VERSION ""

NS_ :

BS_:

BU_: Gen AF01A
VAL_TABLE_ FUNCTION_SWITCH 1 "close" 0 "open" ;
VAL_TABLE_ Status_Bottom_HLB 3 "Invalid signal" 2 "defined by oncoming vehicle" 1 "defined by preceding vehicle" 0 "No object detected" ;

BO_ 3221225472 VECTOR__INDEPENDENT_SIG_MSG: 0 Vector__XXX
 SG_ CAN_TX_ACTIVE_FAULT_3 : 0|8@0+ (1,0) [0|0] "" Vector__XXX
 SG_ New_Signal_1961 : 0|8@1+ (1,0) [0|0] "" Vector__XXX
 SG_ CAN_TX_TRACK_WIDTH : 0|8@1- (1,0) [0|0] "" Vector__XXX
 SG_ CAN_TX_TRACK_WIDTH : 0|8@1- (1,0) [0|0] "" Vector__XXX
 SG_ CAN_TX_TRACK_WIDTH : 0|8@1- (1,0) [0|0] "" Vector__XXX
 SG_ CAN_TX_TRACK_WIDTH : 0|8@1- (1,0) [0|0] "" Vector__XXX
 SG_ CAN_TX_TRACK_WIDTH : 0|8@1- (1,0) [0|0] "" Vector__XXX
 SG_ CAN_TX_TRACK_WIDTH : 0|8@1- (1,0) [0|0] "" Vector__XXX
 SG_ CAN_TX_TRACK_WIDTH : 0|8@1- (1,0) [0|0] "" Vector__XXX
 SG_ CAN_TX_TRACK_WIDTH : 0|8@1- (1,0) [0|0] "" Vector__XXX
 SG_ CAN_TX_TRACK_STATUS : 0|8@1- (1,0) [0|0] "" Vector__XXX
 SG_ CAN_TX_TRACK_STATUS : 0|8@1- (1,0) [0|0] "" Vector__XXX
 SG_ CAN_TX_TRACK_STATUS : 0|8@1- (1,0) [0|0] "" Vector__XXX
 SG_ CAN_TX_TRACK_STATUS : 0|8@1- (1,0) [0|0] "" Vector__XXX
 SG_ CAN_TX_TRACK_STATUS : 0|8@1- (1,0) [0|0] "" Vector__XXX
 SG_ New_Signal_1655 : 0|8@1+ (1,0) [0|0] "" Vector__XXX
 SG_ CAN_TX_TRACK_ROLLING_COUNT : 0|8@1- (1,0) [0|0] "" Vector__XXX
 SG_ CAN_TX_TRACK_ROLLING_COUNT : 0|8@1- (1,0) [0|0] "" Vector__XXX
 SG_ CAN_TX_TRACK_ROLLING_COUNT : 0|8@1- (1,0) [0|0] "" Vector__XXX
 SG_ CAN_TX_TRACK_ROLLING_COUNT : 0|8@1- (1,0) [0|0] "" Vector__XXX
 SG_ CAN_TX_TRACK_ROLLING_COUNT : 0|8@1- (1,0) [0|0] "" Vector__XXX
 SG_ CAN_TX_TRACK_ROLLING_COUNT : 0|8@1- (1,0) [0|0] "" Vector__XXX
 SG_ CAN_TX_TRACK_ROLLING_COUNT : 0|8@1- (1,0) [0|0] "" Vector__XXX
 SG_ CAN_TX_TRACK_ROLLING_COUNT : 0|8@1- (1,0) [0|0] "" Vector__XXX
 SG_ CAN_TX_TRACK_ROLLING_COUNT : 0|8@1- (1,0) [0|0] "" Vector__XXX
 SG_ CAN_TX_TRACK_ROLLING_COUNT : 0|8@1- (1,0) [0|0] "" Vector__XXX
 SG_ CAN_TX_TRACK_ROLLING_COUNT : 0|8@1- (1,0) [0|0] "" Vector__XXX
 SG_ New_Signal_1548 : 0|8@1+ (1,0) [0|0] "" Vector__XXX
 SG_ New_Signal_1513 : 0|8@1- (1,0) [0|0] "" Vector__XXX
 SG_ New_Signal_1502 : 0|8@1+ (1,0) [0|0] "" Vector__XXX
 SG_ CAN_TX_TRACK_RANGE_RATE : 0|8@1- (1,0) [0|0] "" Vector__XXX
 SG_ CAN_TX_TRACK_RANGE_RATE : 0|8@1- (1,0) [0|0] "" Vector__XXX
 SG_ CAN_TX_TRACK_RANGE_RATE : 0|8@1- (1,0) [0|0] "" Vector__XXX
 SG_ CAN_TX_TRACK_RANGE_RATE : 0|8@1- (1,0) [0|0] "" Vector__XXX
 SG_ CAN_TX_TRACK_RANGE_ACCEL : 0|8@1- (1,0) [0|0] "" Vector__XXX
 SG_ New_Signal_1353 : 0|8@1- (1,0) [0|0] "" Vector__XXX
 SG_ CAN_TX_TRACK_RANGE_ACCEL : 0|8@1- (1,0) [0|0] "" Vector__XXX
 SG_ CAN_TX_TRACK_RANGE_ACCEL : 0|8@1- (1,0) [0|0] "" Vector__XXX
 SG_ CAN_TX_TRACK_RANGE_ACCEL : 0|8@1- (1,0) [0|0] "" Vector__XXX
 SG_ CAN_TX_TRACK_RANGE_ACCEL : 0|8@1- (1,0) [0|0] "" Vector__XXX
 SG_ CAN_TX_TRACK_RANGE : 0|8@1- (1,0) [0|0] "" Vector__XXX
 SG_ CAN_TX_TRACK_RANGE : 0|8@1- (1,0) [0|0] "" Vector__XXX
 SG_ CAN_TX_TRACK_RANGE : 0|8@1- (1,0) [0|0] "" Vector__XXX
 SG_ CAN_TX_TRACK_RANGE : 0|8@1- (1,0) [0|0] "" Vector__XXX
 SG_ New_Signal_1169 : 0|8@1+ (1,0) [0|0] "" Vector__XXX
 SG_ New_Signal_1161 : 0|8@1+ (1,0) [0|0] "" Vector__XXX
 SG_ CAN_TX_TRACK_ONCOMING : 0|8@1- (1,0) [0|0] "" Vector__XXX
 SG_ New_Signal_1037 : 0|8@1+ (1,0) [0|0] "" Vector__XXX
 SG_ New_Signal_1023 : 0|8@1+ (1,0) [0|0] "" Vector__XXX
 SG_ New_Signal_1013 : 0|8@1+ (1,0) [0|0] "" Vector__XXX
 SG_ CAN_TX_TRACK_MED_RANGE_MODE : 0|8@1- (1,0) [0|0] "" Vector__XXX
 SG_ CAN_TX_TRACK_MED_RANGE_MODE : 0|8@1- (1,0) [0|0] "" Vector__XXX
 SG_ New_Signal_792 : 0|8@1+ (1,0) [0|0] "" Vector__XXX
 SG_ New_Signal_791 : 0|8@1+ (1,0) [0|0] "" Vector__XXX
 SG_ New_Signal_790 : 0|8@1+ (1,0) [0|0] "" Vector__XXX
 SG_ New_Signal_789 : 0|8@1+ (1,0) [0|0] "" Vector__XXX
 SG_ New_Signal_788 : 0|8@1+ (1,0) [0|0] "" Vector__XXX
 SG_ New_Signal_787 : 0|8@1+ (1,0) [0|0] "" Vector__XXX
 SG_ New_Signal_786 : 0|8@1+ (1,0) [0|0] "" Vector__XXX
 SG_ New_Signal_785 : 0|8@1+ (1,0) [0|0] "" Vector__XXX
 SG_ New_Signal_784 : 0|8@1+ (1,0) [0|0] "" Vector__XXX
 SG_ New_Signal_783 : 0|8@1+ (1,0) [0|0] "" Vector__XXX
 SG_ New_Signal_782 : 0|8@1+ (1,0) [0|0] "" Vector__XXX
 SG_ New_Signal_781 : 0|8@1+ (1,0) [0|0] "" Vector__XXX
 SG_ New_Signal_780 : 0|8@1+ (1,0) [0|0] "" Vector__XXX
 SG_ New_Signal_779 : 0|8@1+ (1,0) [0|0] "" Vector__XXX
 SG_ New_Signal_778 : 0|8@1+ (1,0) [0|0] "" Vector__XXX
 SG_ New_Signal_777 : 0|8@1+ (1,0) [0|0] "" Vector__XXX
 SG_ New_Signal_776 : 0|8@1+ (1,0) [0|0] "" Vector__XXX
 SG_ New_Signal_775 : 0|8@1+ (1,0) [0|0] "" Vector__XXX
 SG_ New_Signal_774 : 0|8@1+ (1,0) [0|0] "" Vector__XXX
 SG_ New_Signal_773 : 0|8@1+ (1,0) [0|0] "" Vector__XXX
 SG_ New_Signal_772 : 0|8@1+ (1,0) [0|0] "" Vector__XXX
 SG_ New_Signal_771 : 0|8@1+ (1,0) [0|0] "" Vector__XXX
 SG_ New_Signal_770 : 0|8@1+ (1,0) [0|0] "" Vector__XXX
 SG_ New_Signal_769 : 0|8@1+ (1,0) [0|0] "" Vector__XXX
 SG_ New_Signal_768 : 0|8@1+ (1,0) [0|0] "" Vector__XXX
 SG_ New_Signal_767 : 0|8@1+ (1,0) [0|0] "" Vector__XXX
 SG_ New_Signal_766 : 0|8@1+ (1,0) [0|0] "" Vector__XXX
 SG_ New_Signal_765 : 0|8@1+ (1,0) [0|0] "" Vector__XXX
 SG_ New_Signal_764 : 0|8@1+ (1,0) [0|0] "" Vector__XXX
 SG_ New_Signal_763 : 0|8@1+ (1,0) [0|0] "" Vector__XXX
 SG_ New_Signal_762 : 0|8@1+ (1,0) [0|0] "" Vector__XXX
 SG_ New_Signal_761 : 0|8@1+ (1,0) [0|0] "" Vector__XXX
 SG_ New_Signal_760 : 0|8@1+ (1,0) [0|0] "" Vector__XXX
 SG_ New_Signal_759 : 0|8@1+ (1,0) [0|0] "" Vector__XXX
 SG_ New_Signal_758 : 0|8@1+ (1,0) [0|0] "" Vector__XXX
 SG_ New_Signal_757 : 0|8@1+ (1,0) [0|0] "" Vector__XXX
 SG_ New_Signal_756 : 0|8@1+ (1,0) [0|0] "" Vector__XXX
 SG_ New_Signal_755 : 0|8@1+ (1,0) [0|0] "" Vector__XXX
 SG_ New_Signal_754 : 0|8@1+ (1,0) [0|0] "" Vector__XXX
 SG_ New_Signal_753 : 0|8@1+ (1,0) [0|0] "" Vector__XXX
 SG_ New_Signal_752 : 0|8@1+ (1,0) [0|0] "" Vector__XXX
 SG_ New_Signal_751 : 0|8@1+ (1,0) [0|0] "" Vector__XXX
 SG_ New_Signal_750 : 0|8@1+ (1,0) [0|0] "" Vector__XXX
 SG_ New_Signal_749 : 0|8@1+ (1,0) [0|0] "" Vector__XXX
 SG_ New_Signal_748 : 0|8@1+ (1,0) [0|0] "" Vector__XXX
 SG_ New_Signal_747 : 0|8@1+ (1,0) [0|0] "" Vector__XXX
 SG_ New_Signal_746 : 0|8@1+ (1,0) [0|0] "" Vector__XXX
 SG_ New_Signal_745 : 0|8@1+ (1,0) [0|0] "" Vector__XXX
 SG_ New_Signal_744 : 0|8@1+ (1,0) [0|0] "" Vector__XXX
 SG_ New_Signal_743 : 0|8@1+ (1,0) [0|0] "" Vector__XXX
 SG_ New_Signal_742 : 0|8@1+ (1,0) [0|0] "" Vector__XXX
 SG_ New_Signal_741 : 0|8@1+ (1,0) [0|0] "" Vector__XXX
 SG_ New_Signal_740 : 0|8@1+ (1,0) [0|0] "" Vector__XXX
 SG_ New_Signal_739 : 0|8@1+ (1,0) [0|0] "" Vector__XXX
 SG_ New_Signal_738 : 0|8@1+ (1,0) [0|0] "" Vector__XXX
 SG_ New_Signal_737 : 0|8@1+ (1,0) [0|0] "" Vector__XXX
 SG_ New_Signal_736 : 0|8@1+ (1,0) [0|0] "" Vector__XXX
 SG_ New_Signal_735 : 0|8@1+ (1,0) [0|0] "" Vector__XXX
 SG_ New_Signal_734 : 0|8@1+ (1,0) [0|0] "" Vector__XXX
 SG_ New_Signal_733 : 0|8@1+ (1,0) [0|0] "" Vector__XXX
 SG_ New_Signal_732 : 0|8@1+ (1,0) [0|0] "" Vector__XXX
 SG_ New_Signal_731 : 0|8@1+ (1,0) [0|0] "" Vector__XXX
 SG_ New_Signal_730 : 0|8@1+ (1,0) [0|0] "" Vector__XXX
 SG_ New_Signal_729 : 0|8@1+ (1,0) [0|0] "" Vector__XXX
 SG_ CAN_TX_TRACK_GROUPING_CHANGED : 0|8@1- (1,0) [0|0] "" Vector__XXX
 SG_ New_Signal_663 : 0|8@1+ (1,0) [0|0] "" Vector__XXX
 SG_ New_Signal_662 : 0|8@1+ (1,0) [0|0] "" Vector__XXX
 SG_ New_Signal_661 : 0|8@1+ (1,0) [0|0] "" Vector__XXX
 SG_ New_Signal_660 : 0|8@1+ (1,0) [0|0] "" Vector__XXX
 SG_ New_Signal_659 : 0|8@1+ (1,0) [0|0] "" Vector__XXX
 SG_ New_Signal_658 : 0|8@1+ (1,0) [0|0] "" Vector__XXX
 SG_ New_Signal_657 : 0|8@1+ (1,0) [0|0] "" Vector__XXX
 SG_ New_Signal_656 : 0|8@1+ (1,0) [0|0] "" Vector__XXX
 SG_ New_Signal_655 : 0|8@1+ (1,0) [0|0] "" Vector__XXX
 SG_ New_Signal_654 : 0|8@1+ (1,0) [0|0] "" Vector__XXX
 SG_ New_Signal_653 : 0|8@1+ (1,0) [0|0] "" Vector__XXX
 SG_ New_Signal_652 : 0|8@1+ (1,0) [0|0] "" Vector__XXX
 SG_ New_Signal_651 : 0|8@1+ (1,0) [0|0] "" Vector__XXX
 SG_ New_Signal_650 : 0|8@1+ (1,0) [0|0] "" Vector__XXX
 SG_ New_Signal_649 : 0|8@1+ (1,0) [0|0] "" Vector__XXX
 SG_ New_Signal_648 : 0|8@1+ (1,0) [0|0] "" Vector__XXX
 SG_ New_Signal_647 : 0|8@1+ (1,0) [0|0] "" Vector__XXX
 SG_ New_Signal_646 : 0|8@1+ (1,0) [0|0] "" Vector__XXX
 SG_ New_Signal_645 : 0|8@1+ (1,0) [0|0] "" Vector__XXX
 SG_ New_Signal_644 : 0|8@1+ (1,0) [0|0] "" Vector__XXX
 SG_ New_Signal_643 : 0|8@1+ (1,0) [0|0] "" Vector__XXX
 SG_ New_Signal_642 : 0|8@1+ (1,0) [0|0] "" Vector__XXX
 SG_ New_Signal_641 : 0|8@1+ (1,0) [0|0] "" Vector__XXX
 SG_ New_Signal_640 : 0|8@1+ (1,0) [0|0] "" Vector__XXX
 SG_ New_Signal_639 : 0|8@1+ (1,0) [0|0] "" Vector__XXX
 SG_ New_Signal_638 : 0|8@1+ (1,0) [0|0] "" Vector__XXX
 SG_ New_Signal_637 : 0|8@1+ (1,0) [0|0] "" Vector__XXX
 SG_ New_Signal_636 : 0|8@1+ (1,0) [0|0] "" Vector__XXX
 SG_ New_Signal_635 : 0|8@1+ (1,0) [0|0] "" Vector__XXX
 SG_ New_Signal_634 : 0|8@1+ (1,0) [0|0] "" Vector__XXX
 SG_ New_Signal_633 : 0|8@1+ (1,0) [0|0] "" Vector__XXX
 SG_ New_Signal_632 : 0|8@1+ (1,0) [0|0] "" Vector__XXX
 SG_ New_Signal_631 : 0|8@1+ (1,0) [0|0] "" Vector__XXX
 SG_ New_Signal_630 : 0|8@1+ (1,0) [0|0] "" Vector__XXX
 SG_ New_Signal_629 : 0|8@1+ (1,0) [0|0] "" Vector__XXX
 SG_ New_Signal_628 : 0|8@1+ (1,0) [0|0] "" Vector__XXX
 SG_ New_Signal_627 : 0|8@1+ (1,0) [0|0] "" Vector__XXX
 SG_ New_Signal_626 : 0|8@1+ (1,0) [0|0] "" Vector__XXX
 SG_ New_Signal_625 : 0|8@1+ (1,0) [0|0] "" Vector__XXX
 SG_ New_Signal_624 : 0|8@1+ (1,0) [0|0] "" Vector__XXX
 SG_ New_Signal_623 : 0|8@1+ (1,0) [0|0] "" Vector__XXX
 SG_ New_Signal_622 : 0|8@1+ (1,0) [0|0] "" Vector__XXX
 SG_ New_Signal_621 : 0|8@1+ (1,0) [0|0] "" Vector__XXX
 SG_ New_Signal_620 : 0|8@1+ (1,0) [0|0] "" Vector__XXX
 SG_ New_Signal_619 : 0|8@1+ (1,0) [0|0] "" Vector__XXX
 SG_ New_Signal_618 : 0|8@1+ (1,0) [0|0] "" Vector__XXX
 SG_ New_Signal_617 : 0|8@1+ (1,0) [0|0] "" Vector__XXX
 SG_ New_Signal_616 : 0|8@1+ (1,0) [0|0] "" Vector__XXX
 SG_ New_Signal_615 : 0|8@1+ (1,0) [0|0] "" Vector__XXX
 SG_ New_Signal_614 : 0|8@1+ (1,0) [0|0] "" Vector__XXX
 SG_ New_Signal_613 : 0|8@1+ (1,0) [0|0] "" Vector__XXX
 SG_ New_Signal_612 : 0|8@1+ (1,0) [0|0] "" Vector__XXX
 SG_ New_Signal_611 : 0|8@1+ (1,0) [0|0] "" Vector__XXX
 SG_ New_Signal_610 : 0|8@1+ (1,0) [0|0] "" Vector__XXX
 SG_ New_Signal_609 : 0|8@1+ (1,0) [0|0] "" Vector__XXX
 SG_ New_Signal_608 : 0|8@1+ (1,0) [0|0] "" Vector__XXX
 SG_ New_Signal_607 : 0|8@1+ (1,0) [0|0] "" Vector__XXX
 SG_ New_Signal_606 : 0|8@1+ (1,0) [0|0] "" Vector__XXX
 SG_ New_Signal_605 : 0|8@1+ (1,0) [0|0] "" Vector__XXX
 SG_ New_Signal_604 : 0|8@1+ (1,0) [0|0] "" Vector__XXX
 SG_ New_Signal_603 : 0|8@1+ (1,0) [0|0] "" Vector__XXX
 SG_ New_Signal_602 : 0|8@1+ (1,0) [0|0] "" Vector__XXX
 SG_ New_Signal_601 : 0|8@1+ (1,0) [0|0] "" Vector__XXX
 SG_ New_Signal_600 : 0|8@1+ (1,0) [0|0] "" Vector__XXX
 SG_ New_Signal_599 : 0|8@1+ (1,0) [0|0] "" Vector__XXX
 SG_ CAN_TX_TRACK_ANGLE : 0|10@0- (0.1,0) [-51.2|51.1] "" Vector__XXX
 SG_ LDW_OFF : 0|8@1- (1,0) [0|0] "" Vector__XXX
 SG_ Error_code : 0|7@1+ (1,0) [0|0] "" Vector__XXX
 SG_ New_Signal_898 : 0|8@1+ (1,0) [0|0] "" Vector__XXX
 SG_ New_Signal_896 : 0|8@1+ (1,0) [0|0] "" Vector__XXX
 SG_ New_Signal_895 : 0|8@1+ (1,0) [0|0] "" Vector__XXX
 SG_ New_Signal_894 : 0|8@1+ (1,0) [0|0] "" Vector__XXX
 SG_ New_Signal_893 : 0|8@1+ (1,0) [0|0] "" Vector__XXX
 SG_ New_Signal_892 : 0|8@1+ (1,0) [0|0] "" Vector__XXX
 SG_ New_Signal_891 : 0|8@1+ (1,0) [0|0] "" Vector__XXX
 SG_ New_Signal_890 : 0|8@1+ (1,0) [0|0] "" Vector__XXX
 SG_ New_Signal_889 : 0|8@1+ (1,0) [0|0] "" Vector__XXX
 SG_ New_Signal_888 : 0|8@1+ (1,0) [0|0] "" Vector__XXX
 SG_ New_Signal_887 : 0|8@1+ (1,0) [0|0] "" Vector__XXX
 SG_ New_Signal_885 : 0|8@1+ (1,0) [0|0] "" Vector__XXX
 SG_ New_Signal_883 : 0|8@1+ (1,0) [0|0] "" Vector__XXX
 SG_ New_Signal_882 : 0|8@1+ (1,0) [0|0] "" Vector__XXX
 SG_ New_Signal_881 : 0|8@1+ (1,0) [0|0] "" Vector__XXX
 SG_ New_Signal_880 : 0|8@1+ (1,0) [0|0] "" Vector__XXX
 SG_ New_Signal_879 : 0|8@1+ (1,0) [0|0] "" Vector__XXX
 SG_ New_Signal_878 : 0|8@1+ (1,0) [0|0] "" Vector__XXX
 SG_ New_Signal_877 : 0|8@1+ (1,0) [0|0] "" Vector__XXX
 SG_ New_Signal_876 : 0|8@1+ (1,0) [0|0] "" Vector__XXX
 SG_ New_Signal_875 : 0|8@1+ (1,0) [0|0] "" Vector__XXX
 SG_ New_Signal_874 : 0|8@1+ (1,0) [0|0] "" Vector__XXX
 SG_ New_Signal_860 : 0|8@1+ (1,0) [0|0] "" Vector__XXX
 SG_ New_Signal_859 : 0|8@1+ (1,0) [0|0] "" Vector__XXX
 SG_ New_Signal_858 : 0|8@1+ (1,0) [0|0] "" Vector__XXX
 SG_ CAN_TX_SW_VERSION_DSP : 0|16@0+ (1,0) [0|0] "" Vector__XXX

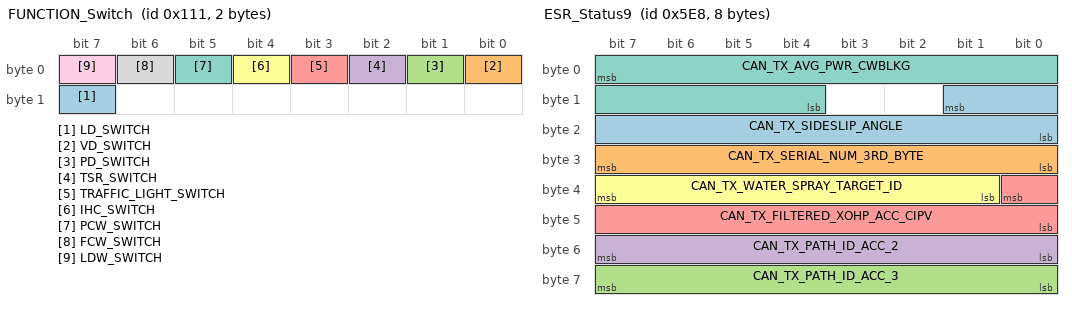
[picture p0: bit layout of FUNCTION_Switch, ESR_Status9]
BO_ 273 FUNCTION_Switch: 2 Vector__XXX
 SG_ LD_SWITCH : 15|1@0+ (1,0) [0|0] ""  AF01A
 SG_ VD_SWITCH : 0|1@0+ (1,0) [0|0] ""  AF01A
 SG_ PD_SWITCH : 1|1@0+ (1,0) [0|0] ""  AF01A
 SG_ TSR_SWITCH : 2|1@0+ (1,0) [0|0] ""  AF01A
 SG_ TRAFFIC_LIGHT_SWITCH : 3|1@0+ (1,0) [0|0] ""  AF01A
 SG_ IHC_SWITCH : 4|1@0+ (1,0) [0|0] ""  AF01A
 SG_ PCW_SWITCH : 5|1@0+ (1,0) [0|0] ""  AF01A
 SG_ FCW_SWITCH : 6|1@0+ (1,0) [0|0] ""  AF01A
 SG_ LDW_SWITCH : 7|1@0+ (1,0) [0|0] ""  AF01A

BO_ 819 TIMESTAMP: 8 AF01A
 SG_ TIME_STAMP : 7|64@0+ (1,0) [0|1.84467440737096E+019] "" Vector__XXX

BO_ 1512 ESR_Status9: 8 Vector__XXX
 SG_ CAN_TX_SIDESLIP_ANGLE : 9|10@0- (0.125,0) [-64|63.875] "deg"  AF01A
 SG_ CAN_TX_SERIAL_NUM_3RD_BYTE : 31|8@0+ (1,0) [0|0] ""  AF01A
 SG_ CAN_TX_PATH_ID_ACC_3 : 63|8@0+ (1,0) [0|64] ""  AF01A
 SG_ CAN_TX_PATH_ID_ACC_2 : 55|8@0+ (1,0) [0|64] ""  AF01A
 SG_ CAN_TX_FILTERED_XOHP_ACC_CIPV : 32|9@0- (0.03125,0) [0|7.96875] ""  AF01A
 SG_ CAN_TX_WATER_SPRAY_TARGET_ID : 39|7@0+ (1,0) [0|64] ""  AF01A
 SG_ CAN_TX_AVG_PWR_CWBLKG : 7|12@0+ (1,0) [0|0] ""  AF01A

BO_ 1511 ESR_Status8: 8 Vector__XXX
 SG_ CAN_TX_HISTORY_FAULT_7 : 63|8@0+ (1,0) [0|0] ""  AF01A
 SG_ CAN_TX_HISTORY_FAULT_6 : 55|8@0+ (1,0) [0|0] ""  AF01A
 SG_ CAN_TX_HISTORY_FAULT_5 : 47|8@0+ (1,0) [0|0] ""  AF01A
 SG_ CAN_TX_HISTORY_FAULT_4 : 32|8@1- (1,0) [0|0] ""  AF01A
 SG_ CAN_TX_HISTORY_FAULT_3 : 31|8@0+ (1,0) [0|0] ""  AF01A
 SG_ CAN_TX_HISTORY_FAULT_2 : 23|8@0+ (1,0) [0|0] ""  AF01A
 SG_ CAN_TX_HISTORY_FAULT_1 : 15|8@0+ (1,0) [0|0] ""  AF01A
 SG_ CAN_TX_HISTORY_FAULT_0 : 7|8@0+ (1,0) [0|0] ""  AF01A

BO_ 1510 ESR_Status7: 8 Vector__XXX
 SG_ CAN_TX_ACTIVE_FAULT_7 : 63|8@0+ (1,0) [0|0] ""  AF01A
 SG_ CAN_TX_ACTIVE_FAULT_6 : 55|8@0+ (1,0) [0|0] ""  AF01A
 SG_ CAN_TX_ACTIVE_FAULT_5 : 47|8@0+ (1,0) [0|0] ""  AF01A
 SG_ CAN_TX_ACTIVE_FAULT_4 : 39|8@0+ (1,0) [0|0] ""  AF01A
 SG_ CAN_TX_ACTIVE_FAULT_3 : 31|8@0+ (1,0) [0|0] ""  AF01A
 SG_ CAN_TX_ACTIVE_FAULT_2 : 23|8@0+ (1,0) [0|0] ""  AF01A
 SG_ CAN_TX_ACTIVE_FAULT_1 : 15|8@0+ (1,0) [0|0] ""  AF01A
 SG_ CAN_TX_ACTIVE_FAULT_0 : 7|8@0+ (1,0) [0|0] ""  AF01A

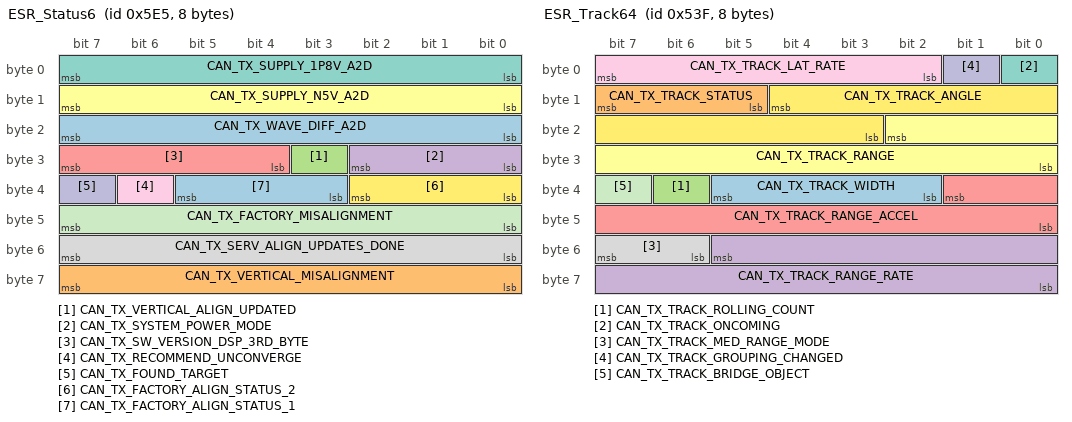
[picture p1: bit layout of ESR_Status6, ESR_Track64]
BO_ 1509 ESR_Status6: 8 Vector__XXX
 SG_ CAN_TX_WAVE_DIFF_A2D : 23|8@0+ (1,0) [0|0] ""  AF01A
 SG_ CAN_TX_VERTICAL_MISALIGNMENT : 63|8@0- (0.0625,0) [0|6] ""  AF01A
 SG_ CAN_TX_VERTICAL_ALIGN_UPDATED : 27|1@0+ (1,0) [0|0] ""  AF01A
 SG_ CAN_TX_SYSTEM_POWER_MODE : 26|3@0+ (1,0) [0|0] ""  AF01A
 SG_ CAN_TX_SW_VERSION_DSP_3RD_BYTE : 31|4@0+ (1,0) [0|0] ""  AF01A
 SG_ CAN_TX_SUPPLY_N5V_A2D : 15|8@0+ (1,0) [0|0] ""  AF01A
 SG_ CAN_TX_SUPPLY_1P8V_A2D : 7|8@0+ (1,0) [0|0] ""  AF01A
 SG_ CAN_TX_SERV_ALIGN_UPDATES_DONE : 55|8@0+ (1,0) [0|255] ""  AF01A
 SG_ CAN_TX_RECOMMEND_UNCONVERGE : 38|1@0+ (1,0) [0|0] ""  AF01A
 SG_ CAN_TX_FOUND_TARGET : 39|1@0+ (1,0) [0|0] ""  AF01A
 SG_ CAN_TX_FACTORY_MISALIGNMENT : 47|8@0- (0.0625,0) [-5|5] ""  AF01A
 SG_ CAN_TX_FACTORY_ALIGN_STATUS_2 : 34|3@0+ (1,0) [0|5] ""  AF01A
 SG_ CAN_TX_FACTORY_ALIGN_STATUS_1 : 37|3@0+ (1,0) [0|5] ""  AF01A

BO_ 1508 ESR_Status5: 8 Vector__XXX
 SG_ CAN_TX_TEMP2_A2D : 31|8@0+ (1,0) [0|0] ""  AF01A
 SG_ CAN_TX_TEMP1_A2D : 23|8@0+ (1,0) [0|0] ""  AF01A
 SG_ CAN_TX_SWBATT_A2D : 7|8@0+ (1,0) [0|0] ""  AF01A
 SG_ CAN_TX_SUPPLY_5VDX_A2D : 47|8@0+ (1,0) [0|0] ""  AF01A
 SG_ CAN_TX_SUPPLY_5VA_A2D : 39|8@0+ (1,0) [0|0] ""  AF01A
 SG_ CAN_TX_SUPPLY_3P3V_A2D : 55|8@0+ (1,0) [0|0] ""  AF01A
 SG_ CAN_TX_SUPPLY_10V_A2D : 63|8@0+ (1,0) [0|0] ""  AF01A
 SG_ CAN_TX_IGNP_A2D : 15|8@0+ (1,0) [0|0] ""  AF01A

BO_ 1343 ESR_Track64: 8 Vector__XXX
 SG_ CAN_TX_TRACK_WIDTH : 37|4@0+ (0.5,0) [0|7.5] "m"  AF01A
 SG_ CAN_TX_TRACK_STATUS : 15|3@0+ (1,0) [0|7] ""  AF01A
 SG_ CAN_TX_TRACK_ROLLING_COUNT : 38|1@0+ (1,0) [0|1] ""  AF01A
 SG_ CAN_TX_TRACK_RANGE_RATE : 53|14@0- (0.01,0) [-81.92|81.91] "m/s"  AF01A
 SG_ CAN_TX_TRACK_RANGE_ACCEL : 33|10@0- (0.05,0) [-25.6|25.55] "m/s/s"  AF01A
 SG_ CAN_TX_TRACK_RANGE : 18|11@0+ (0.1,0) [0|204.7] "m"  AF01A
 SG_ CAN_TX_TRACK_ONCOMING : 0|1@0+ (1,0) [0|0] ""  AF01A
 SG_ CAN_TX_TRACK_MED_RANGE_MODE : 55|2@0+ (1,0) [0|3] ""  AF01A
 SG_ CAN_TX_TRACK_LAT_RATE : 7|6@0- (0.25,0) [-8|7.75] ""  AF01A
 SG_ CAN_TX_TRACK_GROUPING_CHANGED : 1|1@0+ (1,0) [0|0] ""  AF01A
 SG_ CAN_TX_TRACK_BRIDGE_OBJECT : 39|1@0+ (1,0) [0|0] ""  AF01A
 SG_ CAN_TX_TRACK_ANGLE : 12|10@0- (0.1,0) [-51.2|51.1] "deg"  AF01A

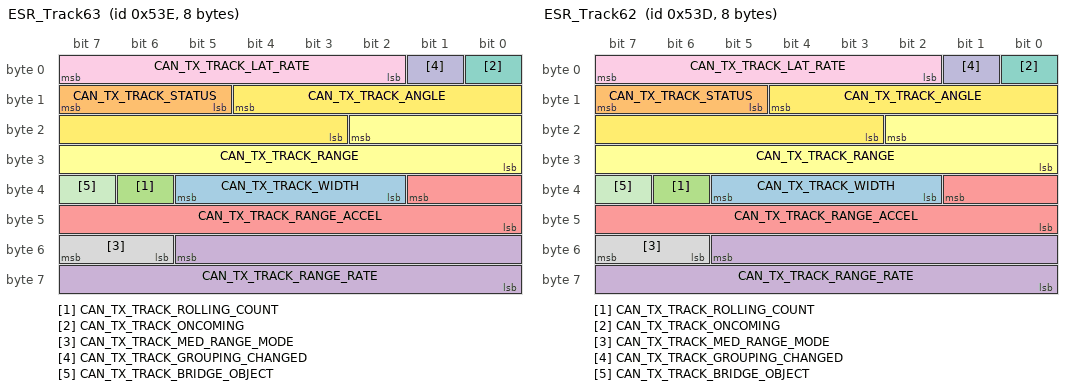
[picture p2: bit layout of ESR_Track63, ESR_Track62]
BO_ 1342 ESR_Track63: 8 Vector__XXX
 SG_ CAN_TX_TRACK_WIDTH : 37|4@0+ (0.5,0) [0|7.5] "m"  AF01A
 SG_ CAN_TX_TRACK_STATUS : 15|3@0+ (1,0) [0|7] ""  AF01A
 SG_ CAN_TX_TRACK_ROLLING_COUNT : 38|1@0+ (1,0) [0|1] ""  AF01A
 SG_ CAN_TX_TRACK_RANGE_RATE : 53|14@0- (0.01,0) [-81.92|81.91] "m/s"  AF01A
 SG_ CAN_TX_TRACK_RANGE_ACCEL : 33|10@0- (0.05,0) [-25.6|25.55] "m/s/s"  AF01A
 SG_ CAN_TX_TRACK_RANGE : 18|11@0+ (0.1,0) [0|204.7] "m"  AF01A
 SG_ CAN_TX_TRACK_ONCOMING : 0|1@0+ (1,0) [0|0] ""  AF01A
 SG_ CAN_TX_TRACK_MED_RANGE_MODE : 55|2@0+ (1,0) [0|3] ""  AF01A
 SG_ CAN_TX_TRACK_LAT_RATE : 7|6@0- (0.25,0) [-8|7.75] ""  AF01A
 SG_ CAN_TX_TRACK_GROUPING_CHANGED : 1|1@0+ (1,0) [0|0] ""  AF01A
 SG_ CAN_TX_TRACK_BRIDGE_OBJECT : 39|1@0+ (1,0) [0|0] ""  AF01A
 SG_ CAN_TX_TRACK_ANGLE : 12|10@0- (0.1,0) [-51.2|51.1] "deg"  AF01A

BO_ 1341 ESR_Track62: 8 Vector__XXX
 SG_ CAN_TX_TRACK_WIDTH : 37|4@0+ (0.5,0) [0|7.5] "m"  AF01A
 SG_ CAN_TX_TRACK_STATUS : 15|3@0+ (1,0) [0|7] ""  AF01A
 SG_ CAN_TX_TRACK_ROLLING_COUNT : 38|1@0+ (1,0) [0|1] ""  AF01A
 SG_ CAN_TX_TRACK_RANGE_RATE : 53|14@0- (0.01,0) [-81.92|81.91] "m/s"  AF01A
 SG_ CAN_TX_TRACK_RANGE_ACCEL : 33|10@0- (0.05,0) [-25.6|25.55] "m/s/s"  AF01A
 SG_ CAN_TX_TRACK_RANGE : 18|11@0+ (0.1,0) [0|204.7] "m"  AF01A
 SG_ CAN_TX_TRACK_ONCOMING : 0|1@0+ (1,0) [0|0] ""  AF01A
 SG_ CAN_TX_TRACK_MED_RANGE_MODE : 55|2@0+ (1,0) [0|3] ""  AF01A
 SG_ CAN_TX_TRACK_LAT_RATE : 7|6@0- (0.25,0) [-8|7.75] ""  AF01A
 SG_ CAN_TX_TRACK_GROUPING_CHANGED : 1|1@0+ (1,0) [0|0] ""  AF01A
 SG_ CAN_TX_TRACK_BRIDGE_OBJECT : 39|1@0+ (1,0) [0|0] ""  AF01A
 SG_ CAN_TX_TRACK_ANGLE : 12|10@0- (0.1,0) [-51.2|51.1] "deg"  AF01A

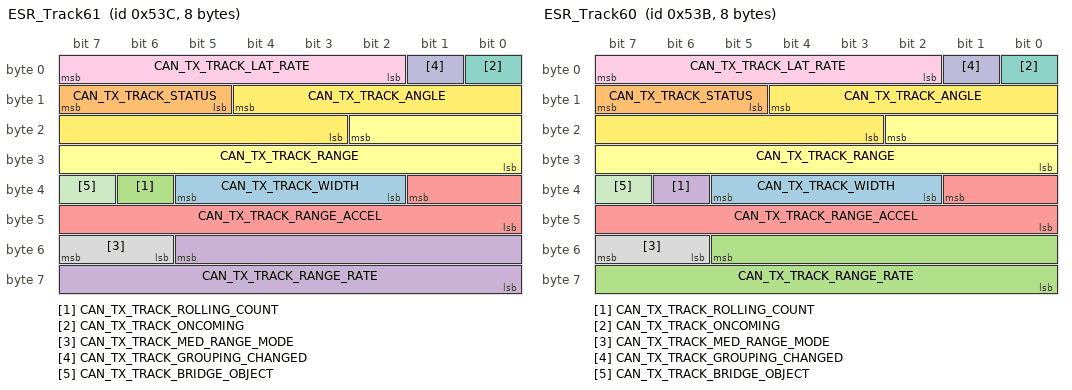
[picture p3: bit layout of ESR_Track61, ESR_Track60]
BO_ 1340 ESR_Track61: 8 Vector__XXX
 SG_ CAN_TX_TRACK_WIDTH : 37|4@0+ (0.5,0) [0|7.5] "m"  AF01A
 SG_ CAN_TX_TRACK_STATUS : 15|3@0+ (1,0) [0|7] ""  AF01A
 SG_ CAN_TX_TRACK_ROLLING_COUNT : 38|1@0+ (1,0) [0|1] ""  AF01A
 SG_ CAN_TX_TRACK_RANGE_RATE : 53|14@0- (0.01,0) [-81.92|81.91] "m/s"  AF01A
 SG_ CAN_TX_TRACK_RANGE_ACCEL : 33|10@0- (0.05,0) [-25.6|25.55] "m/s/s"  AF01A
 SG_ CAN_TX_TRACK_RANGE : 18|11@0+ (0.1,0) [0|204.7] "m"  AF01A
 SG_ CAN_TX_TRACK_ONCOMING : 0|1@0+ (1,0) [0|0] ""  AF01A
 SG_ CAN_TX_TRACK_MED_RANGE_MODE : 55|2@0+ (1,0) [0|3] ""  AF01A
 SG_ CAN_TX_TRACK_LAT_RATE : 7|6@0- (0.25,0) [-8|7.75] ""  AF01A
 SG_ CAN_TX_TRACK_GROUPING_CHANGED : 1|1@0+ (1,0) [0|0] ""  AF01A
 SG_ CAN_TX_TRACK_BRIDGE_OBJECT : 39|1@0+ (1,0) [0|0] ""  AF01A
 SG_ CAN_TX_TRACK_ANGLE : 12|10@0- (0.1,0) [-51.2|51.1] "deg"  AF01A

BO_ 1339 ESR_Track60: 8 Vector__XXX
 SG_ CAN_TX_TRACK_WIDTH : 37|4@0+ (0.5,0) [0|7.5] "m"  AF01A
 SG_ CAN_TX_TRACK_STATUS : 15|3@0+ (1,0) [0|7] ""  AF01A
 SG_ CAN_TX_TRACK_RANGE_RATE : 53|14@0- (0.01,0) [-81.92|81.91] "m/s"  AF01A
 SG_ CAN_TX_TRACK_ROLLING_COUNT : 38|1@0+ (1,0) [0|1] ""  AF01A
 SG_ CAN_TX_TRACK_RANGE_ACCEL : 33|10@0- (0.05,0) [-25.6|25.55] "m/s/s"  AF01A
 SG_ CAN_TX_TRACK_RANGE : 18|11@0+ (0.1,0) [0|204.7] "m"  AF01A
 SG_ CAN_TX_TRACK_ONCOMING : 0|1@0+ (1,0) [0|0] ""  AF01A
 SG_ CAN_TX_TRACK_MED_RANGE_MODE : 55|2@0+ (1,0) [0|3] ""  AF01A
 SG_ CAN_TX_TRACK_LAT_RATE : 7|6@0- (0.25,0) [-8|7.75] ""  AF01A
 SG_ CAN_TX_TRACK_GROUPING_CHANGED : 1|1@0+ (1,0) [0|0] ""  AF01A
 SG_ CAN_TX_TRACK_BRIDGE_OBJECT : 39|1@0+ (1,0) [0|0] ""  AF01A
 SG_ CAN_TX_TRACK_ANGLE : 12|10@0- (0.1,0) [-51.2|51.1] "deg"  AF01A

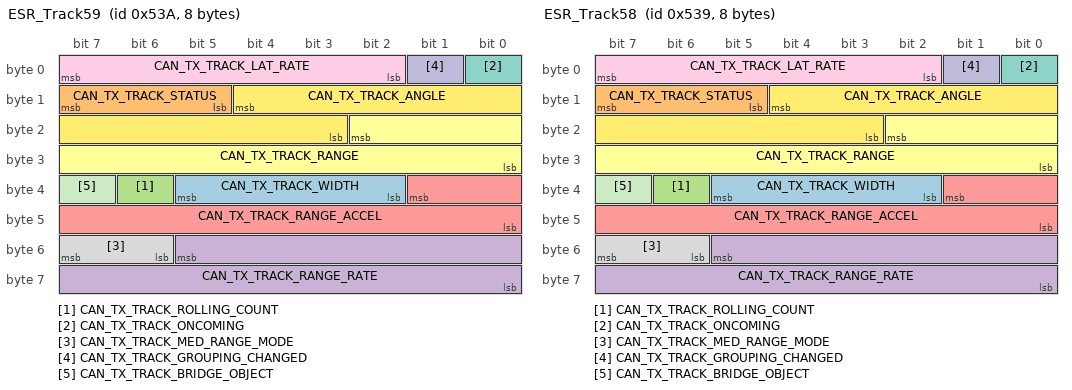
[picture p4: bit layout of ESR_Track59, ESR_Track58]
BO_ 1338 ESR_Track59: 8 Vector__XXX
 SG_ CAN_TX_TRACK_WIDTH : 37|4@0+ (0.5,0) [0|7.5] "m"  AF01A
 SG_ CAN_TX_TRACK_STATUS : 15|3@0+ (1,0) [0|7] ""  AF01A
 SG_ CAN_TX_TRACK_ROLLING_COUNT : 38|1@0+ (1,0) [0|1] ""  AF01A
 SG_ CAN_TX_TRACK_RANGE_RATE : 53|14@0- (0.01,0) [-81.92|81.91] "m/s"  AF01A
 SG_ CAN_TX_TRACK_RANGE_ACCEL : 33|10@0- (0.05,0) [-25.6|25.55] "m/s/s"  AF01A
 SG_ CAN_TX_TRACK_RANGE : 18|11@0+ (0.1,0) [0|204.7] "m"  AF01A
 SG_ CAN_TX_TRACK_ONCOMING : 0|1@0+ (1,0) [0|0] ""  AF01A
 SG_ CAN_TX_TRACK_MED_RANGE_MODE : 55|2@0+ (1,0) [0|3] ""  AF01A
 SG_ CAN_TX_TRACK_LAT_RATE : 7|6@0- (0.25,0) [-8|7.75] ""  AF01A
 SG_ CAN_TX_TRACK_GROUPING_CHANGED : 1|1@0+ (1,0) [0|0] ""  AF01A
 SG_ CAN_TX_TRACK_BRIDGE_OBJECT : 39|1@0+ (1,0) [0|0] ""  AF01A
 SG_ CAN_TX_TRACK_ANGLE : 12|10@0- (0.1,0) [-51.2|51.1] "deg"  AF01A

BO_ 1337 ESR_Track58: 8 Vector__XXX
 SG_ CAN_TX_TRACK_WIDTH : 37|4@0+ (0.5,0) [0|7.5] "m"  AF01A
 SG_ CAN_TX_TRACK_STATUS : 15|3@0+ (1,0) [0|7] ""  AF01A
 SG_ CAN_TX_TRACK_ROLLING_COUNT : 38|1@0+ (1,0) [0|1] ""  AF01A
 SG_ CAN_TX_TRACK_RANGE_RATE : 53|14@0- (0.01,0) [-81.92|81.91] "m/s"  AF01A
 SG_ CAN_TX_TRACK_RANGE_ACCEL : 33|10@0- (0.05,0) [-25.6|25.55] "m/s/s"  AF01A
 SG_ CAN_TX_TRACK_RANGE : 18|11@0+ (0.1,0) [0|204.7] "m"  AF01A
 SG_ CAN_TX_TRACK_ONCOMING : 0|1@0+ (1,0) [0|0] ""  AF01A
 SG_ CAN_TX_TRACK_MED_RANGE_MODE : 55|2@0+ (1,0) [0|3] ""  AF01A
 SG_ CAN_TX_TRACK_LAT_RATE : 7|6@0- (0.25,0) [-8|7.75] ""  AF01A
 SG_ CAN_TX_TRACK_GROUPING_CHANGED : 1|1@0+ (1,0) [0|0] ""  AF01A
 SG_ CAN_TX_TRACK_BRIDGE_OBJECT : 39|1@0+ (1,0) [0|0] ""  AF01A
 SG_ CAN_TX_TRACK_ANGLE : 12|10@0- (0.1,0) [-51.2|51.1] "deg"  AF01A

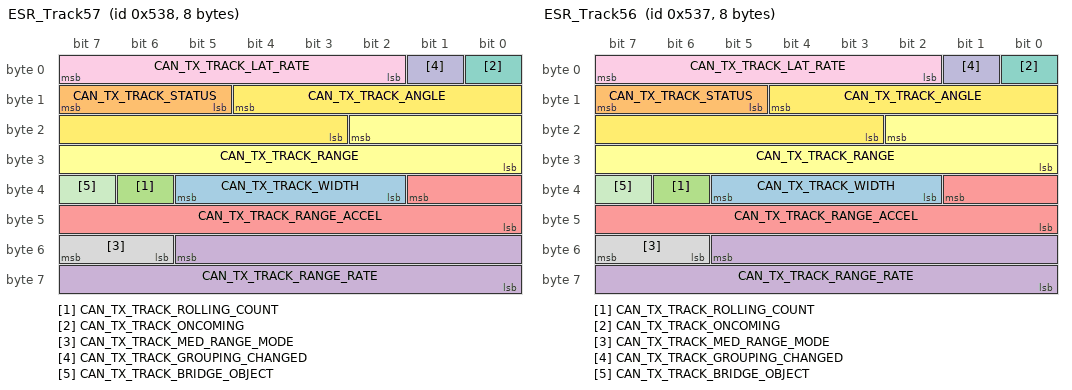
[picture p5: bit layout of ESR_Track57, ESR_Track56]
BO_ 1336 ESR_Track57: 8 Vector__XXX
 SG_ CAN_TX_TRACK_WIDTH : 37|4@0+ (0.5,0) [0|7.5] "m"  AF01A
 SG_ CAN_TX_TRACK_STATUS : 15|3@0+ (1,0) [0|7] ""  AF01A
 SG_ CAN_TX_TRACK_ROLLING_COUNT : 38|1@0+ (1,0) [0|1] ""  AF01A
 SG_ CAN_TX_TRACK_RANGE_RATE : 53|14@0- (0.01,0) [-81.92|81.91] "m/s"  AF01A
 SG_ CAN_TX_TRACK_RANGE_ACCEL : 33|10@0- (0.05,0) [-25.6|25.55] "m/s/s"  AF01A
 SG_ CAN_TX_TRACK_RANGE : 18|11@0+ (0.1,0) [0|204.7] "m"  AF01A
 SG_ CAN_TX_TRACK_ONCOMING : 0|1@0+ (1,0) [0|0] ""  AF01A
 SG_ CAN_TX_TRACK_MED_RANGE_MODE : 55|2@0+ (1,0) [0|3] ""  AF01A
 SG_ CAN_TX_TRACK_LAT_RATE : 7|6@0- (0.25,0) [-8|7.75] ""  AF01A
 SG_ CAN_TX_TRACK_GROUPING_CHANGED : 1|1@0+ (1,0) [0|0] ""  AF01A
 SG_ CAN_TX_TRACK_BRIDGE_OBJECT : 39|1@0+ (1,0) [0|0] ""  AF01A
 SG_ CAN_TX_TRACK_ANGLE : 12|10@0- (0.1,0) [-51.2|51.1] "deg"  AF01A

BO_ 1335 ESR_Track56: 8 Vector__XXX
 SG_ CAN_TX_TRACK_WIDTH : 37|4@0+ (0.5,0) [0|7.5] "m"  AF01A
 SG_ CAN_TX_TRACK_STATUS : 15|3@0+ (1,0) [0|7] ""  AF01A
 SG_ CAN_TX_TRACK_ROLLING_COUNT : 38|1@0+ (1,0) [0|1] ""  AF01A
 SG_ CAN_TX_TRACK_RANGE_RATE : 53|14@0- (0.01,0) [-81.92|81.91] "m/s"  AF01A
 SG_ CAN_TX_TRACK_RANGE_ACCEL : 33|10@0- (0.05,0) [-25.6|25.55] "m/s/s"  AF01A
 SG_ CAN_TX_TRACK_RANGE : 18|11@0+ (0.1,0) [0|204.7] "m"  AF01A
 SG_ CAN_TX_TRACK_ONCOMING : 0|1@0+ (1,0) [0|0] ""  AF01A
 SG_ CAN_TX_TRACK_MED_RANGE_MODE : 55|2@0+ (1,0) [0|3] ""  AF01A
 SG_ CAN_TX_TRACK_LAT_RATE : 7|6@0- (0.25,0) [-8|7.75] ""  AF01A
 SG_ CAN_TX_TRACK_GROUPING_CHANGED : 1|1@0+ (1,0) [0|0] ""  AF01A
 SG_ CAN_TX_TRACK_BRIDGE_OBJECT : 39|1@0+ (1,0) [0|0] ""  AF01A
 SG_ CAN_TX_TRACK_ANGLE : 12|10@0- (0.1,0) [-51.2|51.1] "deg"  AF01A

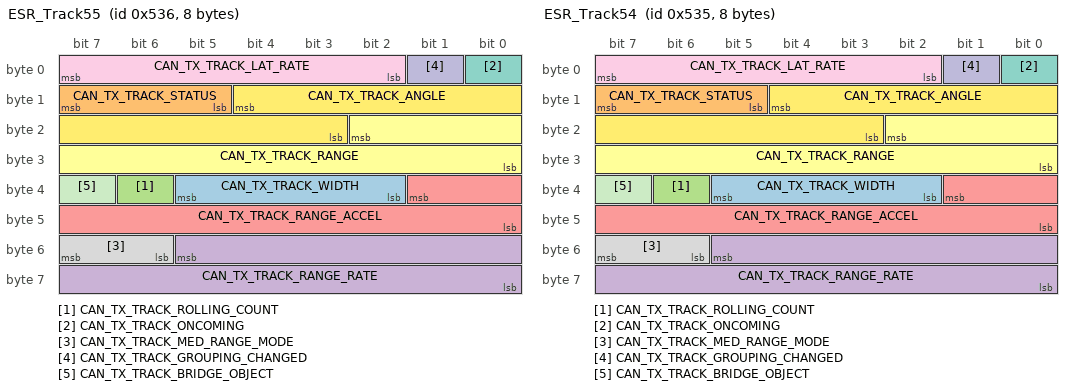
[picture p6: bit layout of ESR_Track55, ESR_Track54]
BO_ 1334 ESR_Track55: 8 Vector__XXX
 SG_ CAN_TX_TRACK_WIDTH : 37|4@0+ (0.5,0) [0|7.5] "m"  AF01A
 SG_ CAN_TX_TRACK_STATUS : 15|3@0+ (1,0) [0|7] ""  AF01A
 SG_ CAN_TX_TRACK_ROLLING_COUNT : 38|1@0+ (1,0) [0|1] ""  AF01A
 SG_ CAN_TX_TRACK_RANGE_RATE : 53|14@0- (0.01,0) [-81.92|81.91] "m/s"  AF01A
 SG_ CAN_TX_TRACK_RANGE_ACCEL : 33|10@0- (0.05,0) [-25.6|25.55] "m/s/s"  AF01A
 SG_ CAN_TX_TRACK_RANGE : 18|11@0+ (0.1,0) [0|204.7] "m"  AF01A
 SG_ CAN_TX_TRACK_ONCOMING : 0|1@0+ (1,0) [0|0] ""  AF01A
 SG_ CAN_TX_TRACK_MED_RANGE_MODE : 55|2@0+ (1,0) [0|3] ""  AF01A
 SG_ CAN_TX_TRACK_LAT_RATE : 7|6@0- (0.25,0) [-8|7.75] ""  AF01A
 SG_ CAN_TX_TRACK_GROUPING_CHANGED : 1|1@0+ (1,0) [0|0] ""  AF01A
 SG_ CAN_TX_TRACK_BRIDGE_OBJECT : 39|1@0+ (1,0) [0|0] ""  AF01A
 SG_ CAN_TX_TRACK_ANGLE : 12|10@0- (0.1,0) [-51.2|-51.2] "deg"  AF01A

BO_ 1333 ESR_Track54: 8 Vector__XXX
 SG_ CAN_TX_TRACK_WIDTH : 37|4@0+ (0.5,0) [0|7.5] "m"  AF01A
 SG_ CAN_TX_TRACK_STATUS : 15|3@0+ (1,0) [0|7] ""  AF01A
 SG_ CAN_TX_TRACK_ROLLING_COUNT : 38|1@0+ (1,0) [0|1] ""  AF01A
 SG_ CAN_TX_TRACK_RANGE_RATE : 53|14@0- (0.01,0) [-81.92|81.91] "m/s"  AF01A
 SG_ CAN_TX_TRACK_RANGE_ACCEL : 33|10@0- (0.05,0) [-25.6|25.55] "m/s/s"  AF01A
 SG_ CAN_TX_TRACK_RANGE : 18|11@0+ (0.1,0) [0|204.7] "m"  AF01A
 SG_ CAN_TX_TRACK_ONCOMING : 0|1@0+ (1,0) [0|0] ""  AF01A
 SG_ CAN_TX_TRACK_MED_RANGE_MODE : 55|2@0+ (1,0) [0|3] ""  AF01A
 SG_ CAN_TX_TRACK_LAT_RATE : 7|6@0- (0.25,0) [-8|7.75] ""  AF01A
 SG_ CAN_TX_TRACK_GROUPING_CHANGED : 1|1@0+ (1,0) [0|0] ""  AF01A
 SG_ CAN_TX_TRACK_BRIDGE_OBJECT : 39|1@0+ (1,0) [0|0] ""  AF01A
 SG_ CAN_TX_TRACK_ANGLE : 12|10@0- (0.1,0) [-51.2|51.1] "deg"  AF01A

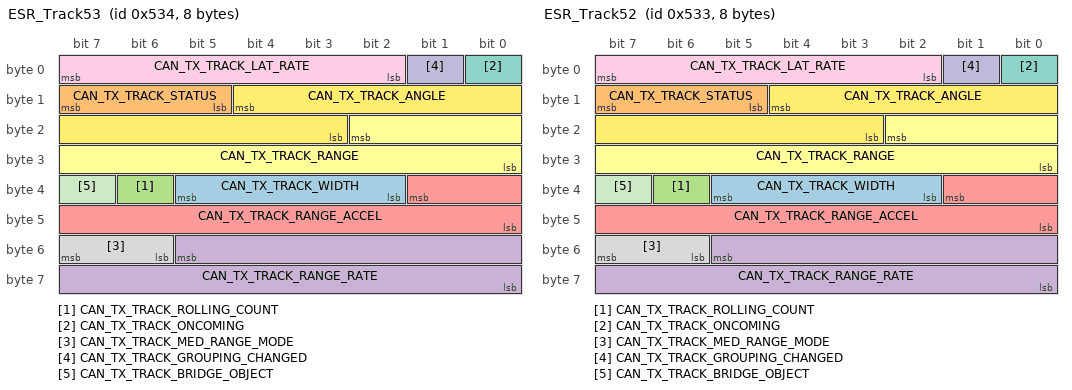
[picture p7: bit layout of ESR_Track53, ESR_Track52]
BO_ 1332 ESR_Track53: 8 Vector__XXX
 SG_ CAN_TX_TRACK_WIDTH : 37|4@0+ (0.5,0) [0|7.5] "m"  AF01A
 SG_ CAN_TX_TRACK_STATUS : 15|3@0+ (1,0) [0|7] ""  AF01A
 SG_ CAN_TX_TRACK_ROLLING_COUNT : 38|1@0+ (1,0) [0|1] ""  AF01A
 SG_ CAN_TX_TRACK_RANGE_RATE : 53|14@0- (0.01,0) [-81.92|81.91] "m/s"  AF01A
 SG_ CAN_TX_TRACK_RANGE_ACCEL : 33|10@0- (0.05,0) [-25.6|25.55] ""  AF01A
 SG_ CAN_TX_TRACK_RANGE : 18|11@0+ (0.1,0) [0|204.7] "m"  AF01A
 SG_ CAN_TX_TRACK_ONCOMING : 0|1@0+ (1,0) [0|0] ""  AF01A
 SG_ CAN_TX_TRACK_MED_RANGE_MODE : 55|2@0+ (1,0) [0|3] ""  AF01A
 SG_ CAN_TX_TRACK_LAT_RATE : 7|6@0- (0.25,0) [-8|7.75] ""  AF01A
 SG_ CAN_TX_TRACK_GROUPING_CHANGED : 1|1@0+ (1,0) [0|0] ""  AF01A
 SG_ CAN_TX_TRACK_BRIDGE_OBJECT : 39|1@0+ (1,0) [0|0] ""  AF01A
 SG_ CAN_TX_TRACK_ANGLE : 12|10@0- (0.1,0) [-51.2|51.1] "deg"  AF01A

BO_ 1331 ESR_Track52: 8 Vector__XXX
 SG_ CAN_TX_TRACK_WIDTH : 37|4@0+ (0.5,0) [0|7.5] "m"  AF01A
 SG_ CAN_TX_TRACK_STATUS : 15|3@0+ (1,0) [0|7] ""  AF01A
 SG_ CAN_TX_TRACK_ROLLING_COUNT : 38|1@0+ (1,0) [0|1] ""  AF01A
 SG_ CAN_TX_TRACK_RANGE_RATE : 53|14@0- (0.01,0) [-81.92|81.91] "m/s"  AF01A
 SG_ CAN_TX_TRACK_RANGE_ACCEL : 33|10@0- (0.05,0) [-25.6|25.55] "m/s/s"  AF01A
 SG_ CAN_TX_TRACK_RANGE : 18|11@0+ (0.1,0) [0|204.7] "m"  AF01A
 SG_ CAN_TX_TRACK_ONCOMING : 0|1@0+ (1,0) [0|0] ""  AF01A
 SG_ CAN_TX_TRACK_MED_RANGE_MODE : 55|2@0+ (1,0) [0|3] ""  AF01A
 SG_ CAN_TX_TRACK_LAT_RATE : 2|6@1- (0.25,0) [-8|7.75] ""  AF01A
 SG_ CAN_TX_TRACK_GROUPING_CHANGED : 1|1@0+ (1,0) [0|0] ""  AF01A
 SG_ CAN_TX_TRACK_BRIDGE_OBJECT : 39|1@0+ (1,0) [0|0] ""  AF01A
 SG_ CAN_TX_TRACK_ANGLE : 12|10@0- (0.1,0) [-51.2|51.1] "deg"  AF01A

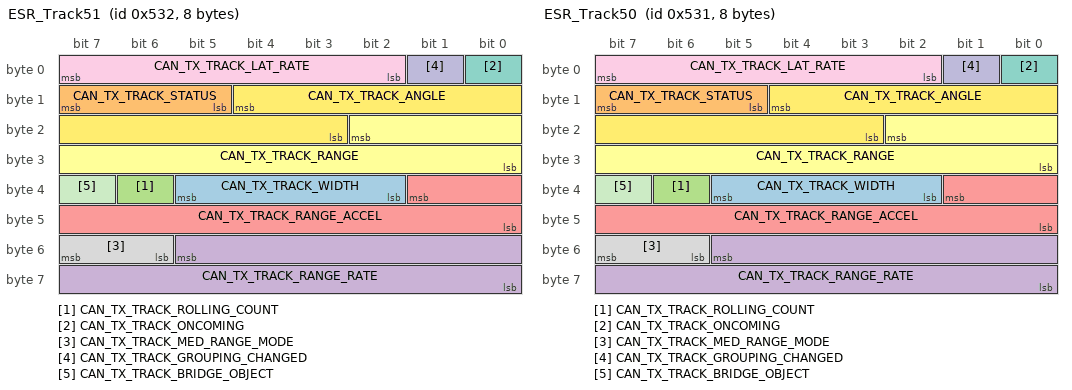
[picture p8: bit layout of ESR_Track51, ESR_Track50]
BO_ 1330 ESR_Track51: 8 Vector__XXX
 SG_ CAN_TX_TRACK_WIDTH : 37|4@0+ (0.5,0) [0|7.5] "m"  AF01A
 SG_ CAN_TX_TRACK_STATUS : 15|3@0+ (1,0) [0|7] ""  AF01A
 SG_ CAN_TX_TRACK_ROLLING_COUNT : 38|1@0+ (1,0) [0|1] ""  AF01A
 SG_ CAN_TX_TRACK_RANGE_RATE : 53|14@0- (0.01,0) [-81.92|81.91] "m/s"  AF01A
 SG_ CAN_TX_TRACK_RANGE_ACCEL : 33|10@0- (0.05,0) [-25.6|25.55] "m/s/s"  AF01A
 SG_ CAN_TX_TRACK_RANGE : 18|11@0+ (0.1,0) [0|204.7] "m"  AF01A
 SG_ CAN_TX_TRACK_ONCOMING : 0|1@0+ (1,0) [0|0] ""  AF01A
 SG_ CAN_TX_TRACK_MED_RANGE_MODE : 55|2@0+ (1,0) [0|3] ""  AF01A
 SG_ CAN_TX_TRACK_LAT_RATE : 7|6@0- (0.25,0) [-8|7.75] ""  AF01A
 SG_ CAN_TX_TRACK_GROUPING_CHANGED : 1|1@0+ (1,0) [0|0] ""  AF01A
 SG_ CAN_TX_TRACK_BRIDGE_OBJECT : 39|1@0+ (1,0) [0|0] ""  AF01A
 SG_ CAN_TX_TRACK_ANGLE : 12|10@0- (0.1,0) [-51.2|-51.2] "deg"  AF01A

BO_ 1329 ESR_Track50: 8 Vector__XXX
 SG_ CAN_TX_TRACK_WIDTH : 37|4@0+ (0.5,0) [0|7.5] "m"  AF01A
 SG_ CAN_TX_TRACK_STATUS : 15|3@0+ (1,0) [0|7] ""  AF01A
 SG_ CAN_TX_TRACK_ROLLING_COUNT : 38|1@0+ (1,0) [0|1] ""  AF01A
 SG_ CAN_TX_TRACK_RANGE_RATE : 53|14@0- (0.01,0) [-81.92|81.91] "m/s"  AF01A
 SG_ CAN_TX_TRACK_RANGE_ACCEL : 33|10@0- (0.05,0) [-25.6|25.55] "m/s/s"  AF01A
 SG_ CAN_TX_TRACK_RANGE : 18|11@0+ (0.1,0) [0|204.7] "m"  AF01A
 SG_ CAN_TX_TRACK_ONCOMING : 0|1@0+ (1,0) [0|0] ""  AF01A
 SG_ CAN_TX_TRACK_MED_RANGE_MODE : 55|2@0+ (1,0) [0|3] ""  AF01A
 SG_ CAN_TX_TRACK_LAT_RATE : 7|6@0- (0.25,0) [-8|7.75] ""  AF01A
 SG_ CAN_TX_TRACK_GROUPING_CHANGED : 1|1@0+ (1,0) [0|0] ""  AF01A
 SG_ CAN_TX_TRACK_BRIDGE_OBJECT : 39|1@0+ (1,0) [0|0] ""  AF01A
 SG_ CAN_TX_TRACK_ANGLE : 12|10@0- (0.1,0) [-51.2|51.1] "deg"  AF01A

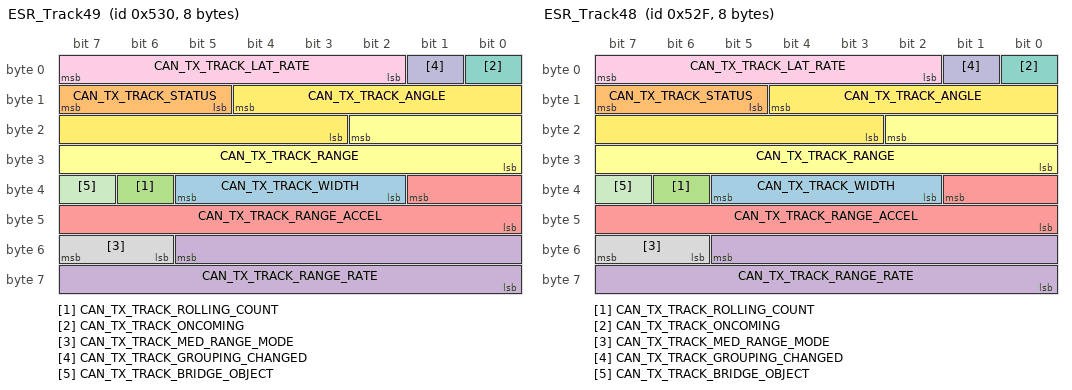
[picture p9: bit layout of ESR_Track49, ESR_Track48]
BO_ 1328 ESR_Track49: 8 Vector__XXX
 SG_ CAN_TX_TRACK_WIDTH : 37|4@0+ (0.5,0) [0|7.5] "m"  AF01A
 SG_ CAN_TX_TRACK_STATUS : 15|3@0+ (1,0) [0|7] ""  AF01A
 SG_ CAN_TX_TRACK_ROLLING_COUNT : 38|1@0+ (1,0) [0|1] ""  AF01A
 SG_ CAN_TX_TRACK_RANGE_RATE : 53|14@0- (0.01,0) [-81.92|81.91] "m/s"  AF01A
 SG_ CAN_TX_TRACK_RANGE_ACCEL : 33|10@0- (0.05,0) [-25.6|25.55] "m/s/s"  AF01A
 SG_ CAN_TX_TRACK_RANGE : 18|11@0+ (0.1,0) [0|0] "m"  AF01A
 SG_ CAN_TX_TRACK_ONCOMING : 0|1@0+ (1,0) [0|0] ""  AF01A
 SG_ CAN_TX_TRACK_MED_RANGE_MODE : 55|2@0+ (1,0) [0|3] ""  AF01A
 SG_ CAN_TX_TRACK_LAT_RATE : 7|6@0- (0.25,0) [-8|7.75] ""  AF01A
 SG_ CAN_TX_TRACK_GROUPING_CHANGED : 1|1@0+ (1,0) [0|0] ""  AF01A
 SG_ CAN_TX_TRACK_BRIDGE_OBJECT : 39|1@0+ (1,0) [0|0] ""  AF01A
 SG_ CAN_TX_TRACK_ANGLE : 12|10@0- (0.1,0) [-51.2|51.1] "deg"  AF01A

BO_ 1327 ESR_Track48: 8 Vector__XXX
 SG_ CAN_TX_TRACK_WIDTH : 37|4@0+ (0.5,0) [0|7.5] "m"  AF01A
 SG_ CAN_TX_TRACK_STATUS : 15|3@0+ (1,0) [0|7] ""  AF01A
 SG_ CAN_TX_TRACK_ROLLING_COUNT : 38|1@0+ (1,0) [0|1] ""  AF01A
 SG_ CAN_TX_TRACK_RANGE_RATE : 53|14@0- (0.01,0) [-81.92|81.91] "m/s"  AF01A
 SG_ CAN_TX_TRACK_RANGE_ACCEL : 33|10@0- (0.05,0) [-25.6|25.55] "m/s/s"  AF01A
 SG_ CAN_TX_TRACK_RANGE : 18|11@0+ (0.1,0) [0|204.7] "m"  AF01A
 SG_ CAN_TX_TRACK_ONCOMING : 0|1@0+ (1,0) [0|0] ""  AF01A
 SG_ CAN_TX_TRACK_MED_RANGE_MODE : 55|2@0+ (1,0) [0|3] ""  AF01A
 SG_ CAN_TX_TRACK_LAT_RATE : 7|6@0- (0.25,0) [-8|7.75] ""  AF01A
 SG_ CAN_TX_TRACK_GROUPING_CHANGED : 1|1@0+ (1,0) [0|0] ""  AF01A
 SG_ CAN_TX_TRACK_BRIDGE_OBJECT : 39|1@0+ (1,0) [0|0] ""  AF01A
 SG_ CAN_TX_TRACK_ANGLE : 12|10@0- (0.1,0) [-51.2|51.1] "deg"  AF01A

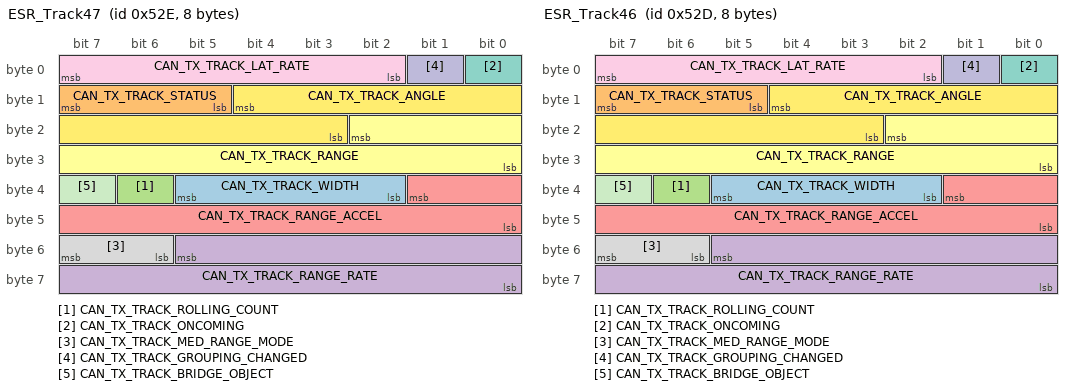
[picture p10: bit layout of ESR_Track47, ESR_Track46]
BO_ 1326 ESR_Track47: 8 Vector__XXX
 SG_ CAN_TX_TRACK_WIDTH : 37|4@0+ (0.5,0) [0|7.5] "m"  AF01A
 SG_ CAN_TX_TRACK_STATUS : 15|3@0+ (1,0) [0|7] ""  AF01A
 SG_ CAN_TX_TRACK_ROLLING_COUNT : 38|1@0+ (1,0) [0|1] ""  AF01A
 SG_ CAN_TX_TRACK_RANGE_RATE : 53|14@0- (0.01,0) [-81.92|81.91] "m/s"  AF01A
 SG_ CAN_TX_TRACK_RANGE_ACCEL : 33|10@0- (0.05,0) [-25.6|25.55] "m/s/s"  AF01A
 SG_ CAN_TX_TRACK_RANGE : 18|11@0+ (0.1,0) [0|204.7] "m"  AF01A
 SG_ CAN_TX_TRACK_ONCOMING : 0|1@0+ (1,0) [0|0] ""  AF01A
 SG_ CAN_TX_TRACK_MED_RANGE_MODE : 55|2@0+ (1,0) [0|3] ""  AF01A
 SG_ CAN_TX_TRACK_LAT_RATE : 7|6@0- (0.25,0) [-8|7.75] ""  AF01A
 SG_ CAN_TX_TRACK_GROUPING_CHANGED : 1|1@0+ (1,0) [0|0] ""  AF01A
 SG_ CAN_TX_TRACK_BRIDGE_OBJECT : 39|1@0+ (1,0) [0|0] ""  AF01A
 SG_ CAN_TX_TRACK_ANGLE : 12|10@0- (0.1,0) [-51.2|51.1] "deg"  AF01A

BO_ 1325 ESR_Track46: 8 Vector__XXX
 SG_ CAN_TX_TRACK_WIDTH : 37|4@0+ (0.5,0) [0|7.5] "m"  AF01A
 SG_ CAN_TX_TRACK_STATUS : 15|3@0+ (1,0) [0|7] ""  AF01A
 SG_ CAN_TX_TRACK_ROLLING_COUNT : 38|1@0+ (1,0) [0|1] ""  AF01A
 SG_ CAN_TX_TRACK_RANGE_RATE : 53|14@0- (0.01,0) [-81.92|81.91] "m/s"  AF01A
 SG_ CAN_TX_TRACK_RANGE_ACCEL : 33|10@0- (0.05,0) [-25.6|25.55] "m/s/s"  AF01A
 SG_ CAN_TX_TRACK_RANGE : 18|11@0+ (0.1,0) [0|204.7] "m"  AF01A
 SG_ CAN_TX_TRACK_ONCOMING : 0|1@0+ (1,0) [0|0] ""  AF01A
 SG_ CAN_TX_TRACK_MED_RANGE_MODE : 55|2@0+ (1,0) [0|3] ""  AF01A
 SG_ CAN_TX_TRACK_LAT_RATE : 7|6@0- (0.25,0) [-8|7.75] ""  AF01A
 SG_ CAN_TX_TRACK_GROUPING_CHANGED : 1|1@0+ (1,0) [0|0] ""  AF01A
 SG_ CAN_TX_TRACK_BRIDGE_OBJECT : 39|1@0+ (1,0) [0|0] ""  AF01A
 SG_ CAN_TX_TRACK_ANGLE : 12|10@0- (0.1,0) [-51.2|51.1] "deg"  AF01A

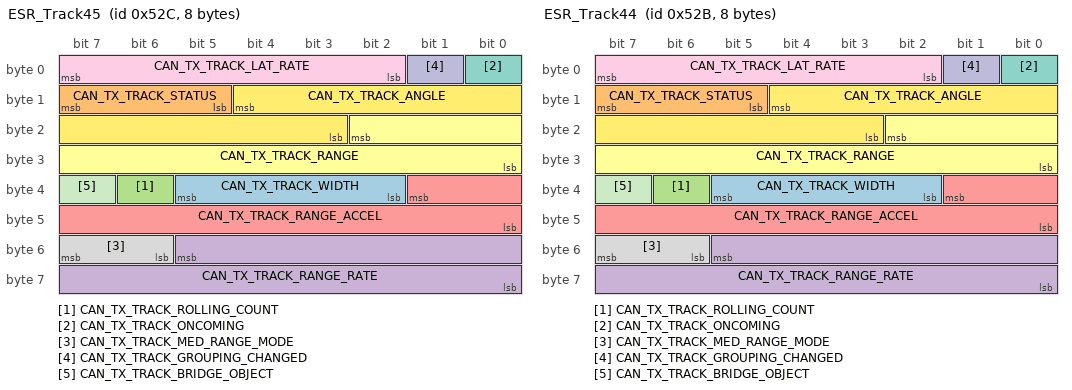
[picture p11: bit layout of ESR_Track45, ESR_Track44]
BO_ 1324 ESR_Track45: 8 Vector__XXX
 SG_ CAN_TX_TRACK_WIDTH : 37|4@0+ (0.5,0) [0|7.5] "m"  AF01A
 SG_ CAN_TX_TRACK_STATUS : 15|3@0+ (1,0) [0|7] ""  AF01A
 SG_ CAN_TX_TRACK_ROLLING_COUNT : 38|1@0+ (1,0) [0|1] ""  AF01A
 SG_ CAN_TX_TRACK_RANGE_RATE : 53|14@0- (0.01,0) [-81.92|81.91] "m/s"  AF01A
 SG_ CAN_TX_TRACK_RANGE_ACCEL : 33|10@0- (0.05,0) [-25.6|25.55] "m/s/s"  AF01A
 SG_ CAN_TX_TRACK_RANGE : 18|11@0+ (0.1,0) [0|204.7] "m"  AF01A
 SG_ CAN_TX_TRACK_ONCOMING : 0|1@0+ (1,0) [0|0] ""  AF01A
 SG_ CAN_TX_TRACK_MED_RANGE_MODE : 55|2@0+ (1,0) [0|3] ""  AF01A
 SG_ CAN_TX_TRACK_LAT_RATE : 7|6@0- (0.25,0) [-8|7.75] ""  AF01A
 SG_ CAN_TX_TRACK_GROUPING_CHANGED : 1|1@0+ (1,0) [0|0] ""  AF01A
 SG_ CAN_TX_TRACK_BRIDGE_OBJECT : 39|1@0+ (1,0) [0|0] ""  AF01A
 SG_ CAN_TX_TRACK_ANGLE : 12|10@0- (0.1,0) [-51.2|51.1] "deg"  AF01A

BO_ 1323 ESR_Track44: 8 Vector__XXX
 SG_ CAN_TX_TRACK_WIDTH : 37|4@0+ (0.5,0) [0|7.5] "m"  AF01A
 SG_ CAN_TX_TRACK_STATUS : 15|3@0+ (1,0) [0|7] ""  AF01A
 SG_ CAN_TX_TRACK_ROLLING_COUNT : 38|1@0+ (1,0) [0|1] ""  AF01A
 SG_ CAN_TX_TRACK_RANGE_RATE : 53|14@0- (0.01,0) [-81.92|81.91] "m/s"  AF01A
 SG_ CAN_TX_TRACK_RANGE_ACCEL : 33|10@0- (0.05,0) [-25.6|25.55] "m/s/s"  AF01A
 SG_ CAN_TX_TRACK_RANGE : 18|11@0+ (0.1,0) [0|204.7] "m"  AF01A
 SG_ CAN_TX_TRACK_ONCOMING : 0|1@0+ (1,0) [0|0] ""  AF01A
 SG_ CAN_TX_TRACK_MED_RANGE_MODE : 55|2@0+ (1,0) [0|3] ""  AF01A
 SG_ CAN_TX_TRACK_LAT_RATE : 7|6@0- (0.25,0) [-8|7.75] ""  AF01A
 SG_ CAN_TX_TRACK_GROUPING_CHANGED : 1|1@0+ (1,0) [0|0] ""  AF01A
 SG_ CAN_TX_TRACK_BRIDGE_OBJECT : 39|1@0+ (1,0) [0|0] ""  AF01A
 SG_ CAN_TX_TRACK_ANGLE : 12|10@0- (0.1,0) [-51.2|51.1] "deg"  AF01A

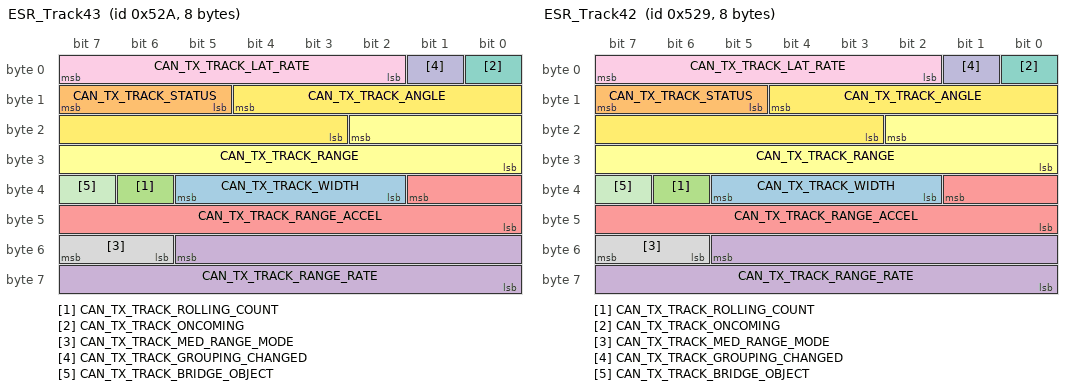
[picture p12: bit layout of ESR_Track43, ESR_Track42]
BO_ 1322 ESR_Track43: 8 Vector__XXX
 SG_ CAN_TX_TRACK_WIDTH : 37|4@0+ (0.5,0) [0|7.5] "m"  AF01A
 SG_ CAN_TX_TRACK_STATUS : 15|3@0+ (1,0) [0|7] ""  AF01A
 SG_ CAN_TX_TRACK_ROLLING_COUNT : 38|1@0+ (1,0) [0|1] ""  AF01A
 SG_ CAN_TX_TRACK_RANGE_RATE : 53|14@0- (0.01,0) [-81.92|81.91] "m/s"  AF01A
 SG_ CAN_TX_TRACK_RANGE_ACCEL : 33|10@0- (0.05,0) [-25.6|25.55] "m/s/s"  AF01A
 SG_ CAN_TX_TRACK_RANGE : 18|11@0+ (0.1,0) [0|204.7] "m"  AF01A
 SG_ CAN_TX_TRACK_ONCOMING : 0|1@0+ (1,0) [0|0] ""  AF01A
 SG_ CAN_TX_TRACK_MED_RANGE_MODE : 55|2@0+ (1,0) [0|3] ""  AF01A
 SG_ CAN_TX_TRACK_LAT_RATE : 7|6@0- (0.25,0) [-8|7.75] ""  AF01A
 SG_ CAN_TX_TRACK_GROUPING_CHANGED : 1|1@0+ (1,0) [0|0] ""  AF01A
 SG_ CAN_TX_TRACK_BRIDGE_OBJECT : 39|1@0+ (1,0) [0|0] ""  AF01A
 SG_ CAN_TX_TRACK_ANGLE : 12|10@0- (0.1,0) [-51.2|51.1] "deg"  AF01A

BO_ 1321 ESR_Track42: 8 Vector__XXX
 SG_ CAN_TX_TRACK_WIDTH : 37|4@0+ (0.5,0) [0|7.5] "m"  AF01A
 SG_ CAN_TX_TRACK_STATUS : 15|3@0+ (1,0) [0|7] ""  AF01A
 SG_ CAN_TX_TRACK_ROLLING_COUNT : 38|1@0+ (1,0) [0|1] ""  AF01A
 SG_ CAN_TX_TRACK_RANGE_RATE : 53|14@0- (0.01,0) [-81.92|81.91] "m/s"  AF01A
 SG_ CAN_TX_TRACK_RANGE_ACCEL : 33|10@0- (0.05,0) [-25.6|25.55] "m/s/s"  AF01A
 SG_ CAN_TX_TRACK_RANGE : 18|11@0+ (0.1,0) [0|204.7] "m"  AF01A
 SG_ CAN_TX_TRACK_ONCOMING : 0|1@0+ (1,0) [0|0] ""  AF01A
 SG_ CAN_TX_TRACK_MED_RANGE_MODE : 55|2@0+ (1,0) [0|3] ""  AF01A
 SG_ CAN_TX_TRACK_LAT_RATE : 7|6@0- (0.25,0) [-8|7.75] ""  AF01A
 SG_ CAN_TX_TRACK_GROUPING_CHANGED : 1|1@0+ (1,0) [0|0] ""  AF01A
 SG_ CAN_TX_TRACK_BRIDGE_OBJECT : 39|1@0+ (1,0) [0|0] ""  AF01A
 SG_ CAN_TX_TRACK_ANGLE : 12|10@0- (0.1,0) [-51.2|51.1] "deg"  AF01A

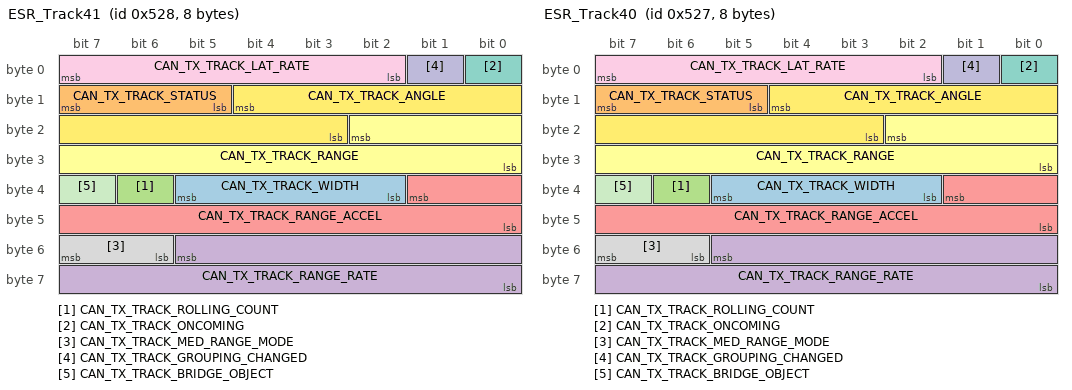
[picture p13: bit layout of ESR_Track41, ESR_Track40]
BO_ 1320 ESR_Track41: 8 Vector__XXX
 SG_ CAN_TX_TRACK_WIDTH : 37|4@0+ (0.5,0) [0|7.5] "m"  AF01A
 SG_ CAN_TX_TRACK_STATUS : 15|3@0+ (1,0) [0|7] ""  AF01A
 SG_ CAN_TX_TRACK_ROLLING_COUNT : 38|1@0+ (1,0) [0|1] ""  AF01A
 SG_ CAN_TX_TRACK_RANGE_RATE : 53|14@0- (0.01,0) [-81.92|81.91] "m/s"  AF01A
 SG_ CAN_TX_TRACK_RANGE_ACCEL : 33|10@0- (0.05,0) [-25.6|25.55] "m/s/s"  AF01A
 SG_ CAN_TX_TRACK_RANGE : 18|11@0+ (0.1,0) [0|204.7] "m"  AF01A
 SG_ CAN_TX_TRACK_ONCOMING : 0|1@0+ (1,0) [0|0] ""  AF01A
 SG_ CAN_TX_TRACK_MED_RANGE_MODE : 55|2@0+ (1,0) [0|3] ""  AF01A
 SG_ CAN_TX_TRACK_LAT_RATE : 7|6@0- (0.25,0) [-8|7.75] ""  AF01A
 SG_ CAN_TX_TRACK_GROUPING_CHANGED : 1|1@0+ (1,0) [0|0] ""  AF01A
 SG_ CAN_TX_TRACK_BRIDGE_OBJECT : 39|1@0+ (1,0) [0|0] ""  AF01A
 SG_ CAN_TX_TRACK_ANGLE : 12|10@0- (0.1,0) [-51.2|51.1] "deg"  AF01A

BO_ 1319 ESR_Track40: 8 Vector__XXX
 SG_ CAN_TX_TRACK_WIDTH : 37|4@0+ (0.5,0) [0|7.5] "m"  AF01A
 SG_ CAN_TX_TRACK_STATUS : 15|3@0+ (1,0) [0|7] ""  AF01A
 SG_ CAN_TX_TRACK_ROLLING_COUNT : 38|1@0+ (1,0) [0|1] ""  AF01A
 SG_ CAN_TX_TRACK_RANGE_RATE : 53|14@0- (0.01,0) [-81.92|81.91] "m/s"  AF01A
 SG_ CAN_TX_TRACK_RANGE_ACCEL : 33|10@0- (0.05,0) [-25.6|25.55] "m/s/s"  AF01A
 SG_ CAN_TX_TRACK_RANGE : 18|11@0+ (0.1,0) [0|204.7] "m"  AF01A
 SG_ CAN_TX_TRACK_ONCOMING : 0|1@0+ (1,0) [0|0] ""  AF01A
 SG_ CAN_TX_TRACK_MED_RANGE_MODE : 55|2@0+ (1,0) [0|3] ""  AF01A
 SG_ CAN_TX_TRACK_LAT_RATE : 7|6@0- (0.25,0) [-8|7.75] ""  AF01A
 SG_ CAN_TX_TRACK_GROUPING_CHANGED : 1|1@0+ (1,0) [0|0] ""  AF01A
 SG_ CAN_TX_TRACK_BRIDGE_OBJECT : 39|1@0+ (1,0) [0|0] ""  AF01A
 SG_ CAN_TX_TRACK_ANGLE : 12|10@0- (0.1,0) [-51.2|51.1] "deg"  AF01A

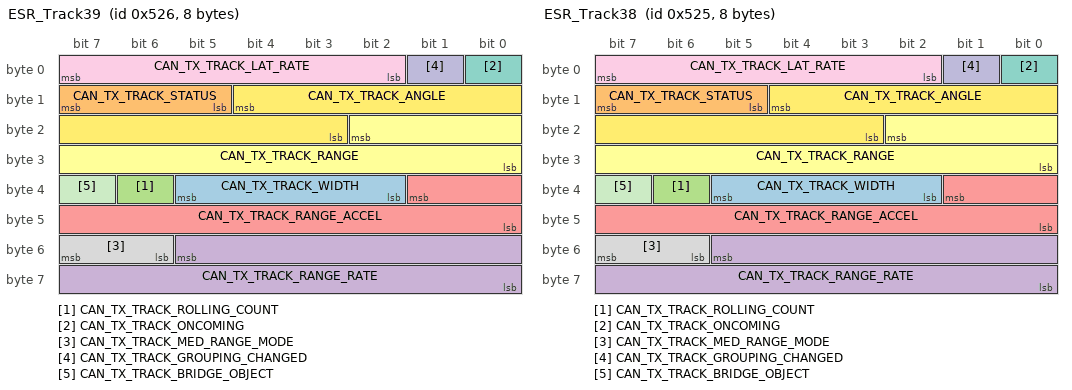
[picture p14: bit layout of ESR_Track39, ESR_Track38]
BO_ 1318 ESR_Track39: 8 Vector__XXX
 SG_ CAN_TX_TRACK_WIDTH : 37|4@0+ (0.5,0) [0|7.5] "m"  AF01A
 SG_ CAN_TX_TRACK_STATUS : 15|3@0+ (1,0) [0|7] ""  AF01A
 SG_ CAN_TX_TRACK_ROLLING_COUNT : 38|1@0+ (1,0) [0|1] ""  AF01A
 SG_ CAN_TX_TRACK_RANGE_RATE : 53|14@0- (0.01,0) [-81.92|81.91] "m/s"  AF01A
 SG_ CAN_TX_TRACK_RANGE_ACCEL : 33|10@0- (0.05,0) [-25.6|25.55] "m/s/s"  AF01A
 SG_ CAN_TX_TRACK_RANGE : 18|11@0+ (0.1,0) [0|204.7] "m"  AF01A
 SG_ CAN_TX_TRACK_ONCOMING : 0|1@0+ (1,0) [0|0] ""  AF01A
 SG_ CAN_TX_TRACK_MED_RANGE_MODE : 55|2@0+ (1,0) [0|3] ""  AF01A
 SG_ CAN_TX_TRACK_LAT_RATE : 7|6@0- (0.25,0) [-8|7.75] ""  AF01A
 SG_ CAN_TX_TRACK_GROUPING_CHANGED : 1|1@0+ (1,0) [0|0] ""  AF01A
 SG_ CAN_TX_TRACK_BRIDGE_OBJECT : 39|1@0+ (1,0) [0|0] ""  AF01A
 SG_ CAN_TX_TRACK_ANGLE : 12|10@0- (0.1,0) [-51.2|51.1] "deg"  AF01A

BO_ 1317 ESR_Track38: 8 Vector__XXX
 SG_ CAN_TX_TRACK_WIDTH : 37|4@0+ (0.5,0) [0|7.5] "m"  AF01A
 SG_ CAN_TX_TRACK_STATUS : 15|3@0+ (1,0) [0|7] ""  AF01A
 SG_ CAN_TX_TRACK_ROLLING_COUNT : 38|1@0+ (1,0) [0|1] ""  AF01A
 SG_ CAN_TX_TRACK_RANGE_RATE : 53|14@0- (0.01,0) [-81.92|81.91] "m/s"  AF01A
 SG_ CAN_TX_TRACK_RANGE_ACCEL : 33|10@0- (0.05,0) [-25.6|25.55] "m/s/s"  AF01A
 SG_ CAN_TX_TRACK_RANGE : 18|11@0+ (0.1,0) [0|204.7] "m"  AF01A
 SG_ CAN_TX_TRACK_ONCOMING : 0|1@0+ (1,0) [0|0] ""  AF01A
 SG_ CAN_TX_TRACK_MED_RANGE_MODE : 55|2@0+ (1,0) [0|3] ""  AF01A
 SG_ CAN_TX_TRACK_LAT_RATE : 7|6@0- (0.25,0) [-8|7.75] ""  AF01A
 SG_ CAN_TX_TRACK_GROUPING_CHANGED : 1|1@0+ (1,0) [0|0] ""  AF01A
 SG_ CAN_TX_TRACK_BRIDGE_OBJECT : 39|1@0+ (1,0) [0|0] ""  AF01A
 SG_ CAN_TX_TRACK_ANGLE : 12|10@0- (0.1,0) [-51.2|51.1] "deg"  AF01A

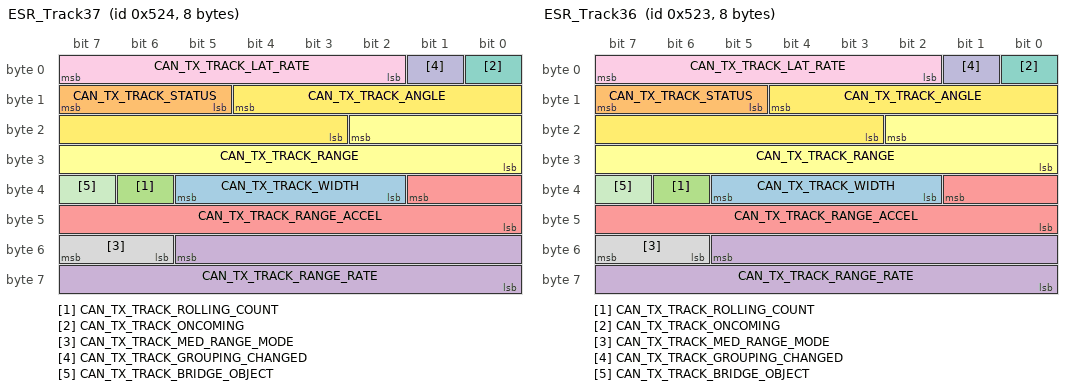
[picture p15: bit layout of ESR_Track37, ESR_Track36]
BO_ 1316 ESR_Track37: 8 Vector__XXX
 SG_ CAN_TX_TRACK_WIDTH : 37|4@0+ (0.5,0) [0|7.5] "m"  AF01A
 SG_ CAN_TX_TRACK_STATUS : 15|3@0+ (1,0) [0|7] ""  AF01A
 SG_ CAN_TX_TRACK_ROLLING_COUNT : 38|1@0+ (1,0) [0|1] ""  AF01A
 SG_ CAN_TX_TRACK_RANGE_RATE : 53|14@0- (0.01,0) [-81.92|81.91] "m/s"  AF01A
 SG_ CAN_TX_TRACK_RANGE_ACCEL : 33|10@0- (0.05,0) [-25.6|25.55] "m/s/s"  AF01A
 SG_ CAN_TX_TRACK_RANGE : 18|11@0+ (0.1,0) [0|204.7] "m"  AF01A
 SG_ CAN_TX_TRACK_ONCOMING : 0|1@0+ (1,0) [0|0] ""  AF01A
 SG_ CAN_TX_TRACK_MED_RANGE_MODE : 55|2@0+ (1,0) [0|3] ""  AF01A
 SG_ CAN_TX_TRACK_LAT_RATE : 7|6@0- (0.25,0) [-8|7.75] ""  AF01A
 SG_ CAN_TX_TRACK_GROUPING_CHANGED : 1|1@0+ (1,0) [0|0] ""  AF01A
 SG_ CAN_TX_TRACK_BRIDGE_OBJECT : 39|1@0+ (1,0) [0|0] ""  AF01A
 SG_ CAN_TX_TRACK_ANGLE : 12|10@0- (0.1,0) [-51.2|51.1] "deg"  AF01A

BO_ 1315 ESR_Track36: 8 Vector__XXX
 SG_ CAN_TX_TRACK_WIDTH : 37|4@0+ (0.5,0) [0|7.5] "m"  AF01A
 SG_ CAN_TX_TRACK_STATUS : 15|3@0+ (1,0) [0|7] ""  AF01A
 SG_ CAN_TX_TRACK_ROLLING_COUNT : 38|1@0+ (1,0) [0|1] ""  AF01A
 SG_ CAN_TX_TRACK_RANGE_RATE : 53|14@0- (0.01,0) [-81.92|81.91] "m/s"  AF01A
 SG_ CAN_TX_TRACK_RANGE_ACCEL : 33|10@0- (0.05,0) [-25.6|25.55] "m/s/s"  AF01A
 SG_ CAN_TX_TRACK_RANGE : 18|11@0+ (0.1,0) [0|204.7] "m"  AF01A
 SG_ CAN_TX_TRACK_ONCOMING : 0|1@0+ (1,0) [0|0] ""  AF01A
 SG_ CAN_TX_TRACK_MED_RANGE_MODE : 55|2@0+ (1,0) [0|3] ""  AF01A
 SG_ CAN_TX_TRACK_LAT_RATE : 7|6@0- (0.25,0) [-8|7.75] ""  AF01A
 SG_ CAN_TX_TRACK_GROUPING_CHANGED : 1|1@0+ (1,0) [0|0] ""  AF01A
 SG_ CAN_TX_TRACK_BRIDGE_OBJECT : 39|1@0+ (1,0) [0|0] ""  AF01A
 SG_ CAN_TX_TRACK_ANGLE : 12|10@0- (0.1,0) [-51.2|51.1] "deg"  AF01A

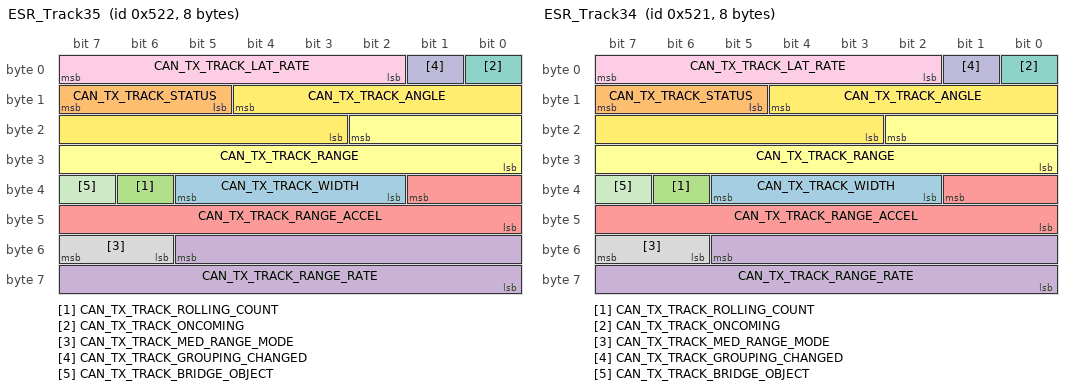
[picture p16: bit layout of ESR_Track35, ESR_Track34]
BO_ 1314 ESR_Track35: 8 Vector__XXX
 SG_ CAN_TX_TRACK_WIDTH : 37|4@0+ (0.5,0) [0|7.5] "m"  AF01A
 SG_ CAN_TX_TRACK_STATUS : 15|3@0+ (1,0) [0|7] ""  AF01A
 SG_ CAN_TX_TRACK_ROLLING_COUNT : 38|1@0+ (1,0) [0|1] ""  AF01A
 SG_ CAN_TX_TRACK_RANGE_RATE : 53|14@0- (0.01,0) [-81.92|81.91] "m/s"  AF01A
 SG_ CAN_TX_TRACK_RANGE_ACCEL : 33|10@0- (0.05,0) [-25.6|25.55] "m/s/s"  AF01A
 SG_ CAN_TX_TRACK_RANGE : 18|11@0+ (0.1,0) [0|204.7] "m"  AF01A
 SG_ CAN_TX_TRACK_ONCOMING : 0|1@0+ (1,0) [0|0] ""  AF01A
 SG_ CAN_TX_TRACK_MED_RANGE_MODE : 55|2@0+ (1,0) [0|3] ""  AF01A
 SG_ CAN_TX_TRACK_LAT_RATE : 7|6@0- (0.25,0) [-8|7.75] ""  AF01A
 SG_ CAN_TX_TRACK_GROUPING_CHANGED : 1|1@0+ (1,0) [0|0] ""  AF01A
 SG_ CAN_TX_TRACK_BRIDGE_OBJECT : 39|1@0+ (1,0) [0|0] ""  AF01A
 SG_ CAN_TX_TRACK_ANGLE : 12|10@0- (0.1,0) [-51.2|51.1] "deg"  AF01A

BO_ 1313 ESR_Track34: 8 Vector__XXX
 SG_ CAN_TX_TRACK_WIDTH : 37|4@0+ (0.5,0) [0|7.5] "m"  AF01A
 SG_ CAN_TX_TRACK_STATUS : 15|3@0+ (1,0) [0|7] ""  AF01A
 SG_ CAN_TX_TRACK_ROLLING_COUNT : 38|1@0+ (1,0) [0|1] ""  AF01A
 SG_ CAN_TX_TRACK_RANGE_RATE : 53|14@0- (0.01,0) [-81.92|81.91] "m/s"  AF01A
 SG_ CAN_TX_TRACK_RANGE_ACCEL : 33|10@0- (0.05,0) [-25.6|25.55] "m/s/s"  AF01A
 SG_ CAN_TX_TRACK_RANGE : 18|11@0+ (0.1,0) [0|204.7] "m"  AF01A
 SG_ CAN_TX_TRACK_ONCOMING : 0|1@0+ (1,0) [0|0] ""  AF01A
 SG_ CAN_TX_TRACK_MED_RANGE_MODE : 55|2@0+ (1,0) [0|3] ""  AF01A
 SG_ CAN_TX_TRACK_LAT_RATE : 7|6@0- (0.25,0) [-8|7.75] ""  AF01A
 SG_ CAN_TX_TRACK_GROUPING_CHANGED : 1|1@0+ (1,0) [0|0] ""  AF01A
 SG_ CAN_TX_TRACK_BRIDGE_OBJECT : 39|1@0+ (1,0) [0|0] ""  AF01A
 SG_ CAN_TX_TRACK_ANGLE : 12|10@0- (0.1,0) [-51.2|51.1] "deg"  AF01A

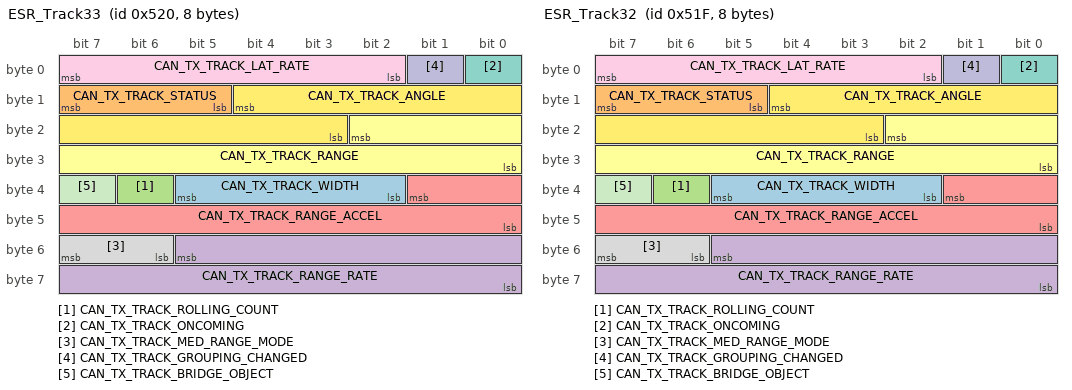
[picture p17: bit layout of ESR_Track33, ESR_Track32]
BO_ 1312 ESR_Track33: 8 Vector__XXX
 SG_ CAN_TX_TRACK_WIDTH : 37|4@0+ (0.5,0) [0|7.5] "m"  AF01A
 SG_ CAN_TX_TRACK_STATUS : 15|3@0+ (1,0) [0|7] ""  AF01A
 SG_ CAN_TX_TRACK_ROLLING_COUNT : 38|1@0+ (1,0) [0|1] ""  AF01A
 SG_ CAN_TX_TRACK_RANGE_RATE : 53|14@0- (0.01,0) [-81.92|81.91] "m/s"  AF01A
 SG_ CAN_TX_TRACK_RANGE_ACCEL : 33|10@0- (0.05,0) [-25.6|25.55] "m/s/s"  AF01A
 SG_ CAN_TX_TRACK_RANGE : 18|11@0+ (0.1,0) [0|204.7] "m"  AF01A
 SG_ CAN_TX_TRACK_ONCOMING : 0|1@0+ (1,0) [0|0] ""  AF01A
 SG_ CAN_TX_TRACK_MED_RANGE_MODE : 55|2@0+ (1,0) [0|3] ""  AF01A
 SG_ CAN_TX_TRACK_LAT_RATE : 7|6@0- (0.25,0) [-8|7.75] ""  AF01A
 SG_ CAN_TX_TRACK_GROUPING_CHANGED : 1|1@0+ (1,0) [0|0] ""  AF01A
 SG_ CAN_TX_TRACK_BRIDGE_OBJECT : 39|1@0+ (1,0) [0|0] ""  AF01A
 SG_ CAN_TX_TRACK_ANGLE : 12|10@0- (0.1,0) [-51.2|51.1] "deg"  AF01A

BO_ 1311 ESR_Track32: 8 Vector__XXX
 SG_ CAN_TX_TRACK_WIDTH : 37|4@0+ (0.5,0) [0|7.5] "m"  AF01A
 SG_ CAN_TX_TRACK_STATUS : 15|3@0+ (1,0) [0|7] ""  AF01A
 SG_ CAN_TX_TRACK_ROLLING_COUNT : 38|1@0+ (1,0) [0|1] ""  AF01A
 SG_ CAN_TX_TRACK_RANGE_RATE : 53|14@0- (0.01,0) [-81.92|81.91] "m/s"  AF01A
 SG_ CAN_TX_TRACK_RANGE_ACCEL : 33|10@0- (0.05,0) [-25.6|25.55] "m/s/s"  AF01A
 SG_ CAN_TX_TRACK_RANGE : 18|11@0+ (0.1,0) [0|204.7] "m"  AF01A
 SG_ CAN_TX_TRACK_ONCOMING : 0|1@0+ (1,0) [0|0] ""  AF01A
 SG_ CAN_TX_TRACK_MED_RANGE_MODE : 55|2@0+ (1,0) [0|3] ""  AF01A
 SG_ CAN_TX_TRACK_LAT_RATE : 7|6@0- (0.25,0) [-8|7.75] ""  AF01A
 SG_ CAN_TX_TRACK_GROUPING_CHANGED : 1|1@0+ (1,0) [0|0] ""  AF01A
 SG_ CAN_TX_TRACK_BRIDGE_OBJECT : 39|1@0+ (1,0) [0|0] ""  AF01A
 SG_ CAN_TX_TRACK_ANGLE : 12|10@0- (0.1,0) [-51.2|51.1] "deg"  AF01A

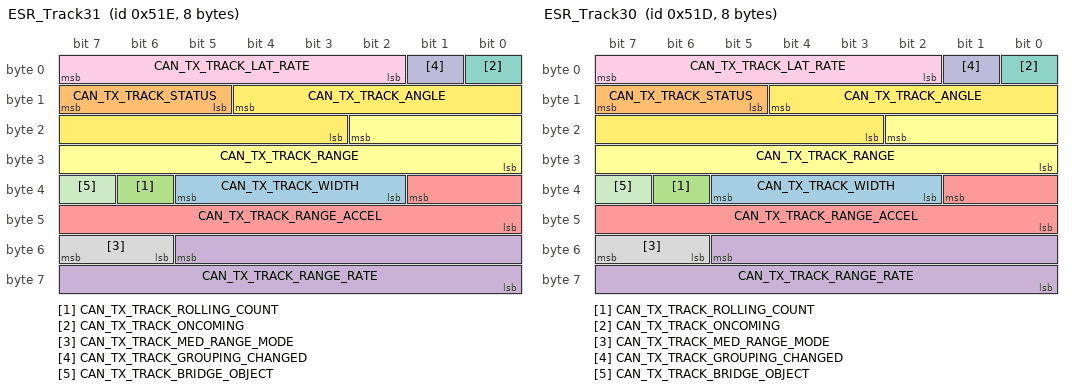
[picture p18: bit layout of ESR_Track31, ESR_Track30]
BO_ 1310 ESR_Track31: 8 Vector__XXX
 SG_ CAN_TX_TRACK_WIDTH : 37|4@0+ (0.5,0) [0|7.5] "m"  AF01A
 SG_ CAN_TX_TRACK_STATUS : 15|3@0+ (1,0) [0|7] ""  AF01A
 SG_ CAN_TX_TRACK_ROLLING_COUNT : 38|1@0+ (1,0) [0|1] ""  AF01A
 SG_ CAN_TX_TRACK_RANGE_RATE : 53|14@0- (0.01,0) [-81.92|81.91] "m/s"  AF01A
 SG_ CAN_TX_TRACK_RANGE_ACCEL : 33|10@0- (0.05,0) [-25.6|25.55] "m/s/s"  AF01A
 SG_ CAN_TX_TRACK_RANGE : 18|11@0+ (0.1,0) [0|204.7] "m"  AF01A
 SG_ CAN_TX_TRACK_ONCOMING : 0|1@0+ (1,0) [0|0] ""  AF01A
 SG_ CAN_TX_TRACK_MED_RANGE_MODE : 55|2@0+ (1,0) [0|3] ""  AF01A
 SG_ CAN_TX_TRACK_LAT_RATE : 7|6@0- (0.25,0) [-8|7.75] ""  AF01A
 SG_ CAN_TX_TRACK_GROUPING_CHANGED : 1|1@0+ (1,0) [0|0] ""  AF01A
 SG_ CAN_TX_TRACK_BRIDGE_OBJECT : 39|1@0+ (1,0) [0|0] ""  AF01A
 SG_ CAN_TX_TRACK_ANGLE : 12|10@0- (0.1,0) [-51.2|51.1] "deg"  AF01A

BO_ 1309 ESR_Track30: 8 Vector__XXX
 SG_ CAN_TX_TRACK_WIDTH : 37|4@0+ (0.5,0) [0|7.5] "m"  AF01A
 SG_ CAN_TX_TRACK_STATUS : 15|3@0+ (1,0) [0|7] ""  AF01A
 SG_ CAN_TX_TRACK_ROLLING_COUNT : 38|1@0+ (1,0) [0|1] ""  AF01A
 SG_ CAN_TX_TRACK_RANGE_RATE : 53|14@0- (0.01,0) [-81.92|81.91] "m/s"  AF01A
 SG_ CAN_TX_TRACK_RANGE_ACCEL : 33|10@0- (0.05,0) [-25.6|25.55] "m/s/s"  AF01A
 SG_ CAN_TX_TRACK_RANGE : 18|11@0+ (0.1,0) [0|204.7] "m"  AF01A
 SG_ CAN_TX_TRACK_ONCOMING : 0|1@0+ (1,0) [0|0] ""  AF01A
 SG_ CAN_TX_TRACK_MED_RANGE_MODE : 55|2@0+ (1,0) [0|3] ""  AF01A
 SG_ CAN_TX_TRACK_LAT_RATE : 7|6@0- (0.25,0) [-8|7.75] ""  AF01A
 SG_ CAN_TX_TRACK_GROUPING_CHANGED : 1|1@0+ (1,0) [0|0] ""  AF01A
 SG_ CAN_TX_TRACK_BRIDGE_OBJECT : 39|1@0+ (1,0) [0|0] ""  AF01A
 SG_ CAN_TX_TRACK_ANGLE : 12|10@0- (0.1,0) [-51.2|51.1] "deg"  AF01A

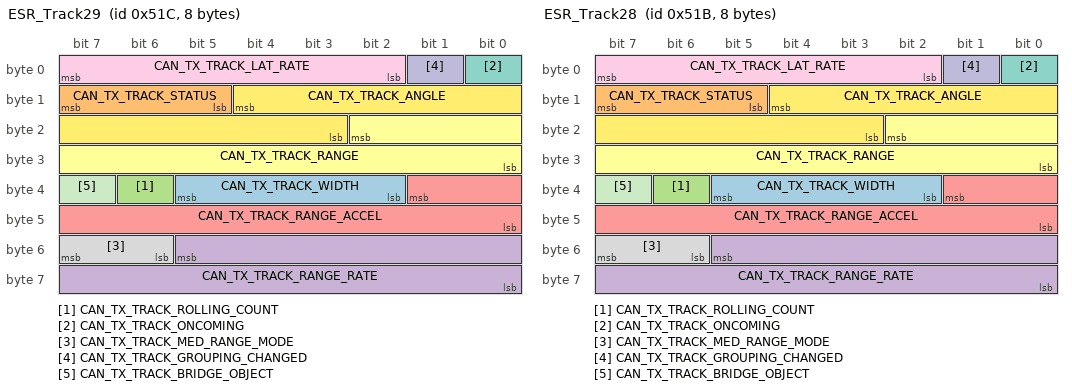
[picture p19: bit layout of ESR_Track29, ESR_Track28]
BO_ 1308 ESR_Track29: 8 Vector__XXX
 SG_ CAN_TX_TRACK_WIDTH : 37|4@0+ (0.5,0) [0|7.5] "m"  AF01A
 SG_ CAN_TX_TRACK_STATUS : 15|3@0+ (1,0) [0|7] ""  AF01A
 SG_ CAN_TX_TRACK_ROLLING_COUNT : 38|1@0+ (1,0) [0|1] ""  AF01A
 SG_ CAN_TX_TRACK_RANGE_RATE : 53|14@0- (0.01,0) [-81.92|81.91] "m/s"  AF01A
 SG_ CAN_TX_TRACK_RANGE_ACCEL : 33|10@0- (0.05,0) [-25.6|25.55] "m/s/s"  AF01A
 SG_ CAN_TX_TRACK_RANGE : 18|11@0+ (0.1,0) [0|204.7] "m"  AF01A
 SG_ CAN_TX_TRACK_ONCOMING : 0|1@0+ (1,0) [0|0] ""  AF01A
 SG_ CAN_TX_TRACK_MED_RANGE_MODE : 55|2@0+ (1,0) [0|3] ""  AF01A
 SG_ CAN_TX_TRACK_LAT_RATE : 7|6@0- (0.25,0) [-8|7.75] ""  AF01A
 SG_ CAN_TX_TRACK_GROUPING_CHANGED : 1|1@0+ (1,0) [0|0] ""  AF01A
 SG_ CAN_TX_TRACK_BRIDGE_OBJECT : 39|1@0+ (1,0) [0|0] ""  AF01A
 SG_ CAN_TX_TRACK_ANGLE : 12|10@0- (0.1,0) [-51.2|51.1] "deg"  AF01A

BO_ 1307 ESR_Track28: 8 Vector__XXX
 SG_ CAN_TX_TRACK_WIDTH : 37|4@0+ (0.5,0) [0|7.5] "m"  AF01A
 SG_ CAN_TX_TRACK_STATUS : 15|3@0+ (1,0) [0|7] ""  AF01A
 SG_ CAN_TX_TRACK_ROLLING_COUNT : 38|1@0+ (1,0) [0|1] ""  AF01A
 SG_ CAN_TX_TRACK_RANGE_RATE : 53|14@0- (0.01,0) [-81.92|81.91] "m/s"  AF01A
 SG_ CAN_TX_TRACK_RANGE_ACCEL : 33|10@0- (0.05,0) [-25.6|25.55] "m/s/s"  AF01A
 SG_ CAN_TX_TRACK_RANGE : 18|11@0+ (0.1,0) [0|204.7] "m"  AF01A
 SG_ CAN_TX_TRACK_ONCOMING : 0|1@0+ (1,0) [0|0] ""  AF01A
 SG_ CAN_TX_TRACK_MED_RANGE_MODE : 55|2@0+ (1,0) [0|3] ""  AF01A
 SG_ CAN_TX_TRACK_LAT_RATE : 7|6@0- (0.25,0) [-8|7.75] ""  AF01A
 SG_ CAN_TX_TRACK_GROUPING_CHANGED : 1|1@0+ (1,0) [0|0] ""  AF01A
 SG_ CAN_TX_TRACK_BRIDGE_OBJECT : 39|1@0+ (1,0) [0|0] ""  AF01A
 SG_ CAN_TX_TRACK_ANGLE : 12|10@0- (0.1,0) [-51.2|51.1] "deg"  AF01A

CM_ BO_ 3221225472 "This is a message for not used signals, created by Vector CANdb++ DBC OLE DB Provider.";
BA_DEF_ SG_  "GenSigSendType" ENUM  "Cyclic","OnWrite","OnWriteWithRepetition","OnChange","OnChangeWithRepetition","IfActive","IfActiveWithRepetition","NoSigSendType";
BA_DEF_ BO_  "GenMsgSendType" ENUM  "Cyclic","not_used","not_used","not_used","not_used","not_used","not_used","IfActive","NoMsgSendType";
BA_DEF_ BO_  "GenMsgNrOfRepetition" INT 0 100;
BA_DEF_ BO_  "GenMsgILSupport" ENUM  "No","Yes";
BA_DEF_ BO_  "GenMsgCycleTimeFast" INT 0 100000;
BA_DEF_ BO_  "GenMsgCycleTime" INT 0 10000;
BA_DEF_ BU_  "NmNode" ENUM  "No","Yes";
BA_DEF_ BU_  "ILUsed" ENUM  "No","Yes";
BA_DEF_  "BusType" STRING ;
BA_DEF_  "NmType" STRING ;
BA_DEF_  "NmMessageCount" INT 2 256;
BA_DEF_  "NmBaseAddress" HEX 0 2047;
BA_DEF_  "Manufacturer" STRING ;
BA_DEF_REL_ BU_SG_REL_  "GenSigTimeoutTime" INT 0 65535;
BA_DEF_DEF_  "GenSigSendType" "Cyclic";
BA_DEF_DEF_  "GenMsgSendType" "Cyclic";
BA_DEF_DEF_  "GenMsgNrOfRepetition" 0;
BA_DEF_DEF_  "GenMsgILSupport" "Yes";
BA_DEF_DEF_  "GenMsgCycleTimeFast" 0;
BA_DEF_DEF_  "GenMsgCycleTime" 0;
BA_DEF_DEF_  "NmNode" "Yes";
BA_DEF_DEF_  "ILUsed" "Yes";
BA_DEF_DEF_  "BusType" "";
BA_DEF_DEF_  "NmType" "NmPwrTrainChery";
BA_DEF_DEF_  "NmMessageCount" 64;
BA_DEF_DEF_  "NmBaseAddress" 1024;
BA_DEF_DEF_  "Manufacturer" "GAC";
BA_DEF_DEF_REL_ "GenSigTimeoutTime" 0;
BA_ "BusType" "CAN";
BA_ "NmType" "GAC-OSEK";
BA_ "NmMessageCount" 256;
BA_ "GenMsgCycleTime" BO_ 819 100;
BA_REL_ "GenSigTimeoutTime" BU_SG_REL_ AF01A SG_ 273 LD_SWITCH 60;
BA_REL_ "GenSigTimeoutTime" BU_SG_REL_ AF01A SG_ 273 VD_SWITCH 60;
BA_REL_ "GenSigTimeoutTime" BU_SG_REL_ AF01A SG_ 273 PD_SWITCH 60;
BA_REL_ "GenSigTimeoutTime" BU_SG_REL_ AF01A SG_ 273 TSR_SWITCH 60;
BA_REL_ "GenSigTimeoutTime" BU_SG_REL_ AF01A SG_ 273 TRAFFIC_LIGHT_SWITCH 60;
BA_REL_ "GenSigTimeoutTime" BU_SG_REL_ AF01A SG_ 273 IHC_SWITCH 60;
BA_REL_ "GenSigTimeoutTime" BU_SG_REL_ AF01A SG_ 273 PCW_SWITCH 60;
BA_REL_ "GenSigTimeoutTime" BU_SG_REL_ AF01A SG_ 273 FCW_SWITCH 60;
BA_REL_ "GenSigTimeoutTime" BU_SG_REL_ AF01A SG_ 273 LDW_SWITCH 60;
BA_REL_ "GenSigTimeoutTime" BU_SG_REL_ AF01A SG_ 1512 CAN_TX_SIDESLIP_ANGLE 60;
BA_REL_ "GenSigTimeoutTime" BU_SG_REL_ AF01A SG_ 1512 CAN_TX_SERIAL_NUM_3RD_BYTE 60;
BA_REL_ "GenSigTimeoutTime" BU_SG_REL_ AF01A SG_ 1512 CAN_TX_PATH_ID_ACC_3 60;
BA_REL_ "GenSigTimeoutTime" BU_SG_REL_ AF01A SG_ 1512 CAN_TX_PATH_ID_ACC_2 60;
BA_REL_ "GenSigTimeoutTime" BU_SG_REL_ AF01A SG_ 1512 CAN_TX_FILTERED_XOHP_ACC_CIPV 60;
BA_REL_ "GenSigTimeoutTime" BU_SG_REL_ AF01A SG_ 1512 CAN_TX_WATER_SPRAY_TARGET_ID 60;
BA_REL_ "GenSigTimeoutTime" BU_SG_REL_ AF01A SG_ 1512 CAN_TX_AVG_PWR_CWBLKG 60;
BA_REL_ "GenSigTimeoutTime" BU_SG_REL_ AF01A SG_ 1511 CAN_TX_HISTORY_FAULT_7 60;
BA_REL_ "GenSigTimeoutTime" BU_SG_REL_ AF01A SG_ 1511 CAN_TX_HISTORY_FAULT_6 60;
BA_REL_ "GenSigTimeoutTime" BU_SG_REL_ AF01A SG_ 1511 CAN_TX_HISTORY_FAULT_5 60;
BA_REL_ "GenSigTimeoutTime" BU_SG_REL_ AF01A SG_ 1511 CAN_TX_HISTORY_FAULT_4 60;
BA_REL_ "GenSigTimeoutTime" BU_SG_REL_ AF01A SG_ 1511 CAN_TX_HISTORY_FAULT_3 60;
BA_REL_ "GenSigTimeoutTime" BU_SG_REL_ AF01A SG_ 1511 CAN_TX_HISTORY_FAULT_2 60;
BA_REL_ "GenSigTimeoutTime" BU_SG_REL_ AF01A SG_ 1511 CAN_TX_HISTORY_FAULT_1 60;
BA_REL_ "GenSigTimeoutTime" BU_SG_REL_ AF01A SG_ 1511 CAN_TX_HISTORY_FAULT_0 60;
BA_REL_ "GenSigTimeoutTime" BU_SG_REL_ AF01A SG_ 1510 CAN_TX_ACTIVE_FAULT_7 60;
BA_REL_ "GenSigTimeoutTime" BU_SG_REL_ AF01A SG_ 1510 CAN_TX_ACTIVE_FAULT_6 60;
BA_REL_ "GenSigTimeoutTime" BU_SG_REL_ AF01A SG_ 1510 CAN_TX_ACTIVE_FAULT_5 60;
BA_REL_ "GenSigTimeoutTime" BU_SG_REL_ AF01A SG_ 1510 CAN_TX_ACTIVE_FAULT_4 60;
BA_REL_ "GenSigTimeoutTime" BU_SG_REL_ AF01A SG_ 1510 CAN_TX_ACTIVE_FAULT_3 60;
BA_REL_ "GenSigTimeoutTime" BU_SG_REL_ AF01A SG_ 1510 CAN_TX_ACTIVE_FAULT_2 60;
BA_REL_ "GenSigTimeoutTime" BU_SG_REL_ AF01A SG_ 1510 CAN_TX_ACTIVE_FAULT_1 60;
BA_REL_ "GenSigTimeoutTime" BU_SG_REL_ AF01A SG_ 1510 CAN_TX_ACTIVE_FAULT_0 60;
BA_REL_ "GenSigTimeoutTime" BU_SG_REL_ AF01A SG_ 1509 CAN_TX_WAVE_DIFF_A2D 60;
BA_REL_ "GenSigTimeoutTime" BU_SG_REL_ AF01A SG_ 1509 CAN_TX_VERTICAL_MISALIGNMENT 60;
BA_REL_ "GenSigTimeoutTime" BU_SG_REL_ AF01A SG_ 1509 CAN_TX_VERTICAL_ALIGN_UPDATED 60;
BA_REL_ "GenSigTimeoutTime" BU_SG_REL_ AF01A SG_ 1509 CAN_TX_SYSTEM_POWER_MODE 60;
BA_REL_ "GenSigTimeoutTime" BU_SG_REL_ AF01A SG_ 1509 CAN_TX_SW_VERSION_DSP_3RD_BYTE 60;
BA_REL_ "GenSigTimeoutTime" BU_SG_REL_ AF01A SG_ 1509 CAN_TX_SUPPLY_N5V_A2D 60;
BA_REL_ "GenSigTimeoutTime" BU_SG_REL_ AF01A SG_ 1509 CAN_TX_SUPPLY_1P8V_A2D 60;
BA_REL_ "GenSigTimeoutTime" BU_SG_REL_ AF01A SG_ 1509 CAN_TX_SERV_ALIGN_UPDATES_DONE 60;
BA_REL_ "GenSigTimeoutTime" BU_SG_REL_ AF01A SG_ 1509 CAN_TX_RECOMMEND_UNCONVERGE 60;
BA_REL_ "GenSigTimeoutTime" BU_SG_REL_ AF01A SG_ 1509 CAN_TX_FOUND_TARGET 60;
BA_REL_ "GenSigTimeoutTime" BU_SG_REL_ AF01A SG_ 1509 CAN_TX_FACTORY_MISALIGNMENT 60;
BA_REL_ "GenSigTimeoutTime" BU_SG_REL_ AF01A SG_ 1509 CAN_TX_FACTORY_ALIGN_STATUS_2 60;
BA_REL_ "GenSigTimeoutTime" BU_SG_REL_ AF01A SG_ 1509 CAN_TX_FACTORY_ALIGN_STATUS_1 60;
BA_REL_ "GenSigTimeoutTime" BU_SG_REL_ AF01A SG_ 1508 CAN_TX_TEMP2_A2D 60;
BA_REL_ "GenSigTimeoutTime" BU_SG_REL_ AF01A SG_ 1508 CAN_TX_TEMP1_A2D 60;
BA_REL_ "GenSigTimeoutTime" BU_SG_REL_ AF01A SG_ 1508 CAN_TX_SWBATT_A2D 60;
BA_REL_ "GenSigTimeoutTime" BU_SG_REL_ AF01A SG_ 1508 CAN_TX_SUPPLY_5VDX_A2D 60;
BA_REL_ "GenSigTimeoutTime" BU_SG_REL_ AF01A SG_ 1508 CAN_TX_SUPPLY_5VA_A2D 60;
BA_REL_ "GenSigTimeoutTime" BU_SG_REL_ AF01A SG_ 1508 CAN_TX_SUPPLY_3P3V_A2D 60;
BA_REL_ "GenSigTimeoutTime" BU_SG_REL_ AF01A SG_ 1508 CAN_TX_SUPPLY_10V_A2D 60;
BA_REL_ "GenSigTimeoutTime" BU_SG_REL_ AF01A SG_ 1508 CAN_TX_IGNP_A2D 60;
BA_REL_ "GenSigTimeoutTime" BU_SG_REL_ AF01A SG_ 1343 CAN_TX_TRACK_WIDTH 60;
BA_REL_ "GenSigTimeoutTime" BU_SG_REL_ AF01A SG_ 1343 CAN_TX_TRACK_STATUS 60;
BA_REL_ "GenSigTimeoutTime" BU_SG_REL_ AF01A SG_ 1343 CAN_TX_TRACK_ROLLING_COUNT 60;
BA_REL_ "GenSigTimeoutTime" BU_SG_REL_ AF01A SG_ 1343 CAN_TX_TRACK_RANGE_RATE 60;
BA_REL_ "GenSigTimeoutTime" BU_SG_REL_ AF01A SG_ 1343 CAN_TX_TRACK_RANGE_ACCEL 60;
BA_REL_ "GenSigTimeoutTime" BU_SG_REL_ AF01A SG_ 1343 CAN_TX_TRACK_RANGE 60;
BA_REL_ "GenSigTimeoutTime" BU_SG_REL_ AF01A SG_ 1343 CAN_TX_TRACK_ONCOMING 60;
BA_REL_ "GenSigTimeoutTime" BU_SG_REL_ AF01A SG_ 1343 CAN_TX_TRACK_MED_RANGE_MODE 60;
BA_REL_ "GenSigTimeoutTime" BU_SG_REL_ AF01A SG_ 1343 CAN_TX_TRACK_LAT_RATE 60;
BA_REL_ "GenSigTimeoutTime" BU_SG_REL_ AF01A SG_ 1343 CAN_TX_TRACK_GROUPING_CHANGED 60;
BA_REL_ "GenSigTimeoutTime" BU_SG_REL_ AF01A SG_ 1343 CAN_TX_TRACK_BRIDGE_OBJECT 60;
BA_REL_ "GenSigTimeoutTime" BU_SG_REL_ AF01A SG_ 1343 CAN_TX_TRACK_ANGLE 60;
BA_REL_ "GenSigTimeoutTime" BU_SG_REL_ AF01A SG_ 1342 CAN_TX_TRACK_WIDTH 60;
BA_REL_ "GenSigTimeoutTime" BU_SG_REL_ AF01A SG_ 1342 CAN_TX_TRACK_STATUS 60;
BA_REL_ "GenSigTimeoutTime" BU_SG_REL_ AF01A SG_ 1342 CAN_TX_TRACK_ROLLING_COUNT 60;
BA_REL_ "GenSigTimeoutTime" BU_SG_REL_ AF01A SG_ 1342 CAN_TX_TRACK_RANGE_RATE 60;
BA_REL_ "GenSigTimeoutTime" BU_SG_REL_ AF01A SG_ 1342 CAN_TX_TRACK_RANGE_ACCEL 60;
BA_REL_ "GenSigTimeoutTime" BU_SG_REL_ AF01A SG_ 1342 CAN_TX_TRACK_RANGE 60;
BA_REL_ "GenSigTimeoutTime" BU_SG_REL_ AF01A SG_ 1342 CAN_TX_TRACK_ONCOMING 60;
BA_REL_ "GenSigTimeoutTime" BU_SG_REL_ AF01A SG_ 1342 CAN_TX_TRACK_MED_RANGE_MODE 60;
BA_REL_ "GenSigTimeoutTime" BU_SG_REL_ AF01A SG_ 1342 CAN_TX_TRACK_LAT_RATE 60;
BA_REL_ "GenSigTimeoutTime" BU_SG_REL_ AF01A SG_ 1342 CAN_TX_TRACK_GROUPING_CHANGED 60;
BA_REL_ "GenSigTimeoutTime" BU_SG_REL_ AF01A SG_ 1342 CAN_TX_TRACK_BRIDGE_OBJECT 60;
BA_REL_ "GenSigTimeoutTime" BU_SG_REL_ AF01A SG_ 1342 CAN_TX_TRACK_ANGLE 60;
BA_REL_ "GenSigTimeoutTime" BU_SG_REL_ AF01A SG_ 1341 CAN_TX_TRACK_WIDTH 60;
BA_REL_ "GenSigTimeoutTime" BU_SG_REL_ AF01A SG_ 1341 CAN_TX_TRACK_STATUS 60;
BA_REL_ "GenSigTimeoutTime" BU_SG_REL_ AF01A SG_ 1341 CAN_TX_TRACK_ROLLING_COUNT 60;
BA_REL_ "GenSigTimeoutTime" BU_SG_REL_ AF01A SG_ 1341 CAN_TX_TRACK_RANGE_RATE 60;
BA_REL_ "GenSigTimeoutTime" BU_SG_REL_ AF01A SG_ 1341 CAN_TX_TRACK_RANGE_ACCEL 60;
BA_REL_ "GenSigTimeoutTime" BU_SG_REL_ AF01A SG_ 1341 CAN_TX_TRACK_RANGE 60;
BA_REL_ "GenSigTimeoutTime" BU_SG_REL_ AF01A SG_ 1341 CAN_TX_TRACK_ONCOMING 60;
BA_REL_ "GenSigTimeoutTime" BU_SG_REL_ AF01A SG_ 1341 CAN_TX_TRACK_MED_RANGE_MODE 60;
BA_REL_ "GenSigTimeoutTime" BU_SG_REL_ AF01A SG_ 1341 CAN_TX_TRACK_LAT_RATE 60;
BA_REL_ "GenSigTimeoutTime" BU_SG_REL_ AF01A SG_ 1341 CAN_TX_TRACK_GROUPING_CHANGED 60;
BA_REL_ "GenSigTimeoutTime" BU_SG_REL_ AF01A SG_ 1341 CAN_TX_TRACK_BRIDGE_OBJECT 60;
BA_REL_ "GenSigTimeoutTime" BU_SG_REL_ AF01A SG_ 1341 CAN_TX_TRACK_ANGLE 60;
BA_REL_ "GenSigTimeoutTime" BU_SG_REL_ AF01A SG_ 1340 CAN_TX_TRACK_WIDTH 60;
BA_REL_ "GenSigTimeoutTime" BU_SG_REL_ AF01A SG_ 1340 CAN_TX_TRACK_STATUS 60;
BA_REL_ "GenSigTimeoutTime" BU_SG_REL_ AF01A SG_ 1340 CAN_TX_TRACK_ROLLING_COUNT 60;
BA_REL_ "GenSigTimeoutTime" BU_SG_REL_ AF01A SG_ 1340 CAN_TX_TRACK_RANGE_RATE 60;
BA_REL_ "GenSigTimeoutTime" BU_SG_REL_ AF01A SG_ 1340 CAN_TX_TRACK_RANGE_ACCEL 60;
BA_REL_ "GenSigTimeoutTime" BU_SG_REL_ AF01A SG_ 1340 CAN_TX_TRACK_RANGE 60;
BA_REL_ "GenSigTimeoutTime" BU_SG_REL_ AF01A SG_ 1340 CAN_TX_TRACK_ONCOMING 60;
BA_REL_ "GenSigTimeoutTime" BU_SG_REL_ AF01A SG_ 1340 CAN_TX_TRACK_MED_RANGE_MODE 60;
BA_REL_ "GenSigTimeoutTime" BU_SG_REL_ AF01A SG_ 1340 CAN_TX_TRACK_LAT_RATE 60;
BA_REL_ "GenSigTimeoutTime" BU_SG_REL_ AF01A SG_ 1340 CAN_TX_TRACK_GROUPING_CHANGED 60;
BA_REL_ "GenSigTimeoutTime" BU_SG_REL_ AF01A SG_ 1340 CAN_TX_TRACK_BRIDGE_OBJECT 60;
BA_REL_ "GenSigTimeoutTime" BU_SG_REL_ AF01A SG_ 1340 CAN_TX_TRACK_ANGLE 60;
BA_REL_ "GenSigTimeoutTime" BU_SG_REL_ AF01A SG_ 1339 CAN_TX_TRACK_WIDTH 60;
BA_REL_ "GenSigTimeoutTime" BU_SG_REL_ AF01A SG_ 1339 CAN_TX_TRACK_STATUS 60;
BA_REL_ "GenSigTimeoutTime" BU_SG_REL_ AF01A SG_ 1339 CAN_TX_TRACK_RANGE_RATE 60;
BA_REL_ "GenSigTimeoutTime" BU_SG_REL_ AF01A SG_ 1339 CAN_TX_TRACK_ROLLING_COUNT 60;
BA_REL_ "GenSigTimeoutTime" BU_SG_REL_ AF01A SG_ 1339 CAN_TX_TRACK_RANGE_ACCEL 60;
BA_REL_ "GenSigTimeoutTime" BU_SG_REL_ AF01A SG_ 1339 CAN_TX_TRACK_RANGE 60;
BA_REL_ "GenSigTimeoutTime" BU_SG_REL_ AF01A SG_ 1339 CAN_TX_TRACK_ONCOMING 60;
BA_REL_ "GenSigTimeoutTime" BU_SG_REL_ AF01A SG_ 1339 CAN_TX_TRACK_MED_RANGE_MODE 60;
BA_REL_ "GenSigTimeoutTime" BU_SG_REL_ AF01A SG_ 1339 CAN_TX_TRACK_LAT_RATE 60;
BA_REL_ "GenSigTimeoutTime" BU_SG_REL_ AF01A SG_ 1339 CAN_TX_TRACK_GROUPING_CHANGED 60;
BA_REL_ "GenSigTimeoutTime" BU_SG_REL_ AF01A SG_ 1339 CAN_TX_TRACK_BRIDGE_OBJECT 60;
BA_REL_ "GenSigTimeoutTime" BU_SG_REL_ AF01A SG_ 1339 CAN_TX_TRACK_ANGLE 60;
BA_REL_ "GenSigTimeoutTime" BU_SG_REL_ AF01A SG_ 1338 CAN_TX_TRACK_WIDTH 60;
BA_REL_ "GenSigTimeoutTime" BU_SG_REL_ AF01A SG_ 1338 CAN_TX_TRACK_STATUS 60;
BA_REL_ "GenSigTimeoutTime" BU_SG_REL_ AF01A SG_ 1338 CAN_TX_TRACK_ROLLING_COUNT 60;
BA_REL_ "GenSigTimeoutTime" BU_SG_REL_ AF01A SG_ 1338 CAN_TX_TRACK_RANGE_RATE 60;
BA_REL_ "GenSigTimeoutTime" BU_SG_REL_ AF01A SG_ 1338 CAN_TX_TRACK_RANGE_ACCEL 60;
BA_REL_ "GenSigTimeoutTime" BU_SG_REL_ AF01A SG_ 1338 CAN_TX_TRACK_RANGE 60;
BA_REL_ "GenSigTimeoutTime" BU_SG_REL_ AF01A SG_ 1338 CAN_TX_TRACK_ONCOMING 60;
BA_REL_ "GenSigTimeoutTime" BU_SG_REL_ AF01A SG_ 1338 CAN_TX_TRACK_MED_RANGE_MODE 60;
BA_REL_ "GenSigTimeoutTime" BU_SG_REL_ AF01A SG_ 1338 CAN_TX_TRACK_LAT_RATE 60;
BA_REL_ "GenSigTimeoutTime" BU_SG_REL_ AF01A SG_ 1338 CAN_TX_TRACK_GROUPING_CHANGED 60;
BA_REL_ "GenSigTimeoutTime" BU_SG_REL_ AF01A SG_ 1338 CAN_TX_TRACK_BRIDGE_OBJECT 60;
BA_REL_ "GenSigTimeoutTime" BU_SG_REL_ AF01A SG_ 1338 CAN_TX_TRACK_ANGLE 60;
BA_REL_ "GenSigTimeoutTime" BU_SG_REL_ AF01A SG_ 1337 CAN_TX_TRACK_WIDTH 60;
BA_REL_ "GenSigTimeoutTime" BU_SG_REL_ AF01A SG_ 1337 CAN_TX_TRACK_STATUS 60;
BA_REL_ "GenSigTimeoutTime" BU_SG_REL_ AF01A SG_ 1337 CAN_TX_TRACK_ROLLING_COUNT 60;
BA_REL_ "GenSigTimeoutTime" BU_SG_REL_ AF01A SG_ 1337 CAN_TX_TRACK_RANGE_RATE 60;
BA_REL_ "GenSigTimeoutTime" BU_SG_REL_ AF01A SG_ 1337 CAN_TX_TRACK_RANGE_ACCEL 60;
BA_REL_ "GenSigTimeoutTime" BU_SG_REL_ AF01A SG_ 1337 CAN_TX_TRACK_RANGE 60;
BA_REL_ "GenSigTimeoutTime" BU_SG_REL_ AF01A SG_ 1337 CAN_TX_TRACK_ONCOMING 60;
BA_REL_ "GenSigTimeoutTime" BU_SG_REL_ AF01A SG_ 1337 CAN_TX_TRACK_MED_RANGE_MODE 60;
BA_REL_ "GenSigTimeoutTime" BU_SG_REL_ AF01A SG_ 1337 CAN_TX_TRACK_LAT_RATE 60;
BA_REL_ "GenSigTimeoutTime" BU_SG_REL_ AF01A SG_ 1337 CAN_TX_TRACK_GROUPING_CHANGED 60;
BA_REL_ "GenSigTimeoutTime" BU_SG_REL_ AF01A SG_ 1337 CAN_TX_TRACK_BRIDGE_OBJECT 60;
BA_REL_ "GenSigTimeoutTime" BU_SG_REL_ AF01A SG_ 1337 CAN_TX_TRACK_ANGLE 60;
BA_REL_ "GenSigTimeoutTime" BU_SG_REL_ AF01A SG_ 1336 CAN_TX_TRACK_WIDTH 60;
BA_REL_ "GenSigTimeoutTime" BU_SG_REL_ AF01A SG_ 1336 CAN_TX_TRACK_STATUS 60;
BA_REL_ "GenSigTimeoutTime" BU_SG_REL_ AF01A SG_ 1336 CAN_TX_TRACK_ROLLING_COUNT 60;
BA_REL_ "GenSigTimeoutTime" BU_SG_REL_ AF01A SG_ 1336 CAN_TX_TRACK_RANGE_RATE 60;
BA_REL_ "GenSigTimeoutTime" BU_SG_REL_ AF01A SG_ 1336 CAN_TX_TRACK_RANGE_ACCEL 60;
BA_REL_ "GenSigTimeoutTime" BU_SG_REL_ AF01A SG_ 1336 CAN_TX_TRACK_RANGE 60;
BA_REL_ "GenSigTimeoutTime" BU_SG_REL_ AF01A SG_ 1336 CAN_TX_TRACK_ONCOMING 60;
BA_REL_ "GenSigTimeoutTime" BU_SG_REL_ AF01A SG_ 1336 CAN_TX_TRACK_MED_RANGE_MODE 60;
BA_REL_ "GenSigTimeoutTime" BU_SG_REL_ AF01A SG_ 1336 CAN_TX_TRACK_LAT_RATE 60;
BA_REL_ "GenSigTimeoutTime" BU_SG_REL_ AF01A SG_ 1336 CAN_TX_TRACK_GROUPING_CHANGED 60;
BA_REL_ "GenSigTimeoutTime" BU_SG_REL_ AF01A SG_ 1336 CAN_TX_TRACK_BRIDGE_OBJECT 60;
BA_REL_ "GenSigTimeoutTime" BU_SG_REL_ AF01A SG_ 1336 CAN_TX_TRACK_ANGLE 60;
BA_REL_ "GenSigTimeoutTime" BU_SG_REL_ AF01A SG_ 1335 CAN_TX_TRACK_WIDTH 60;
BA_REL_ "GenSigTimeoutTime" BU_SG_REL_ AF01A SG_ 1335 CAN_TX_TRACK_STATUS 60;
BA_REL_ "GenSigTimeoutTime" BU_SG_REL_ AF01A SG_ 1335 CAN_TX_TRACK_ROLLING_COUNT 60;
BA_REL_ "GenSigTimeoutTime" BU_SG_REL_ AF01A SG_ 1335 CAN_TX_TRACK_RANGE_RATE 60;
BA_REL_ "GenSigTimeoutTime" BU_SG_REL_ AF01A SG_ 1335 CAN_TX_TRACK_RANGE_ACCEL 60;
BA_REL_ "GenSigTimeoutTime" BU_SG_REL_ AF01A SG_ 1335 CAN_TX_TRACK_RANGE 60;
BA_REL_ "GenSigTimeoutTime" BU_SG_REL_ AF01A SG_ 1335 CAN_TX_TRACK_ONCOMING 60;
BA_REL_ "GenSigTimeoutTime" BU_SG_REL_ AF01A SG_ 1335 CAN_TX_TRACK_MED_RANGE_MODE 60;
BA_REL_ "GenSigTimeoutTime" BU_SG_REL_ AF01A SG_ 1335 CAN_TX_TRACK_LAT_RATE 60;
BA_REL_ "GenSigTimeoutTime" BU_SG_REL_ AF01A SG_ 1335 CAN_TX_TRACK_GROUPING_CHANGED 60;
BA_REL_ "GenSigTimeoutTime" BU_SG_REL_ AF01A SG_ 1335 CAN_TX_TRACK_BRIDGE_OBJECT 60;
BA_REL_ "GenSigTimeoutTime" BU_SG_REL_ AF01A SG_ 1335 CAN_TX_TRACK_ANGLE 60;
BA_REL_ "GenSigTimeoutTime" BU_SG_REL_ AF01A SG_ 1334 CAN_TX_TRACK_WIDTH 60;
BA_REL_ "GenSigTimeoutTime" BU_SG_REL_ AF01A SG_ 1334 CAN_TX_TRACK_STATUS 60;
BA_REL_ "GenSigTimeoutTime" BU_SG_REL_ AF01A SG_ 1334 CAN_TX_TRACK_ROLLING_COUNT 60;
BA_REL_ "GenSigTimeoutTime" BU_SG_REL_ AF01A SG_ 1334 CAN_TX_TRACK_RANGE_RATE 60;
BA_REL_ "GenSigTimeoutTime" BU_SG_REL_ AF01A SG_ 1334 CAN_TX_TRACK_RANGE_ACCEL 60;
BA_REL_ "GenSigTimeoutTime" BU_SG_REL_ AF01A SG_ 1334 CAN_TX_TRACK_RANGE 60;
BA_REL_ "GenSigTimeoutTime" BU_SG_REL_ AF01A SG_ 1334 CAN_TX_TRACK_ONCOMING 60;
BA_REL_ "GenSigTimeoutTime" BU_SG_REL_ AF01A SG_ 1334 CAN_TX_TRACK_MED_RANGE_MODE 60;
BA_REL_ "GenSigTimeoutTime" BU_SG_REL_ AF01A SG_ 1334 CAN_TX_TRACK_LAT_RATE 60;
BA_REL_ "GenSigTimeoutTime" BU_SG_REL_ AF01A SG_ 1334 CAN_TX_TRACK_GROUPING_CHANGED 60;
BA_REL_ "GenSigTimeoutTime" BU_SG_REL_ AF01A SG_ 1334 CAN_TX_TRACK_BRIDGE_OBJECT 60;
BA_REL_ "GenSigTimeoutTime" BU_SG_REL_ AF01A SG_ 1334 CAN_TX_TRACK_ANGLE 60;
BA_REL_ "GenSigTimeoutTime" BU_SG_REL_ AF01A SG_ 1333 CAN_TX_TRACK_WIDTH 60;
BA_REL_ "GenSigTimeoutTime" BU_SG_REL_ AF01A SG_ 1333 CAN_TX_TRACK_STATUS 60;
BA_REL_ "GenSigTimeoutTime" BU_SG_REL_ AF01A SG_ 1333 CAN_TX_TRACK_ROLLING_COUNT 60;
BA_REL_ "GenSigTimeoutTime" BU_SG_REL_ AF01A SG_ 1333 CAN_TX_TRACK_RANGE_RATE 60;
BA_REL_ "GenSigTimeoutTime" BU_SG_REL_ AF01A SG_ 1333 CAN_TX_TRACK_RANGE_ACCEL 60;
BA_REL_ "GenSigTimeoutTime" BU_SG_REL_ AF01A SG_ 1333 CAN_TX_TRACK_RANGE 60;
BA_REL_ "GenSigTimeoutTime" BU_SG_REL_ AF01A SG_ 1333 CAN_TX_TRACK_ONCOMING 60;
BA_REL_ "GenSigTimeoutTime" BU_SG_REL_ AF01A SG_ 1333 CAN_TX_TRACK_MED_RANGE_MODE 60;
BA_REL_ "GenSigTimeoutTime" BU_SG_REL_ AF01A SG_ 1333 CAN_TX_TRACK_LAT_RATE 60;
BA_REL_ "GenSigTimeoutTime" BU_SG_REL_ AF01A SG_ 1333 CAN_TX_TRACK_GROUPING_CHANGED 60;
BA_REL_ "GenSigTimeoutTime" BU_SG_REL_ AF01A SG_ 1333 CAN_TX_TRACK_BRIDGE_OBJECT 60;
BA_REL_ "GenSigTimeoutTime" BU_SG_REL_ AF01A SG_ 1333 CAN_TX_TRACK_ANGLE 60;
BA_REL_ "GenSigTimeoutTime" BU_SG_REL_ AF01A SG_ 1332 CAN_TX_TRACK_WIDTH 60;
BA_REL_ "GenSigTimeoutTime" BU_SG_REL_ AF01A SG_ 1332 CAN_TX_TRACK_STATUS 60;
BA_REL_ "GenSigTimeoutTime" BU_SG_REL_ AF01A SG_ 1332 CAN_TX_TRACK_ROLLING_COUNT 60;
BA_REL_ "GenSigTimeoutTime" BU_SG_REL_ AF01A SG_ 1332 CAN_TX_TRACK_RANGE_RATE 60;
BA_REL_ "GenSigTimeoutTime" BU_SG_REL_ AF01A SG_ 1332 CAN_TX_TRACK_RANGE_ACCEL 60;
BA_REL_ "GenSigTimeoutTime" BU_SG_REL_ AF01A SG_ 1332 CAN_TX_TRACK_RANGE 60;
BA_REL_ "GenSigTimeoutTime" BU_SG_REL_ AF01A SG_ 1332 CAN_TX_TRACK_ONCOMING 60;
BA_REL_ "GenSigTimeoutTime" BU_SG_REL_ AF01A SG_ 1332 CAN_TX_TRACK_MED_RANGE_MODE 60;
BA_REL_ "GenSigTimeoutTime" BU_SG_REL_ AF01A SG_ 1332 CAN_TX_TRACK_LAT_RATE 60;
BA_REL_ "GenSigTimeoutTime" BU_SG_REL_ AF01A SG_ 1332 CAN_TX_TRACK_GROUPING_CHANGED 60;
BA_REL_ "GenSigTimeoutTime" BU_SG_REL_ AF01A SG_ 1332 CAN_TX_TRACK_BRIDGE_OBJECT 60;
BA_REL_ "GenSigTimeoutTime" BU_SG_REL_ AF01A SG_ 1332 CAN_TX_TRACK_ANGLE 60;
BA_REL_ "GenSigTimeoutTime" BU_SG_REL_ AF01A SG_ 1331 CAN_TX_TRACK_WIDTH 60;
BA_REL_ "GenSigTimeoutTime" BU_SG_REL_ AF01A SG_ 1331 CAN_TX_TRACK_STATUS 60;
BA_REL_ "GenSigTimeoutTime" BU_SG_REL_ AF01A SG_ 1331 CAN_TX_TRACK_ROLLING_COUNT 60;
BA_REL_ "GenSigTimeoutTime" BU_SG_REL_ AF01A SG_ 1331 CAN_TX_TRACK_RANGE_RATE 60;
BA_REL_ "GenSigTimeoutTime" BU_SG_REL_ AF01A SG_ 1331 CAN_TX_TRACK_RANGE_ACCEL 60;
BA_REL_ "GenSigTimeoutTime" BU_SG_REL_ AF01A SG_ 1331 CAN_TX_TRACK_RANGE 60;
BA_REL_ "GenSigTimeoutTime" BU_SG_REL_ AF01A SG_ 1331 CAN_TX_TRACK_ONCOMING 60;
BA_REL_ "GenSigTimeoutTime" BU_SG_REL_ AF01A SG_ 1331 CAN_TX_TRACK_MED_RANGE_MODE 60;
BA_REL_ "GenSigTimeoutTime" BU_SG_REL_ AF01A SG_ 1331 CAN_TX_TRACK_LAT_RATE 60;
BA_REL_ "GenSigTimeoutTime" BU_SG_REL_ AF01A SG_ 1331 CAN_TX_TRACK_GROUPING_CHANGED 60;
BA_REL_ "GenSigTimeoutTime" BU_SG_REL_ AF01A SG_ 1331 CAN_TX_TRACK_BRIDGE_OBJECT 60;
BA_REL_ "GenSigTimeoutTime" BU_SG_REL_ AF01A SG_ 1331 CAN_TX_TRACK_ANGLE 60;
BA_REL_ "GenSigTimeoutTime" BU_SG_REL_ AF01A SG_ 1330 CAN_TX_TRACK_WIDTH 60;
BA_REL_ "GenSigTimeoutTime" BU_SG_REL_ AF01A SG_ 1330 CAN_TX_TRACK_STATUS 60;
BA_REL_ "GenSigTimeoutTime" BU_SG_REL_ AF01A SG_ 1330 CAN_TX_TRACK_ROLLING_COUNT 60;
BA_REL_ "GenSigTimeoutTime" BU_SG_REL_ AF01A SG_ 1330 CAN_TX_TRACK_RANGE_RATE 60;
BA_REL_ "GenSigTimeoutTime" BU_SG_REL_ AF01A SG_ 1330 CAN_TX_TRACK_RANGE_ACCEL 60;
BA_REL_ "GenSigTimeoutTime" BU_SG_REL_ AF01A SG_ 1330 CAN_TX_TRACK_RANGE 60;
BA_REL_ "GenSigTimeoutTime" BU_SG_REL_ AF01A SG_ 1330 CAN_TX_TRACK_ONCOMING 60;
BA_REL_ "GenSigTimeoutTime" BU_SG_REL_ AF01A SG_ 1330 CAN_TX_TRACK_MED_RANGE_MODE 60;
BA_REL_ "GenSigTimeoutTime" BU_SG_REL_ AF01A SG_ 1330 CAN_TX_TRACK_LAT_RATE 60;
BA_REL_ "GenSigTimeoutTime" BU_SG_REL_ AF01A SG_ 1330 CAN_TX_TRACK_GROUPING_CHANGED 60;
BA_REL_ "GenSigTimeoutTime" BU_SG_REL_ AF01A SG_ 1330 CAN_TX_TRACK_BRIDGE_OBJECT 60;
BA_REL_ "GenSigTimeoutTime" BU_SG_REL_ AF01A SG_ 1330 CAN_TX_TRACK_ANGLE 60;
BA_REL_ "GenSigTimeoutTime" BU_SG_REL_ AF01A SG_ 1329 CAN_TX_TRACK_WIDTH 60;
BA_REL_ "GenSigTimeoutTime" BU_SG_REL_ AF01A SG_ 1329 CAN_TX_TRACK_STATUS 60;
BA_REL_ "GenSigTimeoutTime" BU_SG_REL_ AF01A SG_ 1329 CAN_TX_TRACK_ROLLING_COUNT 60;
BA_REL_ "GenSigTimeoutTime" BU_SG_REL_ AF01A SG_ 1329 CAN_TX_TRACK_RANGE_RATE 60;
BA_REL_ "GenSigTimeoutTime" BU_SG_REL_ AF01A SG_ 1329 CAN_TX_TRACK_RANGE_ACCEL 60;
BA_REL_ "GenSigTimeoutTime" BU_SG_REL_ AF01A SG_ 1329 CAN_TX_TRACK_RANGE 60;
BA_REL_ "GenSigTimeoutTime" BU_SG_REL_ AF01A SG_ 1329 CAN_TX_TRACK_ONCOMING 60;
BA_REL_ "GenSigTimeoutTime" BU_SG_REL_ AF01A SG_ 1329 CAN_TX_TRACK_MED_RANGE_MODE 60;
BA_REL_ "GenSigTimeoutTime" BU_SG_REL_ AF01A SG_ 1329 CAN_TX_TRACK_LAT_RATE 60;
BA_REL_ "GenSigTimeoutTime" BU_SG_REL_ AF01A SG_ 1329 CAN_TX_TRACK_GROUPING_CHANGED 60;
BA_REL_ "GenSigTimeoutTime" BU_SG_REL_ AF01A SG_ 1329 CAN_TX_TRACK_BRIDGE_OBJECT 60;
BA_REL_ "GenSigTimeoutTime" BU_SG_REL_ AF01A SG_ 1329 CAN_TX_TRACK_ANGLE 60;
BA_REL_ "GenSigTimeoutTime" BU_SG_REL_ AF01A SG_ 1328 CAN_TX_TRACK_WIDTH 60;
BA_REL_ "GenSigTimeoutTime" BU_SG_REL_ AF01A SG_ 1328 CAN_TX_TRACK_STATUS 60;
BA_REL_ "GenSigTimeoutTime" BU_SG_REL_ AF01A SG_ 1328 CAN_TX_TRACK_ROLLING_COUNT 60;
BA_REL_ "GenSigTimeoutTime" BU_SG_REL_ AF01A SG_ 1328 CAN_TX_TRACK_RANGE_RATE 60;
BA_REL_ "GenSigTimeoutTime" BU_SG_REL_ AF01A SG_ 1328 CAN_TX_TRACK_RANGE_ACCEL 60;
BA_REL_ "GenSigTimeoutTime" BU_SG_REL_ AF01A SG_ 1328 CAN_TX_TRACK_RANGE 60;
BA_REL_ "GenSigTimeoutTime" BU_SG_REL_ AF01A SG_ 1328 CAN_TX_TRACK_ONCOMING 60;
BA_REL_ "GenSigTimeoutTime" BU_SG_REL_ AF01A SG_ 1328 CAN_TX_TRACK_MED_RANGE_MODE 60;
BA_REL_ "GenSigTimeoutTime" BU_SG_REL_ AF01A SG_ 1328 CAN_TX_TRACK_LAT_RATE 60;
BA_REL_ "GenSigTimeoutTime" BU_SG_REL_ AF01A SG_ 1328 CAN_TX_TRACK_GROUPING_CHANGED 60;
BA_REL_ "GenSigTimeoutTime" BU_SG_REL_ AF01A SG_ 1328 CAN_TX_TRACK_BRIDGE_OBJECT 60;
BA_REL_ "GenSigTimeoutTime" BU_SG_REL_ AF01A SG_ 1328 CAN_TX_TRACK_ANGLE 60;
BA_REL_ "GenSigTimeoutTime" BU_SG_REL_ AF01A SG_ 1327 CAN_TX_TRACK_WIDTH 60;
BA_REL_ "GenSigTimeoutTime" BU_SG_REL_ AF01A SG_ 1327 CAN_TX_TRACK_STATUS 60;
BA_REL_ "GenSigTimeoutTime" BU_SG_REL_ AF01A SG_ 1327 CAN_TX_TRACK_ROLLING_COUNT 60;
BA_REL_ "GenSigTimeoutTime" BU_SG_REL_ AF01A SG_ 1327 CAN_TX_TRACK_RANGE_RATE 60;
BA_REL_ "GenSigTimeoutTime" BU_SG_REL_ AF01A SG_ 1327 CAN_TX_TRACK_RANGE_ACCEL 60;
BA_REL_ "GenSigTimeoutTime" BU_SG_REL_ AF01A SG_ 1327 CAN_TX_TRACK_RANGE 60;
BA_REL_ "GenSigTimeoutTime" BU_SG_REL_ AF01A SG_ 1327 CAN_TX_TRACK_ONCOMING 60;
BA_REL_ "GenSigTimeoutTime" BU_SG_REL_ AF01A SG_ 1327 CAN_TX_TRACK_MED_RANGE_MODE 60;
BA_REL_ "GenSigTimeoutTime" BU_SG_REL_ AF01A SG_ 1327 CAN_TX_TRACK_LAT_RATE 60;
BA_REL_ "GenSigTimeoutTime" BU_SG_REL_ AF01A SG_ 1327 CAN_TX_TRACK_GROUPING_CHANGED 60;
BA_REL_ "GenSigTimeoutTime" BU_SG_REL_ AF01A SG_ 1327 CAN_TX_TRACK_BRIDGE_OBJECT 60;
BA_REL_ "GenSigTimeoutTime" BU_SG_REL_ AF01A SG_ 1327 CAN_TX_TRACK_ANGLE 60;
BA_REL_ "GenSigTimeoutTime" BU_SG_REL_ AF01A SG_ 1326 CAN_TX_TRACK_WIDTH 60;
BA_REL_ "GenSigTimeoutTime" BU_SG_REL_ AF01A SG_ 1326 CAN_TX_TRACK_STATUS 60;
BA_REL_ "GenSigTimeoutTime" BU_SG_REL_ AF01A SG_ 1326 CAN_TX_TRACK_ROLLING_COUNT 60;
BA_REL_ "GenSigTimeoutTime" BU_SG_REL_ AF01A SG_ 1326 CAN_TX_TRACK_RANGE_RATE 60;
BA_REL_ "GenSigTimeoutTime" BU_SG_REL_ AF01A SG_ 1326 CAN_TX_TRACK_RANGE_ACCEL 60;
BA_REL_ "GenSigTimeoutTime" BU_SG_REL_ AF01A SG_ 1326 CAN_TX_TRACK_RANGE 60;
BA_REL_ "GenSigTimeoutTime" BU_SG_REL_ AF01A SG_ 1326 CAN_TX_TRACK_ONCOMING 60;
BA_REL_ "GenSigTimeoutTime" BU_SG_REL_ AF01A SG_ 1326 CAN_TX_TRACK_MED_RANGE_MODE 60;
BA_REL_ "GenSigTimeoutTime" BU_SG_REL_ AF01A SG_ 1326 CAN_TX_TRACK_LAT_RATE 60;
BA_REL_ "GenSigTimeoutTime" BU_SG_REL_ AF01A SG_ 1326 CAN_TX_TRACK_GROUPING_CHANGED 60;
BA_REL_ "GenSigTimeoutTime" BU_SG_REL_ AF01A SG_ 1326 CAN_TX_TRACK_BRIDGE_OBJECT 60;
BA_REL_ "GenSigTimeoutTime" BU_SG_REL_ AF01A SG_ 1326 CAN_TX_TRACK_ANGLE 60;
BA_REL_ "GenSigTimeoutTime" BU_SG_REL_ AF01A SG_ 1325 CAN_TX_TRACK_WIDTH 60;
BA_REL_ "GenSigTimeoutTime" BU_SG_REL_ AF01A SG_ 1325 CAN_TX_TRACK_STATUS 60;
BA_REL_ "GenSigTimeoutTime" BU_SG_REL_ AF01A SG_ 1325 CAN_TX_TRACK_ROLLING_COUNT 60;
BA_REL_ "GenSigTimeoutTime" BU_SG_REL_ AF01A SG_ 1325 CAN_TX_TRACK_RANGE_RATE 60;
BA_REL_ "GenSigTimeoutTime" BU_SG_REL_ AF01A SG_ 1325 CAN_TX_TRACK_RANGE_ACCEL 60;
BA_REL_ "GenSigTimeoutTime" BU_SG_REL_ AF01A SG_ 1325 CAN_TX_TRACK_RANGE 60;
BA_REL_ "GenSigTimeoutTime" BU_SG_REL_ AF01A SG_ 1325 CAN_TX_TRACK_ONCOMING 60;
BA_REL_ "GenSigTimeoutTime" BU_SG_REL_ AF01A SG_ 1325 CAN_TX_TRACK_MED_RANGE_MODE 60;
BA_REL_ "GenSigTimeoutTime" BU_SG_REL_ AF01A SG_ 1325 CAN_TX_TRACK_LAT_RATE 60;
BA_REL_ "GenSigTimeoutTime" BU_SG_REL_ AF01A SG_ 1325 CAN_TX_TRACK_GROUPING_CHANGED 60;
BA_REL_ "GenSigTimeoutTime" BU_SG_REL_ AF01A SG_ 1325 CAN_TX_TRACK_BRIDGE_OBJECT 60;
BA_REL_ "GenSigTimeoutTime" BU_SG_REL_ AF01A SG_ 1325 CAN_TX_TRACK_ANGLE 60;
BA_REL_ "GenSigTimeoutTime" BU_SG_REL_ AF01A SG_ 1324 CAN_TX_TRACK_WIDTH 60;
BA_REL_ "GenSigTimeoutTime" BU_SG_REL_ AF01A SG_ 1324 CAN_TX_TRACK_STATUS 60;
BA_REL_ "GenSigTimeoutTime" BU_SG_REL_ AF01A SG_ 1324 CAN_TX_TRACK_ROLLING_COUNT 60;
BA_REL_ "GenSigTimeoutTime" BU_SG_REL_ AF01A SG_ 1324 CAN_TX_TRACK_RANGE_RATE 60;
BA_REL_ "GenSigTimeoutTime" BU_SG_REL_ AF01A SG_ 1324 CAN_TX_TRACK_RANGE_ACCEL 60;
BA_REL_ "GenSigTimeoutTime" BU_SG_REL_ AF01A SG_ 1324 CAN_TX_TRACK_RANGE 60;
BA_REL_ "GenSigTimeoutTime" BU_SG_REL_ AF01A SG_ 1324 CAN_TX_TRACK_ONCOMING 60;
BA_REL_ "GenSigTimeoutTime" BU_SG_REL_ AF01A SG_ 1324 CAN_TX_TRACK_MED_RANGE_MODE 60;
BA_REL_ "GenSigTimeoutTime" BU_SG_REL_ AF01A SG_ 1324 CAN_TX_TRACK_LAT_RATE 60;
BA_REL_ "GenSigTimeoutTime" BU_SG_REL_ AF01A SG_ 1324 CAN_TX_TRACK_GROUPING_CHANGED 60;
BA_REL_ "GenSigTimeoutTime" BU_SG_REL_ AF01A SG_ 1324 CAN_TX_TRACK_BRIDGE_OBJECT 60;
BA_REL_ "GenSigTimeoutTime" BU_SG_REL_ AF01A SG_ 1324 CAN_TX_TRACK_ANGLE 60;
BA_REL_ "GenSigTimeoutTime" BU_SG_REL_ AF01A SG_ 1323 CAN_TX_TRACK_WIDTH 60;
BA_REL_ "GenSigTimeoutTime" BU_SG_REL_ AF01A SG_ 1323 CAN_TX_TRACK_STATUS 60;
BA_REL_ "GenSigTimeoutTime" BU_SG_REL_ AF01A SG_ 1323 CAN_TX_TRACK_ROLLING_COUNT 60;
BA_REL_ "GenSigTimeoutTime" BU_SG_REL_ AF01A SG_ 1323 CAN_TX_TRACK_RANGE_RATE 60;
BA_REL_ "GenSigTimeoutTime" BU_SG_REL_ AF01A SG_ 1323 CAN_TX_TRACK_RANGE_ACCEL 60;
BA_REL_ "GenSigTimeoutTime" BU_SG_REL_ AF01A SG_ 1323 CAN_TX_TRACK_RANGE 60;
BA_REL_ "GenSigTimeoutTime" BU_SG_REL_ AF01A SG_ 1323 CAN_TX_TRACK_ONCOMING 60;
BA_REL_ "GenSigTimeoutTime" BU_SG_REL_ AF01A SG_ 1323 CAN_TX_TRACK_MED_RANGE_MODE 60;
BA_REL_ "GenSigTimeoutTime" BU_SG_REL_ AF01A SG_ 1323 CAN_TX_TRACK_LAT_RATE 60;
BA_REL_ "GenSigTimeoutTime" BU_SG_REL_ AF01A SG_ 1323 CAN_TX_TRACK_GROUPING_CHANGED 60;
BA_REL_ "GenSigTimeoutTime" BU_SG_REL_ AF01A SG_ 1323 CAN_TX_TRACK_BRIDGE_OBJECT 60;
BA_REL_ "GenSigTimeoutTime" BU_SG_REL_ AF01A SG_ 1323 CAN_TX_TRACK_ANGLE 60;
BA_REL_ "GenSigTimeoutTime" BU_SG_REL_ AF01A SG_ 1322 CAN_TX_TRACK_WIDTH 60;
BA_REL_ "GenSigTimeoutTime" BU_SG_REL_ AF01A SG_ 1322 CAN_TX_TRACK_STATUS 60;
BA_REL_ "GenSigTimeoutTime" BU_SG_REL_ AF01A SG_ 1322 CAN_TX_TRACK_ROLLING_COUNT 60;
BA_REL_ "GenSigTimeoutTime" BU_SG_REL_ AF01A SG_ 1322 CAN_TX_TRACK_RANGE_RATE 60;
BA_REL_ "GenSigTimeoutTime" BU_SG_REL_ AF01A SG_ 1322 CAN_TX_TRACK_RANGE_ACCEL 60;
BA_REL_ "GenSigTimeoutTime" BU_SG_REL_ AF01A SG_ 1322 CAN_TX_TRACK_RANGE 60;
BA_REL_ "GenSigTimeoutTime" BU_SG_REL_ AF01A SG_ 1322 CAN_TX_TRACK_ONCOMING 60;
BA_REL_ "GenSigTimeoutTime" BU_SG_REL_ AF01A SG_ 1322 CAN_TX_TRACK_MED_RANGE_MODE 60;
BA_REL_ "GenSigTimeoutTime" BU_SG_REL_ AF01A SG_ 1322 CAN_TX_TRACK_LAT_RATE 60;
BA_REL_ "GenSigTimeoutTime" BU_SG_REL_ AF01A SG_ 1322 CAN_TX_TRACK_GROUPING_CHANGED 60;
BA_REL_ "GenSigTimeoutTime" BU_SG_REL_ AF01A SG_ 1322 CAN_TX_TRACK_BRIDGE_OBJECT 60;
BA_REL_ "GenSigTimeoutTime" BU_SG_REL_ AF01A SG_ 1322 CAN_TX_TRACK_ANGLE 60;
BA_REL_ "GenSigTimeoutTime" BU_SG_REL_ AF01A SG_ 1321 CAN_TX_TRACK_WIDTH 60;
BA_REL_ "GenSigTimeoutTime" BU_SG_REL_ AF01A SG_ 1321 CAN_TX_TRACK_STATUS 60;
BA_REL_ "GenSigTimeoutTime" BU_SG_REL_ AF01A SG_ 1321 CAN_TX_TRACK_ROLLING_COUNT 60;
BA_REL_ "GenSigTimeoutTime" BU_SG_REL_ AF01A SG_ 1321 CAN_TX_TRACK_RANGE_RATE 60;
BA_REL_ "GenSigTimeoutTime" BU_SG_REL_ AF01A SG_ 1321 CAN_TX_TRACK_RANGE_ACCEL 60;
BA_REL_ "GenSigTimeoutTime" BU_SG_REL_ AF01A SG_ 1321 CAN_TX_TRACK_RANGE 60;
BA_REL_ "GenSigTimeoutTime" BU_SG_REL_ AF01A SG_ 1321 CAN_TX_TRACK_ONCOMING 60;
BA_REL_ "GenSigTimeoutTime" BU_SG_REL_ AF01A SG_ 1321 CAN_TX_TRACK_MED_RANGE_MODE 60;
BA_REL_ "GenSigTimeoutTime" BU_SG_REL_ AF01A SG_ 1321 CAN_TX_TRACK_LAT_RATE 60;
BA_REL_ "GenSigTimeoutTime" BU_SG_REL_ AF01A SG_ 1321 CAN_TX_TRACK_GROUPING_CHANGED 60;
BA_REL_ "GenSigTimeoutTime" BU_SG_REL_ AF01A SG_ 1321 CAN_TX_TRACK_BRIDGE_OBJECT 60;
BA_REL_ "GenSigTimeoutTime" BU_SG_REL_ AF01A SG_ 1321 CAN_TX_TRACK_ANGLE 60;
BA_REL_ "GenSigTimeoutTime" BU_SG_REL_ AF01A SG_ 1320 CAN_TX_TRACK_WIDTH 60;
BA_REL_ "GenSigTimeoutTime" BU_SG_REL_ AF01A SG_ 1320 CAN_TX_TRACK_STATUS 60;
BA_REL_ "GenSigTimeoutTime" BU_SG_REL_ AF01A SG_ 1320 CAN_TX_TRACK_ROLLING_COUNT 60;
BA_REL_ "GenSigTimeoutTime" BU_SG_REL_ AF01A SG_ 1320 CAN_TX_TRACK_RANGE_RATE 60;
BA_REL_ "GenSigTimeoutTime" BU_SG_REL_ AF01A SG_ 1320 CAN_TX_TRACK_RANGE_ACCEL 60;
BA_REL_ "GenSigTimeoutTime" BU_SG_REL_ AF01A SG_ 1320 CAN_TX_TRACK_RANGE 60;
BA_REL_ "GenSigTimeoutTime" BU_SG_REL_ AF01A SG_ 1320 CAN_TX_TRACK_ONCOMING 60;
BA_REL_ "GenSigTimeoutTime" BU_SG_REL_ AF01A SG_ 1320 CAN_TX_TRACK_MED_RANGE_MODE 60;
BA_REL_ "GenSigTimeoutTime" BU_SG_REL_ AF01A SG_ 1320 CAN_TX_TRACK_LAT_RATE 60;
BA_REL_ "GenSigTimeoutTime" BU_SG_REL_ AF01A SG_ 1320 CAN_TX_TRACK_GROUPING_CHANGED 60;
BA_REL_ "GenSigTimeoutTime" BU_SG_REL_ AF01A SG_ 1320 CAN_TX_TRACK_BRIDGE_OBJECT 60;
BA_REL_ "GenSigTimeoutTime" BU_SG_REL_ AF01A SG_ 1320 CAN_TX_TRACK_ANGLE 60;
BA_REL_ "GenSigTimeoutTime" BU_SG_REL_ AF01A SG_ 1319 CAN_TX_TRACK_WIDTH 60;
BA_REL_ "GenSigTimeoutTime" BU_SG_REL_ AF01A SG_ 1319 CAN_TX_TRACK_STATUS 60;
BA_REL_ "GenSigTimeoutTime" BU_SG_REL_ AF01A SG_ 1319 CAN_TX_TRACK_ROLLING_COUNT 60;
BA_REL_ "GenSigTimeoutTime" BU_SG_REL_ AF01A SG_ 1319 CAN_TX_TRACK_RANGE_RATE 60;
BA_REL_ "GenSigTimeoutTime" BU_SG_REL_ AF01A SG_ 1319 CAN_TX_TRACK_RANGE_ACCEL 60;
BA_REL_ "GenSigTimeoutTime" BU_SG_REL_ AF01A SG_ 1319 CAN_TX_TRACK_RANGE 60;
BA_REL_ "GenSigTimeoutTime" BU_SG_REL_ AF01A SG_ 1319 CAN_TX_TRACK_ONCOMING 60;
BA_REL_ "GenSigTimeoutTime" BU_SG_REL_ AF01A SG_ 1319 CAN_TX_TRACK_MED_RANGE_MODE 60;
BA_REL_ "GenSigTimeoutTime" BU_SG_REL_ AF01A SG_ 1319 CAN_TX_TRACK_LAT_RATE 60;
BA_REL_ "GenSigTimeoutTime" BU_SG_REL_ AF01A SG_ 1319 CAN_TX_TRACK_GROUPING_CHANGED 60;
BA_REL_ "GenSigTimeoutTime" BU_SG_REL_ AF01A SG_ 1319 CAN_TX_TRACK_BRIDGE_OBJECT 60;
BA_REL_ "GenSigTimeoutTime" BU_SG_REL_ AF01A SG_ 1319 CAN_TX_TRACK_ANGLE 60;
BA_REL_ "GenSigTimeoutTime" BU_SG_REL_ AF01A SG_ 1318 CAN_TX_TRACK_WIDTH 60;
BA_REL_ "GenSigTimeoutTime" BU_SG_REL_ AF01A SG_ 1318 CAN_TX_TRACK_STATUS 60;
BA_REL_ "GenSigTimeoutTime" BU_SG_REL_ AF01A SG_ 1318 CAN_TX_TRACK_ROLLING_COUNT 60;
BA_REL_ "GenSigTimeoutTime" BU_SG_REL_ AF01A SG_ 1318 CAN_TX_TRACK_RANGE_RATE 60;
BA_REL_ "GenSigTimeoutTime" BU_SG_REL_ AF01A SG_ 1318 CAN_TX_TRACK_RANGE_ACCEL 60;
BA_REL_ "GenSigTimeoutTime" BU_SG_REL_ AF01A SG_ 1318 CAN_TX_TRACK_RANGE 60;
BA_REL_ "GenSigTimeoutTime" BU_SG_REL_ AF01A SG_ 1318 CAN_TX_TRACK_ONCOMING 60;
BA_REL_ "GenSigTimeoutTime" BU_SG_REL_ AF01A SG_ 1318 CAN_TX_TRACK_MED_RANGE_MODE 60;
BA_REL_ "GenSigTimeoutTime" BU_SG_REL_ AF01A SG_ 1318 CAN_TX_TRACK_LAT_RATE 60;
BA_REL_ "GenSigTimeoutTime" BU_SG_REL_ AF01A SG_ 1318 CAN_TX_TRACK_GROUPING_CHANGED 60;
BA_REL_ "GenSigTimeoutTime" BU_SG_REL_ AF01A SG_ 1318 CAN_TX_TRACK_BRIDGE_OBJECT 60;
BA_REL_ "GenSigTimeoutTime" BU_SG_REL_ AF01A SG_ 1318 CAN_TX_TRACK_ANGLE 60;
BA_REL_ "GenSigTimeoutTime" BU_SG_REL_ AF01A SG_ 1317 CAN_TX_TRACK_WIDTH 60;
BA_REL_ "GenSigTimeoutTime" BU_SG_REL_ AF01A SG_ 1317 CAN_TX_TRACK_STATUS 60;
BA_REL_ "GenSigTimeoutTime" BU_SG_REL_ AF01A SG_ 1317 CAN_TX_TRACK_ROLLING_COUNT 60;
BA_REL_ "GenSigTimeoutTime" BU_SG_REL_ AF01A SG_ 1317 CAN_TX_TRACK_RANGE_RATE 60;
BA_REL_ "GenSigTimeoutTime" BU_SG_REL_ AF01A SG_ 1317 CAN_TX_TRACK_RANGE_ACCEL 60;
BA_REL_ "GenSigTimeoutTime" BU_SG_REL_ AF01A SG_ 1317 CAN_TX_TRACK_RANGE 60;
BA_REL_ "GenSigTimeoutTime" BU_SG_REL_ AF01A SG_ 1317 CAN_TX_TRACK_ONCOMING 60;
BA_REL_ "GenSigTimeoutTime" BU_SG_REL_ AF01A SG_ 1317 CAN_TX_TRACK_MED_RANGE_MODE 60;
BA_REL_ "GenSigTimeoutTime" BU_SG_REL_ AF01A SG_ 1317 CAN_TX_TRACK_LAT_RATE 60;
BA_REL_ "GenSigTimeoutTime" BU_SG_REL_ AF01A SG_ 1317 CAN_TX_TRACK_GROUPING_CHANGED 60;
BA_REL_ "GenSigTimeoutTime" BU_SG_REL_ AF01A SG_ 1317 CAN_TX_TRACK_BRIDGE_OBJECT 60;
BA_REL_ "GenSigTimeoutTime" BU_SG_REL_ AF01A SG_ 1317 CAN_TX_TRACK_ANGLE 60;
BA_REL_ "GenSigTimeoutTime" BU_SG_REL_ AF01A SG_ 1316 CAN_TX_TRACK_WIDTH 60;
BA_REL_ "GenSigTimeoutTime" BU_SG_REL_ AF01A SG_ 1316 CAN_TX_TRACK_STATUS 60;
BA_REL_ "GenSigTimeoutTime" BU_SG_REL_ AF01A SG_ 1316 CAN_TX_TRACK_ROLLING_COUNT 60;
BA_REL_ "GenSigTimeoutTime" BU_SG_REL_ AF01A SG_ 1316 CAN_TX_TRACK_RANGE_RATE 60;
BA_REL_ "GenSigTimeoutTime" BU_SG_REL_ AF01A SG_ 1316 CAN_TX_TRACK_RANGE_ACCEL 60;
BA_REL_ "GenSigTimeoutTime" BU_SG_REL_ AF01A SG_ 1316 CAN_TX_TRACK_RANGE 60;
BA_REL_ "GenSigTimeoutTime" BU_SG_REL_ AF01A SG_ 1316 CAN_TX_TRACK_ONCOMING 60;
BA_REL_ "GenSigTimeoutTime" BU_SG_REL_ AF01A SG_ 1316 CAN_TX_TRACK_MED_RANGE_MODE 60;
BA_REL_ "GenSigTimeoutTime" BU_SG_REL_ AF01A SG_ 1316 CAN_TX_TRACK_LAT_RATE 60;
BA_REL_ "GenSigTimeoutTime" BU_SG_REL_ AF01A SG_ 1316 CAN_TX_TRACK_GROUPING_CHANGED 60;
BA_REL_ "GenSigTimeoutTime" BU_SG_REL_ AF01A SG_ 1316 CAN_TX_TRACK_BRIDGE_OBJECT 60;
BA_REL_ "GenSigTimeoutTime" BU_SG_REL_ AF01A SG_ 1316 CAN_TX_TRACK_ANGLE 60;
BA_REL_ "GenSigTimeoutTime" BU_SG_REL_ AF01A SG_ 1315 CAN_TX_TRACK_WIDTH 60;
BA_REL_ "GenSigTimeoutTime" BU_SG_REL_ AF01A SG_ 1315 CAN_TX_TRACK_STATUS 60;
BA_REL_ "GenSigTimeoutTime" BU_SG_REL_ AF01A SG_ 1315 CAN_TX_TRACK_ROLLING_COUNT 60;
BA_REL_ "GenSigTimeoutTime" BU_SG_REL_ AF01A SG_ 1315 CAN_TX_TRACK_RANGE_RATE 60;
BA_REL_ "GenSigTimeoutTime" BU_SG_REL_ AF01A SG_ 1315 CAN_TX_TRACK_RANGE_ACCEL 60;
BA_REL_ "GenSigTimeoutTime" BU_SG_REL_ AF01A SG_ 1315 CAN_TX_TRACK_RANGE 60;
BA_REL_ "GenSigTimeoutTime" BU_SG_REL_ AF01A SG_ 1315 CAN_TX_TRACK_ONCOMING 60;
BA_REL_ "GenSigTimeoutTime" BU_SG_REL_ AF01A SG_ 1315 CAN_TX_TRACK_MED_RANGE_MODE 60;
BA_REL_ "GenSigTimeoutTime" BU_SG_REL_ AF01A SG_ 1315 CAN_TX_TRACK_LAT_RATE 60;
BA_REL_ "GenSigTimeoutTime" BU_SG_REL_ AF01A SG_ 1315 CAN_TX_TRACK_GROUPING_CHANGED 60;
BA_REL_ "GenSigTimeoutTime" BU_SG_REL_ AF01A SG_ 1315 CAN_TX_TRACK_BRIDGE_OBJECT 60;
BA_REL_ "GenSigTimeoutTime" BU_SG_REL_ AF01A SG_ 1315 CAN_TX_TRACK_ANGLE 60;
BA_REL_ "GenSigTimeoutTime" BU_SG_REL_ AF01A SG_ 1314 CAN_TX_TRACK_WIDTH 60;
BA_REL_ "GenSigTimeoutTime" BU_SG_REL_ AF01A SG_ 1314 CAN_TX_TRACK_STATUS 60;
BA_REL_ "GenSigTimeoutTime" BU_SG_REL_ AF01A SG_ 1314 CAN_TX_TRACK_ROLLING_COUNT 60;
BA_REL_ "GenSigTimeoutTime" BU_SG_REL_ AF01A SG_ 1314 CAN_TX_TRACK_RANGE_RATE 60;
BA_REL_ "GenSigTimeoutTime" BU_SG_REL_ AF01A SG_ 1314 CAN_TX_TRACK_RANGE_ACCEL 60;
BA_REL_ "GenSigTimeoutTime" BU_SG_REL_ AF01A SG_ 1314 CAN_TX_TRACK_RANGE 60;
BA_REL_ "GenSigTimeoutTime" BU_SG_REL_ AF01A SG_ 1314 CAN_TX_TRACK_ONCOMING 60;
BA_REL_ "GenSigTimeoutTime" BU_SG_REL_ AF01A SG_ 1314 CAN_TX_TRACK_MED_RANGE_MODE 60;
BA_REL_ "GenSigTimeoutTime" BU_SG_REL_ AF01A SG_ 1314 CAN_TX_TRACK_LAT_RATE 60;
BA_REL_ "GenSigTimeoutTime" BU_SG_REL_ AF01A SG_ 1314 CAN_TX_TRACK_GROUPING_CHANGED 60;
BA_REL_ "GenSigTimeoutTime" BU_SG_REL_ AF01A SG_ 1314 CAN_TX_TRACK_BRIDGE_OBJECT 60;
BA_REL_ "GenSigTimeoutTime" BU_SG_REL_ AF01A SG_ 1314 CAN_TX_TRACK_ANGLE 60;
BA_REL_ "GenSigTimeoutTime" BU_SG_REL_ AF01A SG_ 1313 CAN_TX_TRACK_WIDTH 60;
BA_REL_ "GenSigTimeoutTime" BU_SG_REL_ AF01A SG_ 1313 CAN_TX_TRACK_STATUS 60;
BA_REL_ "GenSigTimeoutTime" BU_SG_REL_ AF01A SG_ 1313 CAN_TX_TRACK_ROLLING_COUNT 60;
BA_REL_ "GenSigTimeoutTime" BU_SG_REL_ AF01A SG_ 1313 CAN_TX_TRACK_RANGE_RATE 60;
BA_REL_ "GenSigTimeoutTime" BU_SG_REL_ AF01A SG_ 1313 CAN_TX_TRACK_RANGE_ACCEL 60;
BA_REL_ "GenSigTimeoutTime" BU_SG_REL_ AF01A SG_ 1313 CAN_TX_TRACK_RANGE 60;
BA_REL_ "GenSigTimeoutTime" BU_SG_REL_ AF01A SG_ 1313 CAN_TX_TRACK_ONCOMING 60;
BA_REL_ "GenSigTimeoutTime" BU_SG_REL_ AF01A SG_ 1313 CAN_TX_TRACK_MED_RANGE_MODE 60;
BA_REL_ "GenSigTimeoutTime" BU_SG_REL_ AF01A SG_ 1313 CAN_TX_TRACK_LAT_RATE 60;
BA_REL_ "GenSigTimeoutTime" BU_SG_REL_ AF01A SG_ 1313 CAN_TX_TRACK_GROUPING_CHANGED 60;
BA_REL_ "GenSigTimeoutTime" BU_SG_REL_ AF01A SG_ 1313 CAN_TX_TRACK_BRIDGE_OBJECT 60;
BA_REL_ "GenSigTimeoutTime" BU_SG_REL_ AF01A SG_ 1313 CAN_TX_TRACK_ANGLE 60;
BA_REL_ "GenSigTimeoutTime" BU_SG_REL_ AF01A SG_ 1312 CAN_TX_TRACK_WIDTH 60;
BA_REL_ "GenSigTimeoutTime" BU_SG_REL_ AF01A SG_ 1312 CAN_TX_TRACK_STATUS 60;
BA_REL_ "GenSigTimeoutTime" BU_SG_REL_ AF01A SG_ 1312 CAN_TX_TRACK_ROLLING_COUNT 60;
BA_REL_ "GenSigTimeoutTime" BU_SG_REL_ AF01A SG_ 1312 CAN_TX_TRACK_RANGE_RATE 60;
BA_REL_ "GenSigTimeoutTime" BU_SG_REL_ AF01A SG_ 1312 CAN_TX_TRACK_RANGE_ACCEL 60;
BA_REL_ "GenSigTimeoutTime" BU_SG_REL_ AF01A SG_ 1312 CAN_TX_TRACK_RANGE 60;
BA_REL_ "GenSigTimeoutTime" BU_SG_REL_ AF01A SG_ 1312 CAN_TX_TRACK_ONCOMING 60;
BA_REL_ "GenSigTimeoutTime" BU_SG_REL_ AF01A SG_ 1312 CAN_TX_TRACK_MED_RANGE_MODE 60;
BA_REL_ "GenSigTimeoutTime" BU_SG_REL_ AF01A SG_ 1312 CAN_TX_TRACK_LAT_RATE 60;
BA_REL_ "GenSigTimeoutTime" BU_SG_REL_ AF01A SG_ 1312 CAN_TX_TRACK_GROUPING_CHANGED 60;
BA_REL_ "GenSigTimeoutTime" BU_SG_REL_ AF01A SG_ 1312 CAN_TX_TRACK_BRIDGE_OBJECT 60;
BA_REL_ "GenSigTimeoutTime" BU_SG_REL_ AF01A SG_ 1312 CAN_TX_TRACK_ANGLE 60;
BA_REL_ "GenSigTimeoutTime" BU_SG_REL_ AF01A SG_ 1311 CAN_TX_TRACK_WIDTH 60;
BA_REL_ "GenSigTimeoutTime" BU_SG_REL_ AF01A SG_ 1311 CAN_TX_TRACK_STATUS 60;
BA_REL_ "GenSigTimeoutTime" BU_SG_REL_ AF01A SG_ 1311 CAN_TX_TRACK_ROLLING_COUNT 60;
BA_REL_ "GenSigTimeoutTime" BU_SG_REL_ AF01A SG_ 1311 CAN_TX_TRACK_RANGE_RATE 60;
BA_REL_ "GenSigTimeoutTime" BU_SG_REL_ AF01A SG_ 1311 CAN_TX_TRACK_RANGE_ACCEL 60;
BA_REL_ "GenSigTimeoutTime" BU_SG_REL_ AF01A SG_ 1311 CAN_TX_TRACK_RANGE 60;
BA_REL_ "GenSigTimeoutTime" BU_SG_REL_ AF01A SG_ 1311 CAN_TX_TRACK_ONCOMING 60;
BA_REL_ "GenSigTimeoutTime" BU_SG_REL_ AF01A SG_ 1311 CAN_TX_TRACK_MED_RANGE_MODE 60;
BA_REL_ "GenSigTimeoutTime" BU_SG_REL_ AF01A SG_ 1311 CAN_TX_TRACK_LAT_RATE 60;
BA_REL_ "GenSigTimeoutTime" BU_SG_REL_ AF01A SG_ 1311 CAN_TX_TRACK_GROUPING_CHANGED 60;
BA_REL_ "GenSigTimeoutTime" BU_SG_REL_ AF01A SG_ 1311 CAN_TX_TRACK_BRIDGE_OBJECT 60;
BA_REL_ "GenSigTimeoutTime" BU_SG_REL_ AF01A SG_ 1311 CAN_TX_TRACK_ANGLE 60;
BA_REL_ "GenSigTimeoutTime" BU_SG_REL_ AF01A SG_ 1310 CAN_TX_TRACK_WIDTH 60;
BA_REL_ "GenSigTimeoutTime" BU_SG_REL_ AF01A SG_ 1310 CAN_TX_TRACK_STATUS 60;
BA_REL_ "GenSigTimeoutTime" BU_SG_REL_ AF01A SG_ 1310 CAN_TX_TRACK_ROLLING_COUNT 60;
BA_REL_ "GenSigTimeoutTime" BU_SG_REL_ AF01A SG_ 1310 CAN_TX_TRACK_RANGE_RATE 60;
BA_REL_ "GenSigTimeoutTime" BU_SG_REL_ AF01A SG_ 1310 CAN_TX_TRACK_RANGE_ACCEL 60;
BA_REL_ "GenSigTimeoutTime" BU_SG_REL_ AF01A SG_ 1310 CAN_TX_TRACK_RANGE 60;
BA_REL_ "GenSigTimeoutTime" BU_SG_REL_ AF01A SG_ 1310 CAN_TX_TRACK_ONCOMING 60;
BA_REL_ "GenSigTimeoutTime" BU_SG_REL_ AF01A SG_ 1310 CAN_TX_TRACK_MED_RANGE_MODE 60;
BA_REL_ "GenSigTimeoutTime" BU_SG_REL_ AF01A SG_ 1310 CAN_TX_TRACK_LAT_RATE 60;
BA_REL_ "GenSigTimeoutTime" BU_SG_REL_ AF01A SG_ 1310 CAN_TX_TRACK_GROUPING_CHANGED 60;
BA_REL_ "GenSigTimeoutTime" BU_SG_REL_ AF01A SG_ 1310 CAN_TX_TRACK_BRIDGE_OBJECT 60;
BA_REL_ "GenSigTimeoutTime" BU_SG_REL_ AF01A SG_ 1310 CAN_TX_TRACK_ANGLE 60;
BA_REL_ "GenSigTimeoutTime" BU_SG_REL_ AF01A SG_ 1309 CAN_TX_TRACK_WIDTH 60;
BA_REL_ "GenSigTimeoutTime" BU_SG_REL_ AF01A SG_ 1309 CAN_TX_TRACK_STATUS 60;
BA_REL_ "GenSigTimeoutTime" BU_SG_REL_ AF01A SG_ 1309 CAN_TX_TRACK_ROLLING_COUNT 60;
BA_REL_ "GenSigTimeoutTime" BU_SG_REL_ AF01A SG_ 1309 CAN_TX_TRACK_RANGE_RATE 60;
BA_REL_ "GenSigTimeoutTime" BU_SG_REL_ AF01A SG_ 1309 CAN_TX_TRACK_RANGE_ACCEL 60;
BA_REL_ "GenSigTimeoutTime" BU_SG_REL_ AF01A SG_ 1309 CAN_TX_TRACK_RANGE 60;
BA_REL_ "GenSigTimeoutTime" BU_SG_REL_ AF01A SG_ 1309 CAN_TX_TRACK_ONCOMING 60;
BA_REL_ "GenSigTimeoutTime" BU_SG_REL_ AF01A SG_ 1309 CAN_TX_TRACK_MED_RANGE_MODE 60;
BA_REL_ "GenSigTimeoutTime" BU_SG_REL_ AF01A SG_ 1309 CAN_TX_TRACK_LAT_RATE 60;
BA_REL_ "GenSigTimeoutTime" BU_SG_REL_ AF01A SG_ 1309 CAN_TX_TRACK_GROUPING_CHANGED 60;
BA_REL_ "GenSigTimeoutTime" BU_SG_REL_ AF01A SG_ 1309 CAN_TX_TRACK_BRIDGE_OBJECT 60;
BA_REL_ "GenSigTimeoutTime" BU_SG_REL_ AF01A SG_ 1309 CAN_TX_TRACK_ANGLE 60;
BA_REL_ "GenSigTimeoutTime" BU_SG_REL_ AF01A SG_ 1308 CAN_TX_TRACK_WIDTH 60;
BA_REL_ "GenSigTimeoutTime" BU_SG_REL_ AF01A SG_ 1308 CAN_TX_TRACK_STATUS 60;
BA_REL_ "GenSigTimeoutTime" BU_SG_REL_ AF01A SG_ 1308 CAN_TX_TRACK_ROLLING_COUNT 60;
BA_REL_ "GenSigTimeoutTime" BU_SG_REL_ AF01A SG_ 1308 CAN_TX_TRACK_RANGE_RATE 60;
BA_REL_ "GenSigTimeoutTime" BU_SG_REL_ AF01A SG_ 1308 CAN_TX_TRACK_RANGE_ACCEL 60;
BA_REL_ "GenSigTimeoutTime" BU_SG_REL_ AF01A SG_ 1308 CAN_TX_TRACK_RANGE 60;
BA_REL_ "GenSigTimeoutTime" BU_SG_REL_ AF01A SG_ 1308 CAN_TX_TRACK_ONCOMING 60;
BA_REL_ "GenSigTimeoutTime" BU_SG_REL_ AF01A SG_ 1308 CAN_TX_TRACK_MED_RANGE_MODE 60;
BA_REL_ "GenSigTimeoutTime" BU_SG_REL_ AF01A SG_ 1308 CAN_TX_TRACK_LAT_RATE 60;
BA_REL_ "GenSigTimeoutTime" BU_SG_REL_ AF01A SG_ 1308 CAN_TX_TRACK_GROUPING_CHANGED 60;
BA_REL_ "GenSigTimeoutTime" BU_SG_REL_ AF01A SG_ 1308 CAN_TX_TRACK_BRIDGE_OBJECT 60;
BA_REL_ "GenSigTimeoutTime" BU_SG_REL_ AF01A SG_ 1308 CAN_TX_TRACK_ANGLE 60;
BA_REL_ "GenSigTimeoutTime" BU_SG_REL_ AF01A SG_ 1307 CAN_TX_TRACK_WIDTH 60;
BA_REL_ "GenSigTimeoutTime" BU_SG_REL_ AF01A SG_ 1307 CAN_TX_TRACK_STATUS 60;
BA_REL_ "GenSigTimeoutTime" BU_SG_REL_ AF01A SG_ 1307 CAN_TX_TRACK_ROLLING_COUNT 60;
BA_REL_ "GenSigTimeoutTime" BU_SG_REL_ AF01A SG_ 1307 CAN_TX_TRACK_RANGE_RATE 60;
BA_REL_ "GenSigTimeoutTime" BU_SG_REL_ AF01A SG_ 1307 CAN_TX_TRACK_RANGE_ACCEL 60;
BA_REL_ "GenSigTimeoutTime" BU_SG_REL_ AF01A SG_ 1307 CAN_TX_TRACK_RANGE 60;
BA_REL_ "GenSigTimeoutTime" BU_SG_REL_ AF01A SG_ 1307 CAN_TX_TRACK_ONCOMING 60;
BA_REL_ "GenSigTimeoutTime" BU_SG_REL_ AF01A SG_ 1307 CAN_TX_TRACK_MED_RANGE_MODE 60;
BA_REL_ "GenSigTimeoutTime" BU_SG_REL_ AF01A SG_ 1307 CAN_TX_TRACK_LAT_RATE 60;
BA_REL_ "GenSigTimeoutTime" BU_SG_REL_ AF01A SG_ 1307 CAN_TX_TRACK_GROUPING_CHANGED 60;
BA_REL_ "GenSigTimeoutTime" BU_SG_REL_ AF01A SG_ 1307 CAN_TX_TRACK_BRIDGE_OBJECT 60;
BA_REL_ "GenSigTimeoutTime" BU_SG_REL_ AF01A SG_ 1307 CAN_TX_TRACK_ANGLE 60;
VAL_ 273 LD_SWITCH 1 "close" 0 "open" ;
VAL_ 273 VD_SWITCH 1 "close" 0 "open" ;
VAL_ 273 PD_SWITCH 1 "close" 0 "open" ;
VAL_ 273 TSR_SWITCH 1 "close" 0 "open" ;
VAL_ 273 TRAFFIC_LIGHT_SWITCH 1 "close" 0 "open" ;
VAL_ 273 IHC_SWITCH 1 "close" 0 "open" ;
VAL_ 273 PCW_SWITCH 1 "close" 0 "open" ;
VAL_ 273 FCW_SWITCH 1 "close" 0 "open" ;
VAL_ 273 LDW_SWITCH 1 "close" 0 "open" ;
VAL_ 1509 CAN_TX_VERTICAL_ALIGN_UPDATED 1 "Updated" 0 "Not_Updated" ;
VAL_ 1509 CAN_TX_SYSTEM_POWER_MODE 7 "7invalid" 6 "TEST" 5 "HOST_SHUTDOWN" 4 "DSP_OFF'" 3 "DSP_SHUTDOWN" 2 "RADIATE_ON" 1 "RADIATE_OFF" 0 "DSP_INIT" ;
VAL_ 1509 CAN_TX_FOUND_TARGET 1 "Found" 0 "Not_Found" ;
VAL_ 1509 CAN_TX_FACTORY_ALIGN_STATUS_2 5 "FAIL_VAR_TOO_LARGE" 4 "FAIL_DEV_TOO_LARGE" 3 "FAIL_NO_TARGET" 2 "SUCCESS" 1 "BUSY" 0 "OFF" ;
VAL_ 1509 CAN_TX_FACTORY_ALIGN_STATUS_1 5 "FAIL_VAR_TOO_LARGE" 4 "FAIL_DEV_TOO_LARGE" 3 "FAIL_NO_TARGET" 2 "SUCCESS" 1 "BUSY" 0 "OFF" ;
VAL_ 1343 CAN_TX_TRACK_STATUS 7 "New_Coasted_Target" 6 "Invalid_Coasted_Target" 5 "Merged_Target" 4 "Coasted_Target" 3 "Updated_Target" 2 "New_Updated_Target" 1 "New_Target" 0 "No_Target" ;
VAL_ 1343 CAN_TX_TRACK_ONCOMING 1 "Oncoming" 0 "NotOncoming" ;
VAL_ 1343 CAN_TX_TRACK_MED_RANGE_MODE 3 "Both_MR_LR_Update" 2 "LR_Update_Only" 1 "MR_Update_Only" 0 "No_MR_LR_Update" ;
VAL_ 1343 CAN_TX_TRACK_GROUPING_CHANGED 1 "GroupingChanged" 0 "GroupingUnchanged" ;
VAL_ 1343 CAN_TX_TRACK_BRIDGE_OBJECT 1 "Bridge" 0 "Not_Bridge" ;
VAL_ 1342 CAN_TX_TRACK_STATUS 7 "New_Coasted_Target" 6 "Invalid_Coasted_Target" 5 "Merged_Target" 4 "Coasted_Target" 3 "Updated_Target" 2 "New_Updated_Target" 1 "New_Target" 0 "No_Target" ;
VAL_ 1342 CAN_TX_TRACK_ONCOMING 1 "Oncoming" 0 "NotOncoming" ;
VAL_ 1342 CAN_TX_TRACK_MED_RANGE_MODE 3 "Both_MR_LR_Update" 2 "LR_Update_Only" 1 "MR_Update_Only" 0 "No_MR_LR_Update" ;
VAL_ 1342 CAN_TX_TRACK_GROUPING_CHANGED 1 "GroupingChanged" 0 "GroupingUnchanged" ;
VAL_ 1342 CAN_TX_TRACK_BRIDGE_OBJECT 1 "Bridge" 0 "Not_Bridge" ;
VAL_ 1341 CAN_TX_TRACK_STATUS 7 "New_Coasted_Target" 6 "Invalid_Coasted_Target" 5 "Merged_Target" 4 "Coasted_Target" 3 "Updated_Target" 2 "New_Updated_Target" 1 "New_Target" 0 "No_Target" ;
VAL_ 1341 CAN_TX_TRACK_ONCOMING 1 "Oncoming" 0 "NotOncoming" ;
VAL_ 1341 CAN_TX_TRACK_MED_RANGE_MODE 3 "Both_MR_LR_Update" 2 "LR_Update_Only" 1 "MR_Update_Only" 0 "No_MR_LR_Update" ;
VAL_ 1341 CAN_TX_TRACK_GROUPING_CHANGED 1 "GroupingChanged" 0 "GroupingUnchanged" ;
VAL_ 1341 CAN_TX_TRACK_BRIDGE_OBJECT 1 "Bridge" 0 "Not_Bridge" ;
VAL_ 1340 CAN_TX_TRACK_STATUS 7 "New_Coasted_Target" 6 "Invalid_Coasted_Target" 5 "Merged_Target" 4 "Coasted_Target" 3 "Updated_Target" 2 "New_Updated_Target" 1 "New_Target" 0 "No_Target" ;
VAL_ 1340 CAN_TX_TRACK_ONCOMING 1 "Oncoming" 0 "NotOncoming" ;
VAL_ 1340 CAN_TX_TRACK_MED_RANGE_MODE 3 "Both_MR_LR_Update" 2 "LR_Update_Only" 1 "MR_Update_Only" 0 "No_MR_LR_Update" ;
VAL_ 1340 CAN_TX_TRACK_GROUPING_CHANGED 1 "GroupingChanged" 0 "GroupingUnchanged" ;
VAL_ 1340 CAN_TX_TRACK_BRIDGE_OBJECT 1 "Bridge" 0 "Not_Bridge" ;
VAL_ 1339 CAN_TX_TRACK_STATUS 7 "New_Coasted_Target" 6 "Invalid_Coasted_Target" 5 "Merged_Target" 4 "Coasted_Target" 3 "Updated_Target" 2 "New_Updated_Target" 1 "New_Target" 0 "No_Target" ;
VAL_ 1339 CAN_TX_TRACK_ONCOMING 1 "Oncoming" 0 "NotOncoming" ;
VAL_ 1339 CAN_TX_TRACK_MED_RANGE_MODE 3 "Both_MR_LR_Update" 2 "LR_Update_Only" 1 "MR_Update_Only" 0 "No_MR_LR_Update" ;
VAL_ 1339 CAN_TX_TRACK_GROUPING_CHANGED 1 "GroupingChanged" 0 "GroupingUnchanged" ;
VAL_ 1339 CAN_TX_TRACK_BRIDGE_OBJECT 1 "Bridge" 0 "Not_Bridge" ;
VAL_ 1338 CAN_TX_TRACK_STATUS 7 "New_Coasted_Target" 6 "Invalid_Coasted_Target" 5 "Merged_Target" 4 "Coasted_Target" 3 "Updated_Target" 2 "New_Updated_Target" 1 "New_Target" 0 "No_Target" ;
VAL_ 1338 CAN_TX_TRACK_ONCOMING 1 "Oncoming" 0 "NotOncoming" ;
VAL_ 1338 CAN_TX_TRACK_MED_RANGE_MODE 3 "Both_MR_LR_Update" 2 "LR_Update_Only" 1 "MR_Update_Only" 0 "No_MR_LR_Update" ;
VAL_ 1338 CAN_TX_TRACK_GROUPING_CHANGED 1 "GroupingChanged" 0 "GroupingUnchanged" ;
VAL_ 1338 CAN_TX_TRACK_BRIDGE_OBJECT 1 "Bridge" 0 "Not_Bridge" ;
VAL_ 1337 CAN_TX_TRACK_STATUS 7 "New_Coasted_Target" 6 "Invalid_Coasted_Target" 5 "Merged_Target" 4 "Coasted_Target" 3 "Updated_Target" 2 "New_Updated_Target" 1 "New_Target" 0 "No_Target" ;
VAL_ 1337 CAN_TX_TRACK_ONCOMING 1 "Oncoming" 0 "NotOncoming" ;
VAL_ 1337 CAN_TX_TRACK_MED_RANGE_MODE 3 "Both_MR_LR_Update" 2 "LR_Update_Only" 1 "MR_Update_Only" 0 "No_MR_LR_Update" ;
VAL_ 1337 CAN_TX_TRACK_GROUPING_CHANGED 1 "GroupingChanged" 0 "GroupingUnchanged" ;
VAL_ 1337 CAN_TX_TRACK_BRIDGE_OBJECT 1 "Bridge" 0 "Not_Bridge" ;
VAL_ 1336 CAN_TX_TRACK_STATUS 7 "New_Coasted_Target" 6 "Invalid_Coasted_Target" 5 "Merged_Target" 4 "Coasted_Target" 3 "Updated_Target" 2 "New_Updated_Target" 1 "New_Target" 0 "No_Target" ;
VAL_ 1336 CAN_TX_TRACK_ONCOMING 1 "Oncoming" 0 "NotOncoming" ;
VAL_ 1336 CAN_TX_TRACK_MED_RANGE_MODE 3 "Both_MR_LR_Update" 2 "LR_Update_Only" 1 "MR_Update_Only" 0 "No_MR_LR_Update" ;
VAL_ 1336 CAN_TX_TRACK_GROUPING_CHANGED 1 "GroupingChanged" 0 "GroupingUnchanged" ;
VAL_ 1336 CAN_TX_TRACK_BRIDGE_OBJECT 1 "Bridge" 0 "Not_Bridge" ;
VAL_ 1335 CAN_TX_TRACK_STATUS 7 "New_Coasted_Target" 6 "Invalid_Coasted_Target" 5 "Merged_Target" 4 "Coasted_Target" 3 "Updated_Target" 2 "New_Updated_Target" 1 "New_Target" 0 "No_Target" ;
VAL_ 1335 CAN_TX_TRACK_ONCOMING 1 "Oncoming" 0 "NotOncoming" ;
VAL_ 1335 CAN_TX_TRACK_MED_RANGE_MODE 3 "Both_MR_LR_Update" 2 "LR_Update_Only" 1 "MR_Update_Only" 0 "No_MR_LR_Update" ;
VAL_ 1335 CAN_TX_TRACK_GROUPING_CHANGED 1 "GroupingChanged" 0 "GroupingUnchanged" ;
VAL_ 1335 CAN_TX_TRACK_BRIDGE_OBJECT 1 "Bridge" 0 "Not_Bridge" ;
VAL_ 1334 CAN_TX_TRACK_STATUS 7 "New_Coasted_Target" 6 "Invalid_Coasted_Target" 5 "Merged_Target" 4 "Coasted_Target" 3 "Updated_Target" 2 "New_Updated_Target" 1 "New_Target" 0 "No_Target" ;
VAL_ 1334 CAN_TX_TRACK_ONCOMING 1 "Oncoming" 0 "NotOncoming" ;
VAL_ 1334 CAN_TX_TRACK_MED_RANGE_MODE 3 "Both_MR_LR_Update" 2 "LR_Update_Only" 1 "MR_Update_Only" 0 "No_MR_LR_Update" ;
VAL_ 1334 CAN_TX_TRACK_GROUPING_CHANGED 1 "GroupingChanged" 0 "GroupingUnchanged" ;
VAL_ 1334 CAN_TX_TRACK_BRIDGE_OBJECT 1 "Bridge" 0 "Not_Bridge" ;
VAL_ 1333 CAN_TX_TRACK_STATUS 7 "New_Coasted_Target" 6 "Invalid_Coasted_Target" 5 "Merged_Target" 4 "Coasted_Target" 3 "Updated_Target" 2 "New_Updated_Target" 1 "New_Target" 0 "No_Target" ;
VAL_ 1333 CAN_TX_TRACK_ONCOMING 1 "Oncoming" 0 "NotOncoming" ;
VAL_ 1333 CAN_TX_TRACK_MED_RANGE_MODE 3 "Both_MR_LR_Update" 2 "LR_Update_Only" 1 "MR_Update_Only" 0 "No_MR_LR_Update" ;
VAL_ 1333 CAN_TX_TRACK_GROUPING_CHANGED 1 "GroupingChanged" 0 "GroupingUnchanged" ;
VAL_ 1333 CAN_TX_TRACK_BRIDGE_OBJECT 1 "Bridge" 0 "Not_Bridge" ;
VAL_ 1332 CAN_TX_TRACK_STATUS 7 "New_Coasted_Target" 6 "Invalid_Coasted_Target" 5 "Merged_Target" 4 "Coasted_Target" 3 "Updated_Target" 2 "New_Updated_Target" 1 "New_Target" 0 "No_Target" ;
VAL_ 1332 CAN_TX_TRACK_ONCOMING 1 "Oncoming" 0 "NotOncoming" ;
VAL_ 1332 CAN_TX_TRACK_MED_RANGE_MODE 3 "Both_MR_LR_Update" 2 "LR_Update_Only" 1 "MR_Update_Only" 0 "No_MR_LR_Update" ;
VAL_ 1332 CAN_TX_TRACK_GROUPING_CHANGED 1 "GroupingChanged" 0 "GroupingUnchanged" ;
VAL_ 1332 CAN_TX_TRACK_BRIDGE_OBJECT 1 "Bridge" 0 "Not_Bridge" ;
VAL_ 1331 CAN_TX_TRACK_STATUS 7 "New_Coasted_Target" 6 "Invalid_Coasted_Target" 5 "Merged_Target" 4 "Coasted_Target" 3 "Updated_Target" 2 "New_Updated_Target" 1 "New_Target" 0 "No_Target" ;
VAL_ 1331 CAN_TX_TRACK_ONCOMING 1 "Oncoming" 0 "NotOncoming" ;
VAL_ 1331 CAN_TX_TRACK_MED_RANGE_MODE 3 "Both_MR_LR_Update" 2 "LR_Update_Only" 1 "MR_Update_Only" 0 "No_MR_LR_Update" ;
VAL_ 1331 CAN_TX_TRACK_GROUPING_CHANGED 1 "GroupingChanged" 0 "GroupingUnchanged" ;
VAL_ 1331 CAN_TX_TRACK_BRIDGE_OBJECT 1 "Bridge" 0 "Not_Bridge" ;
VAL_ 1330 CAN_TX_TRACK_STATUS 7 "New_Coasted_Target" 6 "Invalid_Coasted_Target" 5 "Merged_Target" 4 "Coasted_Target" 3 "Updated_Target" 2 "New_Updated_Target" 1 "New_Target" 0 "No_Target" ;
VAL_ 1330 CAN_TX_TRACK_ONCOMING 1 "Oncoming" 0 "NotOncoming" ;
VAL_ 1330 CAN_TX_TRACK_MED_RANGE_MODE 3 "Both_MR_LR_Update" 2 "LR_Update_Only" 1 "MR_Update_Only" 0 "No_MR_LR_Update" ;
VAL_ 1330 CAN_TX_TRACK_GROUPING_CHANGED 1 "GroupingChanged" 0 "GroupingUnchanged" ;
VAL_ 1330 CAN_TX_TRACK_BRIDGE_OBJECT 1 "Bridge" 0 "Not_Bridge" ;
VAL_ 1329 CAN_TX_TRACK_STATUS 7 "New_Coasted_Target" 6 "Invalid_Coasted_Target" 5 "Merged_Target" 4 "Coasted_Target" 3 "Updated_Target" 2 "New_Updated_Target" 1 "New_Target" 0 "No_Target" ;
VAL_ 1329 CAN_TX_TRACK_ONCOMING 1 "Oncoming" 0 "NotOncoming" ;
VAL_ 1329 CAN_TX_TRACK_MED_RANGE_MODE 3 "Both_MR_LR_Update" 2 "LR_Update_Only" 1 "MR_Update_Only" 0 "No_MR_LR_Update" ;
VAL_ 1329 CAN_TX_TRACK_GROUPING_CHANGED 1 "GroupingChanged" 0 "GroupingUnchanged" ;
VAL_ 1329 CAN_TX_TRACK_BRIDGE_OBJECT 1 "Bridge" 0 "Not_Bridge" ;
VAL_ 1328 CAN_TX_TRACK_STATUS 7 "New_Coasted_Target" 6 "Invalid_Coasted_Target" 5 "Merged_Target" 4 "Coasted_Target" 3 "Updated_Target" 2 "New_Updated_Target" 1 "New_Target" 0 "No_Target" ;
VAL_ 1328 CAN_TX_TRACK_ONCOMING 1 "Oncoming" 0 "NotOncoming" ;
VAL_ 1328 CAN_TX_TRACK_MED_RANGE_MODE 3 "Both_MR_LR_Update" 2 "LR_Update_Only" 1 "MR_Update_Only" 0 "No_MR_LR_Update" ;
VAL_ 1328 CAN_TX_TRACK_GROUPING_CHANGED 1 "GroupingChanged" 0 "GroupingUnchanged" ;
VAL_ 1328 CAN_TX_TRACK_BRIDGE_OBJECT 1 "Bridge" 0 "Not_Bridge" ;
VAL_ 1327 CAN_TX_TRACK_STATUS 7 "New_Coasted_Target" 6 "Invalid_Coasted_Target" 5 "Merged_Target" 4 "Coasted_Target" 3 "Updated_Target" 2 "New_Updated_Target" 1 "New_Target" 0 "No_Target" ;
VAL_ 1327 CAN_TX_TRACK_ONCOMING 1 "Oncoming" 0 "NotOncoming" ;
VAL_ 1327 CAN_TX_TRACK_MED_RANGE_MODE 3 "Both_MR_LR_Update" 2 "LR_Update_Only" 1 "MR_Update_Only" 0 "No_MR_LR_Update" ;
VAL_ 1327 CAN_TX_TRACK_GROUPING_CHANGED 1 "GroupingChanged" 0 "GroupingUnchanged" ;
VAL_ 1327 CAN_TX_TRACK_BRIDGE_OBJECT 1 "Bridge" 0 "Not_Bridge" ;
VAL_ 1326 CAN_TX_TRACK_STATUS 7 "New_Coasted_Target" 6 "Invalid_Coasted_Target" 5 "Merged_Target" 4 "Coasted_Target" 3 "Updated_Target" 2 "New_Updated_Target" 1 "New_Target" 0 "No_Target" ;
VAL_ 1326 CAN_TX_TRACK_ONCOMING 1 "Oncoming" 0 "NotOncoming" ;
VAL_ 1326 CAN_TX_TRACK_MED_RANGE_MODE 3 "Both_MR_LR_Update" 2 "LR_Update_Only" 1 "MR_Update_Only" 0 "No_MR_LR_Update" ;
VAL_ 1326 CAN_TX_TRACK_GROUPING_CHANGED 1 "GroupingChanged" 0 "GroupingUnchanged" ;
VAL_ 1326 CAN_TX_TRACK_BRIDGE_OBJECT 1 "Bridge" 0 "Not_Bridge" ;
VAL_ 1325 CAN_TX_TRACK_STATUS 7 "New_Coasted_Target" 6 "Invalid_Coasted_Target" 5 "Merged_Target" 4 "Coasted_Target" 3 "Updated_Target" 2 "New_Updated_Target" 1 "New_Target" 0 "No_Target" ;
VAL_ 1325 CAN_TX_TRACK_ONCOMING 1 "Oncoming" 0 "NotOncoming" ;
VAL_ 1325 CAN_TX_TRACK_MED_RANGE_MODE 3 "Both_MR_LR_Update" 2 "LR_Update_Only" 1 "MR_Update_Only" 0 "No_MR_LR_Update" ;
VAL_ 1325 CAN_TX_TRACK_GROUPING_CHANGED 1 "GroupingChanged" 0 "GroupingUnchanged" ;
VAL_ 1325 CAN_TX_TRACK_BRIDGE_OBJECT 1 "Bridge" 0 "Not_Bridge" ;
VAL_ 1324 CAN_TX_TRACK_STATUS 7 "New_Coasted_Target" 6 "Invalid_Coasted_Target" 5 "Merged_Target" 4 "Coasted_Target" 3 "Updated_Target" 2 "New_Updated_Target" 1 "New_Target" 0 "No_Target" ;
VAL_ 1324 CAN_TX_TRACK_ONCOMING 1 "Oncoming" 0 "NotOncoming" ;
VAL_ 1324 CAN_TX_TRACK_MED_RANGE_MODE 3 "Both_MR_LR_Update" 2 "LR_Update_Only" 1 "MR_Update_Only" 0 "No_MR_LR_Update" ;
VAL_ 1324 CAN_TX_TRACK_GROUPING_CHANGED 1 "GroupingChanged" 0 "GroupingUnchanged" ;
VAL_ 1324 CAN_TX_TRACK_BRIDGE_OBJECT 1 "Bridge" 0 "Not_Bridge" ;
VAL_ 1323 CAN_TX_TRACK_STATUS 7 "New_Coasted_Target" 6 "Invalid_Coasted_Target" 5 "Merged_Target" 4 "Coasted_Target" 3 "Updated_Target" 2 "New_Updated_Target" 1 "New_Target" 0 "No_Target" ;
VAL_ 1323 CAN_TX_TRACK_ONCOMING 1 "Oncoming" 0 "NotOncoming" ;
VAL_ 1323 CAN_TX_TRACK_MED_RANGE_MODE 3 "Both_MR_LR_Update" 2 "LR_Update_Only" 1 "MR_Update_Only" 0 "No_MR_LR_Update" ;
VAL_ 1323 CAN_TX_TRACK_GROUPING_CHANGED 1 "GroupingChanged" 0 "GroupingUnchanged" ;
VAL_ 1323 CAN_TX_TRACK_BRIDGE_OBJECT 1 "Bridge" 0 "Not_Bridge" ;
VAL_ 1322 CAN_TX_TRACK_STATUS 7 "New_Coasted_Target" 6 "Invalid_Coasted_Target" 5 "Merged_Target" 4 "Coasted_Target" 3 "Updated_Target" 2 "New_Updated_Target" 1 "New_Target" 0 "No_Target" ;
VAL_ 1322 CAN_TX_TRACK_ONCOMING 1 "Oncoming" 0 "NotOncoming" ;
VAL_ 1322 CAN_TX_TRACK_MED_RANGE_MODE 3 "Both_MR_LR_Update" 2 "LR_Update_Only" 1 "MR_Update_Only" 0 "No_MR_LR_Update" ;
VAL_ 1322 CAN_TX_TRACK_GROUPING_CHANGED 1 "GroupingChanged" 0 "GroupingUnchanged" ;
VAL_ 1322 CAN_TX_TRACK_BRIDGE_OBJECT 1 "Bridge" 0 "Not_Bridge" ;
VAL_ 1321 CAN_TX_TRACK_STATUS 7 "New_Coasted_Target" 6 "Invalid_Coasted_Target" 5 "Merged_Target" 4 "Coasted_Target" 3 "Updated_Target" 2 "New_Updated_Target" 1 "New_Target" 0 "No_Target" ;
VAL_ 1321 CAN_TX_TRACK_ONCOMING 1 "Oncoming" 0 "NotOncoming" ;
VAL_ 1321 CAN_TX_TRACK_MED_RANGE_MODE 3 "Both_MR_LR_Update" 2 "LR_Update_Only" 1 "MR_Update_Only" 0 "No_MR_LR_Update" ;
VAL_ 1321 CAN_TX_TRACK_GROUPING_CHANGED 1 "GroupingChanged" 0 "GroupingUnchanged" ;
VAL_ 1321 CAN_TX_TRACK_BRIDGE_OBJECT 1 "Bridge" 0 "Not_Bridge" ;
VAL_ 1320 CAN_TX_TRACK_STATUS 7 "New_Coasted_Target" 6 "Invalid_Coasted_Target" 5 "Merged_Target" 4 "Coasted_Target" 3 "Updated_Target" 2 "New_Updated_Target" 1 "New_Target" 0 "No_Target" ;
VAL_ 1320 CAN_TX_TRACK_ONCOMING 1 "Oncoming" 0 "NotOncoming" ;
VAL_ 1320 CAN_TX_TRACK_MED_RANGE_MODE 3 "Both_MR_LR_Update" 2 "LR_Update_Only" 1 "MR_Update_Only" 0 "No_MR_LR_Update" ;
VAL_ 1320 CAN_TX_TRACK_GROUPING_CHANGED 1 "GroupingChanged" 0 "GroupingUnchanged" ;
VAL_ 1320 CAN_TX_TRACK_BRIDGE_OBJECT 1 "Bridge" 0 "Not_Bridge" ;
VAL_ 1319 CAN_TX_TRACK_STATUS 7 "New_Coasted_Target" 6 "Invalid_Coasted_Target" 5 "Merged_Target" 4 "Coasted_Target" 3 "Updated_Target" 2 "New_Updated_Target" 1 "New_Target" 0 "No_Target" ;
VAL_ 1319 CAN_TX_TRACK_ONCOMING 1 "Oncoming" 0 "NotOncoming" ;
VAL_ 1319 CAN_TX_TRACK_MED_RANGE_MODE 3 "Both_MR_LR_Update" 2 "LR_Update_Only" 1 "MR_Update_Only" 0 "No_MR_LR_Update" ;
VAL_ 1319 CAN_TX_TRACK_GROUPING_CHANGED 1 "GroupingChanged" 0 "GroupingUnchanged" ;
VAL_ 1319 CAN_TX_TRACK_BRIDGE_OBJECT 1 "Bridge" 0 "Not_Bridge" ;
VAL_ 1318 CAN_TX_TRACK_STATUS 7 "New_Coasted_Target" 6 "Invalid_Coasted_Target" 5 "Merged_Target" 4 "Coasted_Target" 3 "Updated_Target" 2 "New_Updated_Target" 1 "New_Target" 0 "No_Target" ;
VAL_ 1318 CAN_TX_TRACK_ONCOMING 1 "Oncoming" 0 "NotOncoming" ;
VAL_ 1318 CAN_TX_TRACK_MED_RANGE_MODE 3 "Both_MR_LR_Update" 2 "LR_Update_Only" 1 "MR_Update_Only" 0 "No_MR_LR_Update" ;
VAL_ 1318 CAN_TX_TRACK_GROUPING_CHANGED 1 "GroupingChanged" 0 "GroupingUnchanged" ;
VAL_ 1318 CAN_TX_TRACK_BRIDGE_OBJECT 1 "Bridge" 0 "Not_Bridge" ;
VAL_ 1317 CAN_TX_TRACK_STATUS 7 "New_Coasted_Target" 6 "Invalid_Coasted_Target" 5 "Merged_Target" 4 "Coasted_Target" 3 "Updated_Target" 2 "New_Updated_Target" 1 "New_Target" 0 "No_Target" ;
VAL_ 1317 CAN_TX_TRACK_ONCOMING 1 "Oncoming" 0 "NotOncoming" ;
VAL_ 1317 CAN_TX_TRACK_MED_RANGE_MODE 3 "Both_MR_LR_Update" 2 "LR_Update_Only" 1 "MR_Update_Only" 0 "No_MR_LR_Update" ;
VAL_ 1317 CAN_TX_TRACK_GROUPING_CHANGED 1 "GroupingChanged" 0 "GroupingUnchanged" ;
VAL_ 1317 CAN_TX_TRACK_BRIDGE_OBJECT 1 "Bridge" 0 "Not_Bridge" ;
VAL_ 1316 CAN_TX_TRACK_STATUS 7 "New_Coasted_Target" 6 "Invalid_Coasted_Target" 5 "Merged_Target" 4 "Coasted_Target" 3 "Updated_Target" 2 "New_Updated_Target" 1 "New_Target" 0 "No_Target" ;
VAL_ 1316 CAN_TX_TRACK_ONCOMING 1 "Oncoming" 0 "NotOncoming" ;
VAL_ 1316 CAN_TX_TRACK_MED_RANGE_MODE 3 "Both_MR_LR_Update" 2 "LR_Update_Only" 1 "MR_Update_Only" 0 "No_MR_LR_Update" ;
VAL_ 1316 CAN_TX_TRACK_GROUPING_CHANGED 1 "GroupingChanged" 0 "GroupingUnchanged" ;
VAL_ 1316 CAN_TX_TRACK_BRIDGE_OBJECT 1 "Bridge" 0 "Not_Bridge" ;
VAL_ 1315 CAN_TX_TRACK_STATUS 7 "New_Coasted_Target" 6 "Invalid_Coasted_Target" 5 "Merged_Target" 4 "Coasted_Target" 3 "Updated_Target" 2 "New_Updated_Target" 1 "New_Target" 0 "No_Target" ;
VAL_ 1315 CAN_TX_TRACK_ONCOMING 1 "Oncoming" 0 "NotOncoming" ;
VAL_ 1315 CAN_TX_TRACK_MED_RANGE_MODE 3 "Both_MR_LR_Update" 2 "LR_Update_Only" 1 "MR_Update_Only" 0 "No_MR_LR_Update" ;
VAL_ 1315 CAN_TX_TRACK_GROUPING_CHANGED 1 "GroupingChanged" 0 "GroupingUnchanged" ;
VAL_ 1315 CAN_TX_TRACK_BRIDGE_OBJECT 1 "Bridge" 0 "Not_Bridge" ;
VAL_ 1314 CAN_TX_TRACK_STATUS 7 "New_Coasted_Target" 6 "Invalid_Coasted_Target" 5 "Merged_Target" 4 "Coasted_Target" 3 "Updated_Target" 2 "New_Updated_Target" 1 "New_Target" 0 "No_Target" ;
VAL_ 1314 CAN_TX_TRACK_ONCOMING 1 "Oncoming" 0 "NotOncoming" ;
VAL_ 1314 CAN_TX_TRACK_MED_RANGE_MODE 3 "Both_MR_LR_Update" 2 "LR_Update_Only" 1 "MR_Update_Only" 0 "No_MR_LR_Update" ;
VAL_ 1314 CAN_TX_TRACK_GROUPING_CHANGED 1 "GroupingChanged" 0 "GroupingUnchanged" ;
VAL_ 1314 CAN_TX_TRACK_BRIDGE_OBJECT 1 "Bridge" 0 "Not_Bridge" ;
VAL_ 1313 CAN_TX_TRACK_STATUS 7 "New_Coasted_Target" 6 "Invalid_Coasted_Target" 5 "Merged_Target" 4 "Coasted_Target" 3 "Updated_Target" 2 "New_Updated_Target" 1 "New_Target" 0 "No_Target" ;
VAL_ 1313 CAN_TX_TRACK_ONCOMING 1 "Oncoming" 0 "NotOncoming" ;
VAL_ 1313 CAN_TX_TRACK_MED_RANGE_MODE 3 "Both_MR_LR_Update" 2 "LR_Update_Only" 1 "MR_Update_Only" 0 "No_MR_LR_Update" ;
VAL_ 1313 CAN_TX_TRACK_GROUPING_CHANGED 1 "GroupingChanged" 0 "GroupingUnchanged" ;
VAL_ 1313 CAN_TX_TRACK_BRIDGE_OBJECT 1 "Bridge" 0 "Not_Bridge" ;
VAL_ 1312 CAN_TX_TRACK_STATUS 7 "New_Coasted_Target" 6 "Invalid_Coasted_Target" 5 "Merged_Target" 4 "Coasted_Target" 3 "Updated_Target" 2 "New_Updated_Target" 1 "New_Target" 0 "No_Target" ;
VAL_ 1312 CAN_TX_TRACK_ONCOMING 1 "Oncoming" 0 "NotOncoming" ;
VAL_ 1312 CAN_TX_TRACK_MED_RANGE_MODE 3 "Both_MR_LR_Update" 2 "LR_Update_Only" 1 "MR_Update_Only" 0 "No_MR_LR_Update" ;
VAL_ 1312 CAN_TX_TRACK_GROUPING_CHANGED 1 "GroupingChanged" 0 "GroupingUnchanged" ;
VAL_ 1312 CAN_TX_TRACK_BRIDGE_OBJECT 1 "Bridge" 0 "Not_Bridge" ;
VAL_ 1311 CAN_TX_TRACK_STATUS 7 "New_Coasted_Target" 6 "Invalid_Coasted_Target" 5 "Merged_Target" 4 "Coasted_Target" 3 "Updated_Target" 2 "New_Updated_Target" 1 "New_Target" 0 "No_Target" ;
VAL_ 1311 CAN_TX_TRACK_ONCOMING 1 "Oncoming" 0 "NotOncoming" ;
VAL_ 1311 CAN_TX_TRACK_MED_RANGE_MODE 3 "Both_MR_LR_Update" 2 "LR_Update_Only" 1 "MR_Update_Only" 0 "No_MR_LR_Update" ;
VAL_ 1311 CAN_TX_TRACK_GROUPING_CHANGED 1 "GroupingChanged" 0 "GroupingUnchanged" ;
VAL_ 1311 CAN_TX_TRACK_BRIDGE_OBJECT 1 "Bridge" 0 "Not_Bridge" ;
VAL_ 1310 CAN_TX_TRACK_STATUS 7 "New_Coasted_Target" 6 "Invalid_Coasted_Target" 5 "Merged_Target" 4 "Coasted_Target" 3 "Updated_Target" 2 "New_Updated_Target" 1 "New_Target" 0 "No_Target" ;
VAL_ 1310 CAN_TX_TRACK_ONCOMING 1 "Oncoming" 0 "NotOncoming" ;
VAL_ 1310 CAN_TX_TRACK_MED_RANGE_MODE 3 "Both_MR_LR_Update" 2 "LR_Update_Only" 1 "MR_Update_Only" 0 "No_MR_LR_Update" ;
VAL_ 1310 CAN_TX_TRACK_GROUPING_CHANGED 1 "GroupingChanged" 0 "GroupingUnchanged" ;
VAL_ 1310 CAN_TX_TRACK_BRIDGE_OBJECT 1 "Bridge" 0 "Not_Bridge" ;
VAL_ 1309 CAN_TX_TRACK_STATUS 7 "New_Coasted_Target" 6 "Invalid_Coasted_Target" 5 "Merged_Target" 4 "Coasted_Target" 3 "Updated_Target" 2 "New_Updated_Target" 1 "New_Target" 0 "No_Target" ;
VAL_ 1309 CAN_TX_TRACK_ONCOMING 1 "Oncoming" 0 "NotOncoming" ;
VAL_ 1309 CAN_TX_TRACK_MED_RANGE_MODE 3 "Both_MR_LR_Update" 2 "LR_Update_Only" 1 "MR_Update_Only" 0 "No_MR_LR_Update" ;
VAL_ 1309 CAN_TX_TRACK_GROUPING_CHANGED 1 "GroupingChanged" 0 "GroupingUnchanged" ;
VAL_ 1309 CAN_TX_TRACK_BRIDGE_OBJECT 1 "Bridge" 0 "Not_Bridge" ;
VAL_ 1308 CAN_TX_TRACK_STATUS 7 "New_Coasted_Target" 6 "Invalid_Coasted_Target" 5 "Merged_Target" 4 "Coasted_Target" 3 "Updated_Target" 2 "New_Updated_Target" 1 "New_Target" 0 "No_Target" ;
VAL_ 1308 CAN_TX_TRACK_ONCOMING 1 "Oncoming" 0 "NotOncoming" ;
VAL_ 1308 CAN_TX_TRACK_MED_RANGE_MODE 3 "Both_MR_LR_Update" 2 "LR_Update_Only" 1 "MR_Update_Only" 0 "No_MR_LR_Update" ;
VAL_ 1308 CAN_TX_TRACK_GROUPING_CHANGED 1 "GroupingChanged" 0 "GroupingUnchanged" ;
VAL_ 1308 CAN_TX_TRACK_BRIDGE_OBJECT 1 "Bridge" 0 "Not_Bridge" ;
VAL_ 1307 CAN_TX_TRACK_ONCOMING 1 "Oncoming" 0 "NotOncoming" ;
VAL_ 1307 CAN_TX_TRACK_MED_RANGE_MODE 3 "Both_MR_LR_Update" 2 "LR_Update_Only" 1 "MR_Update_Only" 0 "No_MR_LR_Update" ;
VAL_ 1307 CAN_TX_TRACK_GROUPING_CHANGED 1 "GroupingChanged" 0 "GroupingUnchanged" ;
VAL_ 1307 CAN_TX_TRACK_BRIDGE_OBJECT 1 "Bridge" 0 "Not_Bridge" ;
